VERSION ""

NS_ :

BS_:

BU_: VMCU VGGSECUSystem TECU TACHO RECU_Virt HMIIOM GSSA EMS EBS DACU CIOM BBM ATCU ACM

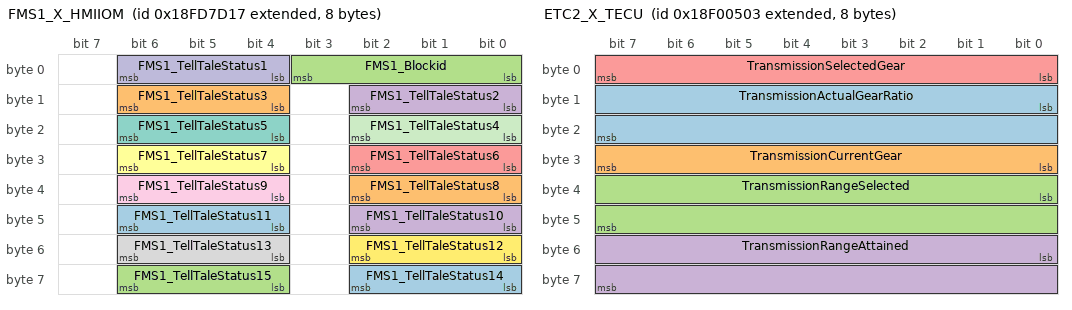
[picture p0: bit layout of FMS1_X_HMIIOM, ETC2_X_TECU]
BO_ 2566749463 FMS1_X_HMIIOM: 8 HMIIOM
 SG_ FMS1_TellTaleStatus11 : 44|3@1+ (1,0) [0|0] ""  CIOM
 SG_ FMS1_TellTaleStatus3 : 12|3@1+ (1,0) [0|0] ""  CIOM
 SG_ FMS1_Blockid : 0|4@1+ (1,0) [0|15] ""  CIOM
 SG_ FMS1_TellTaleStatus2 : 8|3@1+ (1,0) [0|0] ""  CIOM
 SG_ FMS1_TellTaleStatus6 : 24|3@1+ (1,0) [0|0] ""  CIOM
 SG_ FMS1_TellTaleStatus7 : 28|3@1+ (1,0) [0|0] ""  CIOM
 SG_ FMS1_TellTaleStatus5 : 20|3@1+ (1,0) [0|0] ""  CIOM
 SG_ FMS1_TellTaleStatus13 : 52|3@1+ (1,0) [0|0] ""  CIOM
 SG_ FMS1_TellTaleStatus9 : 36|3@1+ (1,0) [0|0] ""  CIOM
 SG_ FMS1_TellTaleStatus1 : 4|3@1+ (1,0) [0|0] ""  CIOM
 SG_ FMS1_TellTaleStatus4 : 16|3@1+ (1,0) [0|0] ""  CIOM
 SG_ FMS1_TellTaleStatus12 : 48|3@1+ (1,0) [0|0] ""  CIOM
 SG_ FMS1_TellTaleStatus14 : 56|3@1+ (1,0) [0|0] ""  CIOM
 SG_ FMS1_TellTaleStatus8 : 32|3@1+ (1,0) [0|0] ""  CIOM
 SG_ FMS1_TellTaleStatus15 : 60|3@1+ (1,0) [0|0] ""  CIOM
 SG_ FMS1_TellTaleStatus10 : 40|3@1+ (1,0) [0|0] ""  CIOM

BO_ 2364541955 ETC8_X_TCU: 8 Vector__XXX

BO_ 2566801923 ETC7_X_TECU: 8 TECU
 SG_ TransmissionRequestedGearFdbk : 24|8@1+ (1,-125) [-125|130] "GearValue"  HMIIOM
 SG_ TransmEngineCrankEnable2 : 12|2@1+ (1,0) [0|0] ""  VMCU

BO_ 2565866755 ETC2_X_TECU: 8 TECU
 SG_ TransmissionActualGearRatio : 8|16@1+ (0.001,0) [0|65.535] "NotApplicable"  BBM,DACU,EMS,VMCU
 SG_ TransmissionCurrentGear : 24|8@1+ (1,-125) [-125|130] "GearValue"  EMS,BBM,VMCU,EBS,HMIIOM
 SG_ TransmissionRangeSelected : 32|16@1+ (1,0) [0|0] ""  VMCU,HMIIOM,BBM
 SG_ TransmissionRangeAttained : 48|16@1+ (1,0) [0|0] ""  BBM,HMIIOM
 SG_ TransmissionSelectedGear : 0|8@1+ (1,-125) [-125|130] "GearValue"  EMS,BBM,HMIIOM,VMCU

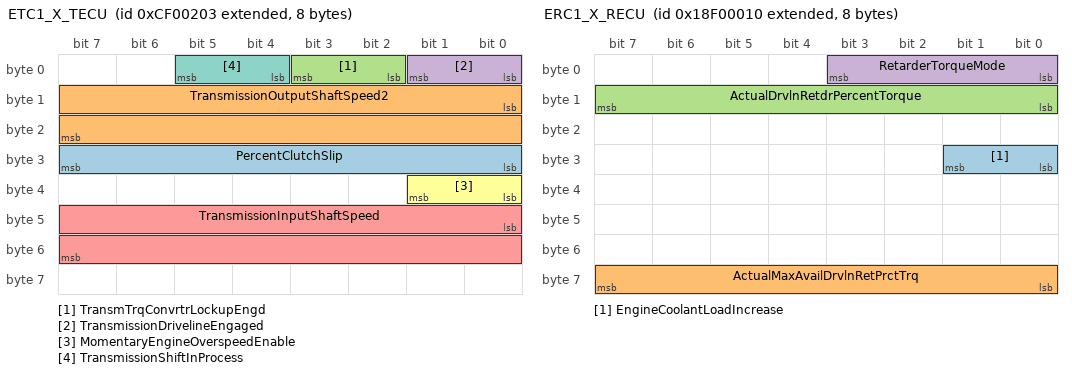
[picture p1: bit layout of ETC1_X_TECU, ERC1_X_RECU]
BO_ 2364539395 ETC1_X_TECU: 8 TECU
 SG_ PercentClutchSlip : 24|8@1+ (0.4,0) [0|102] "Percent"  EBS,EMS,VMCU,BBM
 SG_ TransmissionOutputShaftSpeed2 : 8|16@1+ (0.125,0) [0|8191.875] "rpm"  VMCU
 SG_ TransmTrqConvrtrLockupEngd : 2|2@1+ (1,0) [0|0] ""  EMS,BBM
 SG_ TransmissionDrivelineEngaged : 0|2@1+ (1,0) [0|0] ""  EMS,VMCU,BBM,DACU,EBS
 SG_ TransmissionInputShaftSpeed : 40|16@1+ (0.125,0) [0|8191.875] "rpm"  BBM,EBS
 SG_ MomentaryEngineOverspeedEnable : 32|2@1+ (1,0) [0|0] ""  BBM,EMS
 SG_ TransmissionShiftInProcess : 4|2@1+ (1,0) [0|0] ""  EMS,VMCU,EBS,BBM,DACU

BO_ 2566843904 ET1_X_EMS: 8 EMS
 SG_ EngineOilTemperature : 16|16@1+ (0.03125,-273) [-273|1774.96875] "DegreeC"  VGGSECUSystem,HMIIOM,BBM,TECU
 SG_ EngineCoolantTemp_stat : 0|8@1+ (1,-40) [-40|215] "DegreeC"  CIOM,HMIIOM,VMCU,TECU,VGGSECUSystem,ACM,BBM

BO_ 2558984359 ESR_EMS_VGGS: 8 VGGSECUSystem
 SG_ RequestedFuelTypeVGGS : 8|8@1+ (1,0) [0|0] ""  EMS

BO_ 2565865488 ERC1_X_RECU: 8 RECU_Virt
 SG_ EngineCoolantLoadIncrease : 24|2@1+ (1,0) [0|0] ""  EMS
 SG_ ActualMaxAvailDrvlnRetPrctTrq : 56|8@1+ (1,-125) [-125|130] "Percent"  EMS,EBS,VMCU,TECU
 SG_ ActualDrvlnRetdrPercentTorque : 8|8@1+ (1,-125) [-125|130] "Percent"  EMS,CIOM,VMCU,TECU,EBS,HMIIOM
 SG_ RetarderTorqueMode : 0|4@1+ (1,0) [0|0] ""  CIOM,HMIIOM,EMS

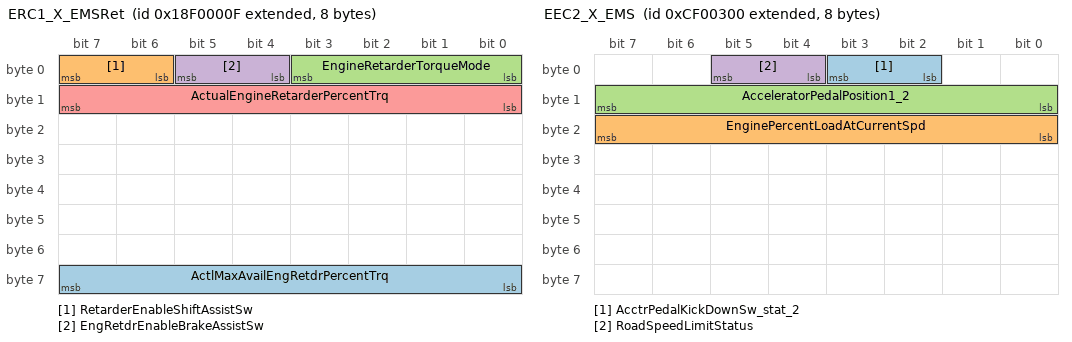
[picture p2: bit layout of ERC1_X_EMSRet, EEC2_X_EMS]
BO_ 2565865487 ERC1_X_EMSRet: 8 EMS
 SG_ ActlMaxAvailEngRetdrPercentTrq : 56|8@1+ (1,-125) [-125|130] "Percent"  VMCU,EBS
 SG_ RetarderEnableShiftAssistSw : 6|2@1+ (1,0) [0|0] ""  TECU
 SG_ EngineRetarderTorqueMode : 0|4@1+ (1,0) [0|0] ""  CIOM,HMIIOM
 SG_ EngRetdrEnableBrakeAssistSw : 4|2@1+ (1,0) [0|0] ""  TECU
 SG_ ActualEngineRetarderPercentTrq : 8|8@1+ (1,-125) [-125|130] "Percent"  RECU_Virt,CIOM,EBS,HMIIOM,VMCU,TECU,VGGSECUSystem

BO_ 2364541440 EGF1_X_EMS: 8 EMS
 SG_ EngineIntakeAirRate : 16|16@1+ (0.05,0) [0|3276.75] "Kg_per_h"  VMCU

BO_ 2566844160 EFLP1_X_EMS: 8 EMS
 SG_ EngineOilLevel : 16|8@1+ (0.4,0) [0|102] "Percent"  VGGSECUSystem,BBM,HMIIOM
 SG_ EngineOilPressure : 24|8@1+ (4,0) [0|1020] "kPa"  VMCU,HMIIOM,VGGSECUSystem,BBM

BO_ 2566840064 EEC3_X_EMS: 8 EMS
 SG_ NominalFrictionPercentTorque : 0|8@1+ (1,-125) [-125|130] "Percent"  VMCU,VGGSECUSystem,TECU,DACU,EBS,RECU_Virt

BO_ 2364539648 EEC2_X_EMS: 8 EMS
 SG_ AcctrPedalKickDownSw_stat_2 : 2|2@1+ (1,0) [0|0] ""  VGGSECUSystem
 SG_ EnginePercentLoadAtCurrentSpd : 16|8@1+ (1,0) [0|255] "Percent"  ACM,HMIIOM,BBM,CIOM,VMCU,TECU
 SG_ AcceleratorPedalPosition1_2 : 8|8@1+ (0.4,0) [0|102] "Percent"  VGGSECUSystem,TECU
 SG_ RoadSpeedLimitStatus : 4|2@1+ (1,0) [0|0] ""  TECU

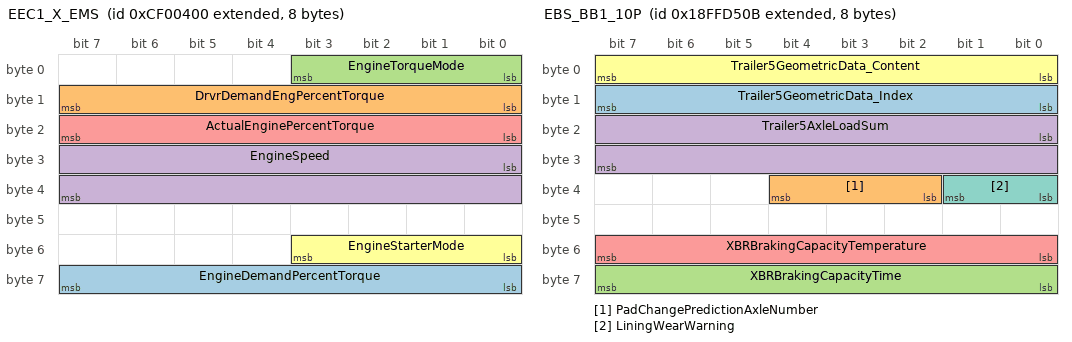
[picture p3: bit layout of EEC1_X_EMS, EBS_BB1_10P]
BO_ 2364539904 EEC1_X_EMS: 8 EMS
 SG_ EngineDemandPercentTorque : 56|8@1+ (1,-125) [-125|130] "Percent"  TECU,VMCU
 SG_ DrvrDemandEngPercentTorque : 8|8@1+ (1,-125) [-125|130] "Percent"  BBM,TECU,EBS,VMCU
 SG_ EngineTorqueMode : 0|4@1+ (1,0) [0|0] ""  TECU,VMCU,BBM,EBS,HMIIOM
 SG_ EngineSpeed : 24|16@1+ (0.125,0) [0|8191.875] "rpm"  BBM,DACU,HMIIOM,VMCU,VGGSECUSystem,EBS,ACM,TECU,CIOM
 SG_ ActualEnginePercentTorque : 16|8@1+ (1,-125) [-125|130] "Percent"  HMIIOM,VMCU,EBS,CIOM,TECU,BBM,DACU
 SG_ EngineStarterMode : 48|4@1+ (1,0) [0|0] ""  VMCU,BBM,HMIIOM

BO_ 2566767104 EEC14_X_EMS: 8 EMS
 SG_ FuelTypeEMS : 48|8@1+ (1,0) [0|0] ""  VGGSECUSystem

BO_ 2566841088 EC1_X_EMS: 39 EMS
 SG_ EngConf_EngSpeedAtHighIdle_P6 : 120|16@1+ (0.125,0) [0|8191.875] "rpm"  TECU
 SG_ EngConf_EngTorqueAt_P4 : 88|8@1+ (1,-125) [-125|130] "Percent"  TECU
 SG_ EngConf_EngMaxMomOvSpeed_P7 : 168|16@1+ (0.125,0) [0|8191.875] "rpm"  TECU
 SG_ EngConf_EngTorqueAt_P5 : 112|8@1+ (1,-125) [-125|130] "Percent"  TECU
 SG_ EngConf_EngSpeedAtIdle_P1 : 0|16@1+ (0.125,0) [0|8191.875] "rpm"  TECU
 SG_ EngineReferenceTorque : 152|16@1+ (1,0) [0|65535] "Nm"  TECU,RECU_Virt,VGGSECUSystem,DACU,EBS,VMCU
 SG_ EngConf_EngSpeedAt_P2 : 24|16@1+ (0.125,0) [0|8191.875] "rpm"  TECU
 SG_ EngConf_MaxMomOverrideTimeLim : 184|8@1+ (0.1,0) [0|25.5] "s"  TECU
 SG_ EngConf_EngSpeedAt_P5 : 96|16@1+ (0.125,0) [0|8191.875] "rpm"  TECU
 SG_ EngConf_EngTorqueAtIdle_P1 : 16|8@1+ (1,-125) [-125|130] "Percent"  TECU
 SG_ EngConf_EngSpeedAt_P4 : 72|16@1+ (0.125,0) [0|8191.875] "rpm"  TECU
 SG_ EngConf_EngSpeedAt_P3 : 48|16@1+ (0.125,0) [0|8191.875] "rpm"  TECU
 SG_ EngConf_EngTorqueAt_P3 : 64|8@1+ (1,-125) [-125|130] "Percent"  TECU
 SG_ EngConf_EngTorqueAt_P2 : 40|8@1+ (1,-125) [-125|130] "Percent"  TECU

BO_ 2566894859 EBS_BB1_15P: 17 EBS
 SG_ Trailer5VIN : 0|136@1+ (1,0) [0|0] ""  HMIIOM

BO_ 2566894603 EBS_BB1_14P: 17 EBS
 SG_ Trailer4VIN : 0|136@1+ (1,0) [0|0] ""  HMIIOM

BO_ 2566894347 EBS_BB1_13P: 17 EBS
 SG_ Trailer3VIN : 0|136@1+ (1,0) [0|0] ""  HMIIOM

BO_ 2566894091 EBS_BB1_12P: 17 EBS
 SG_ Trailer2VIN : 0|136@1+ (1,0) [0|0] ""  HMIIOM

BO_ 2566893835 EBS_BB1_11P: 17 EBS
 SG_ Trailer1VIN : 0|136@1+ (1,0) [0|0] ""  HMIIOM

BO_ 2566903051 EBS_BB1_10P: 8 EBS
 SG_ Trailer5GeometricData_Index : 8|8@1+ (1,0) [0|0] ""  HMIIOM
 SG_ PadChangePredictionAxleNumber : 34|3@1+ (1,0) [0|0] ""  VMCU
 SG_ XBRBrakingCapacityTime : 56|8@1+ (1,0) [0|255] "s"  EMS,TECU,DACU
 SG_ Trailer5AxleLoadSum : 16|16@1+ (2,0) [0|131070] "kg"  HMIIOM
 SG_ XBRBrakingCapacityTemperature : 48|8@1+ (0.4,0) [0|102] "Percent"  TECU,DACU,EMS
 SG_ Trailer5GeometricData_Content : 0|8@1+ (1,0) [0|255] ""  HMIIOM
 SG_ LiningWearWarning : 32|2@1+ (1,0) [0|0] ""  VGGSECUSystem,HMIIOM

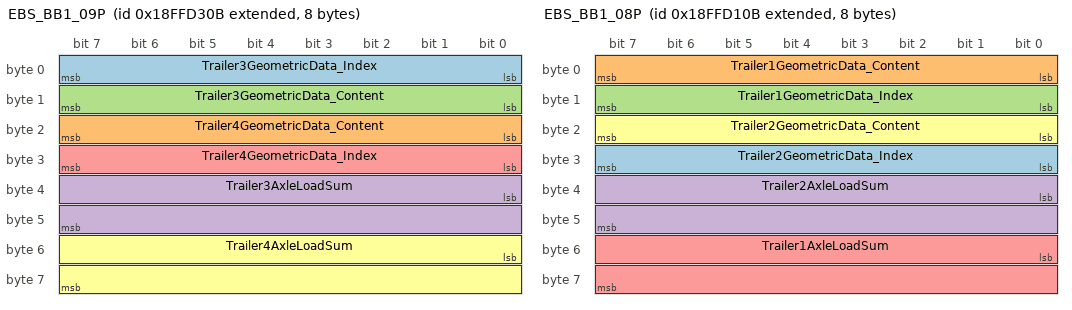
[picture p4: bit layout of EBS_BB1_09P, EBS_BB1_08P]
BO_ 2566902539 EBS_BB1_09P: 8 EBS
 SG_ Trailer3GeometricData_Index : 0|8@1+ (1,0) [0|0] ""  HMIIOM
 SG_ Trailer4GeometricData_Content : 16|8@1+ (1,0) [0|255] ""  HMIIOM
 SG_ Trailer3GeometricData_Content : 8|8@1+ (1,0) [0|255] ""  HMIIOM
 SG_ Trailer3AxleLoadSum : 32|16@1+ (2,0) [0|131070] "kg"  HMIIOM,TECU
 SG_ Trailer4GeometricData_Index : 24|8@1+ (1,0) [0|0] ""  HMIIOM
 SG_ Trailer4AxleLoadSum : 48|16@1+ (2,0) [0|131070] "kg"  TECU,HMIIOM

BO_ 2566902027 EBS_BB1_08P: 8 EBS
 SG_ Trailer2GeometricData_Index : 24|8@1+ (1,0) [0|0] ""  HMIIOM
 SG_ Trailer1GeometricData_Content : 0|8@1+ (1,0) [0|255] ""  HMIIOM
 SG_ Trailer1GeometricData_Index : 8|8@1+ (1,0) [0|0] ""  HMIIOM
 SG_ Trailer2AxleLoadSum : 32|16@1+ (2,0) [0|131070] "kg"  TECU,HMIIOM
 SG_ Trailer1AxleLoadSum : 48|16@1+ (2,0) [0|131070] "kg"  HMIIOM,TECU
 SG_ Trailer2GeometricData_Content : 16|8@1+ (1,0) [0|255] ""  HMIIOM

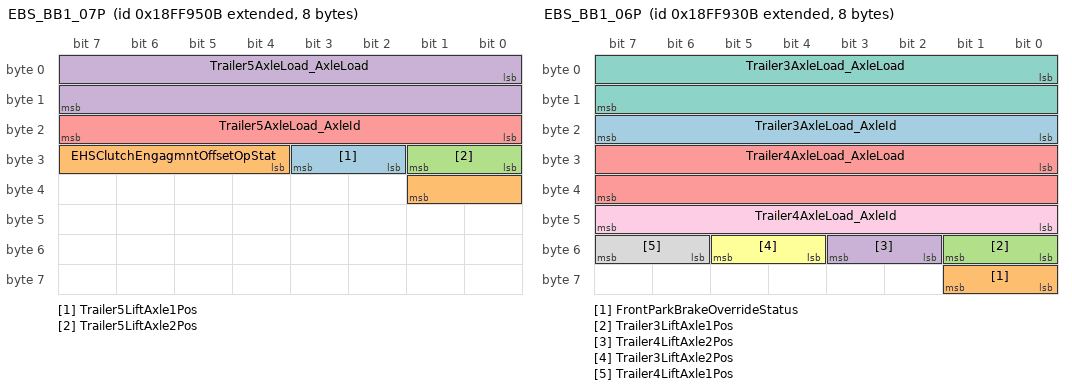
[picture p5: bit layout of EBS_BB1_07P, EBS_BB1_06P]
BO_ 2566886667 EBS_BB1_07P: 8 EBS
 SG_ Trailer5LiftAxle1Pos : 26|2@1+ (1,0) [0|0] ""  BBM,HMIIOM
 SG_ EHSClutchEngagmntOffsetOpStat : 28|6@1+ (1,-30) [-30|33] "Step"  HMIIOM
 SG_ Trailer5LiftAxle2Pos : 24|2@1+ (1,0) [0|0] ""  BBM,HMIIOM
 SG_ Trailer5AxleLoad_AxleLoad : 0|16@1+ (0.5,0) [0|32767.5] "kg"  BBM,HMIIOM
 SG_ Trailer5AxleLoad_AxleId : 16|8@1+ (1,0) [0|255] "NotApplicable"  BBM,HMIIOM

BO_ 2566886155 EBS_BB1_06P: 8 EBS
 SG_ Trailer3AxleLoad_AxleId : 16|8@1+ (1,0) [0|255] "NotApplicable"  BBM,HMIIOM
 SG_ FrontParkBrakeOverrideStatus : 56|2@1+ (1,0) [0|0] ""  HMIIOM
 SG_ Trailer3LiftAxle1Pos : 48|2@1+ (1,0) [0|0] ""  BBM,HMIIOM
 SG_ Trailer4LiftAxle2Pos : 50|2@1+ (1,0) [0|0] ""  BBM,HMIIOM
 SG_ Trailer4AxleLoad_AxleLoad : 24|16@1+ (0.5,0) [0|32767.5] "kg"  BBM,HMIIOM
 SG_ Trailer3LiftAxle2Pos : 52|2@1+ (1,0) [0|0] ""  BBM,HMIIOM
 SG_ Trailer3AxleLoad_AxleLoad : 0|16@1+ (0.5,0) [0|32767.5] "kg"  BBM,HMIIOM
 SG_ Trailer4LiftAxle1Pos : 54|2@1+ (1,0) [0|0] ""  HMIIOM,BBM
 SG_ Trailer4AxleLoad_AxleId : 40|8@1+ (1,0) [0|255] "NotApplicable"  HMIIOM,BBM

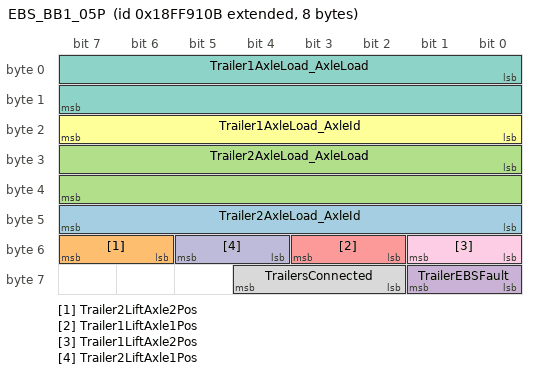
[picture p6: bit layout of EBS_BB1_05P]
BO_ 2566885643 EBS_BB1_05P: 8 EBS
 SG_ Trailer2AxleLoad_AxleId : 40|8@1+ (1,0) [0|255] "NotApplicable"  BBM,HMIIOM
 SG_ Trailer2LiftAxle2Pos : 54|2@1+ (1,0) [0|0] ""  HMIIOM,BBM
 SG_ Trailer2AxleLoad_AxleLoad : 24|16@1+ (0.5,0) [0|32767.5] "kg"  HMIIOM,BBM
 SG_ TrailerEBSFault : 56|2@1+ (1,0) [0|0] ""  VGGSECUSystem,HMIIOM
 SG_ Trailer1LiftAxle1Pos : 50|2@1+ (1,0) [0|0] ""  BBM,HMIIOM
 SG_ Trailer1AxleLoad_AxleId : 16|8@1+ (1,0) [0|255] "NotApplicable"  HMIIOM,BBM
 SG_ Trailer1AxleLoad_AxleLoad : 0|16@1+ (0.5,0) [0|32767.5] "kg"  BBM,HMIIOM
 SG_ TrailersConnected : 58|3@1+ (1,0) [0|7] "Count"  VGGSECUSystem,HMIIOM,CIOM,TECU
 SG_ Trailer1LiftAxle2Pos : 48|2@1+ (1,0) [0|0] ""  HMIIOM,BBM
 SG_ Trailer2LiftAxle1Pos : 52|2@1+ (1,0) [0|0] ""  HMIIOM,BBM

BO_ 2566906635 EBS_BB1_04P: 8 EBS
 SG_ PredictedMileageOfNextPadChg : 0|32@1+ (1,0) [0|4294967295] "km"  HMIIOM,VMCU
 SG_ PadChgPredictionLastPadChg : 32|32@1+ (1,0) [0|4294967295] "km"  VMCU

BO_ 2499761675 EBS_BB1_02P: 8 EBS
 SG_ BadBrakeBalanceWarning : 12|2@1+ (1,0) [0|0] ""  HMIIOM
 SG_ HSAAvailability : 22|2@1+ (1,0) [0|0] ""  BBM,TECU
 SG_ DTCActive : 6|2@1+ (1,0) [0|0] ""  HMIIOM
 SG_ StretchBrake_Stat : 58|3@1+ (1,0) [0|0] ""  HMIIOM,VMCU
 SG_ TrcnCtrlSlipperyRoadWarning : 4|2@1+ (1,0) [0|0] ""  BBM,HMIIOM
 SG_ RearAxleDiffLockActvnFuncReq : 10|2@1+ (1,0) [0|0] ""  VMCU
 SG_ BrakeTempWarningLevel : 24|8@1+ (1,0) [0|255] "Percent"  VMCU,DACU,TECU,EMS
 SG_ RollerBenchModeStatus : 0|2@1+ (1,0) [0|0] ""  DACU,HMIIOM,VMCU,VGGSECUSystem
 SG_ BrakeAssistStatus : 8|2@1+ (1,0) [0|0] ""  VMCU
 SG_ LongitudinalAcceleration : 32|16@1+ (0.00048828125,-15.687) [-15.687|16.31251171875] "m_per_s_squared"  BBM
 SG_ TractionFunctionSelected : 53|3@1+ (1,0) [0|0] ""  HMIIOM
 SG_ PoorBrakePerformanceWarning : 14|2@1+ (1,0) [0|0] ""  HMIIOM
 SG_ VDCActive : 56|2@1+ (1,0) [0|0] ""  VMCU,HMIIOM
 SG_ ABSInhibitionStatus : 16|2@1+ (1,0) [0|0] ""  VGGSECUSystem,TECU,CIOM,VMCU,HMIIOM
 SG_ ABSManAutoInhibitionStat : 61|3@1+ (1,0) [0|0] ""  HMIIOM,VGGSECUSystem
 SG_ RearAxleSteeringFunctionStatus : 50|3@1+ (1,0) [0|0] ""  DACU,CIOM
 SG_ AutoRearAxleDiffLockFnc_stat : 48|2@1+ (1,0) [0|0] ""  HMIIOM
 SG_ RearAxleDiffLockActvnFuncReq_UB : 2|1@1+ (1,0) [0|0] ""  VMCU
 SG_ WheelBrakeWarning : 20|2@1+ (1,0) [0|0] ""  HMIIOM

CM_ BO_ 2566749463 "PGN 64893 FMS Telltale status";
CM_ SG_ 2566749463 FMS1_Blockid "15: Don't care";
CM_ BO_ 2364541955 "PGN61452 Electronic Transmission Controller #8";
CM_ BO_ 2566801923 "PGN 65098 Electronic Transmission Controller 7";
CM_ BO_ 2565866755 "PGN 61445 Electronic Transmission Controller 2";
CM_ SG_ 2565866755 TransmissionActualGearRatio "65024 - 65279 Error ; 65280 - 65535 Not available";
CM_ SG_ 2565866755 TransmissionCurrentGear "254 Error ; 255 Not available";
CM_ SG_ 2565866755 TransmissionSelectedGear "254 Error ; 255 Not available";
CM_ BO_ 2364539395 "PGN 61442 Electronic Transmission Controller 1";
CM_ SG_ 2364539395 PercentClutchSlip "254 Error ; 255 Not available";
CM_ SG_ 2364539395 TransmissionInputShaftSpeed "65024 - 65279 Error ; 65280 - 65535 Not available";
CM_ BO_ 2566843904 "PGN 65262 Engine Temperature 1";
CM_ SG_ 2566843904 EngineOilTemperature "65024 - 65279 Error ; 65280 - 65535 Not available";
CM_ SG_ 2566843904 EngineCoolantTemp_stat "254 Error ; 255 Not available";
CM_ BO_ 2558984359 "PGN 34560 Engine State Requests";
CM_ BO_ 2565865488 "PGN 61440 Electronic Retarder Controller 1 from RECU";
CM_ SG_ 2565865488 ActualMaxAvailDrvlnRetPrctTrq "254 Error ; 255 Not available";
CM_ SG_ 2565865488 ActualDrvlnRetdrPercentTorque "254 Error ; 255 Not available";
CM_ BO_ 2565865487 "PGN 61440 Electronic Retarder Controller 1";
CM_ SG_ 2565865487 ActlMaxAvailEngRetdrPercentTrq "254 Error ; 255 Not available";
CM_ SG_ 2565865487 ActualEngineRetarderPercentTrq "254 Error ; 255 Not available";
CM_ BO_ 2364541440 "PGN 61450 Flow rates of Air and mixed gasses into the engine cylinders.
Note: SAE recommended rate 50ms, but 500ms set due to current usage only for logging.";
CM_ BO_ 2566844160 "PGN 65263 Engine Fluid Level/Pressure 1";
CM_ SG_ 2566844160 EngineOilLevel "254 Error ; 255 Not available";
CM_ SG_ 2566844160 EngineOilPressure "254 Error ; 255 Not available";
CM_ BO_ 2566840064 "PGN 65247 Electronic Engine Controller 3";
CM_ SG_ 2566840064 NominalFrictionPercentTorque "254 Error ; 255 Not available";
CM_ BO_ 2364539648 "PGN 61443 Electronic Engine Controller 2";
CM_ SG_ 2364539648 EnginePercentLoadAtCurrentSpd "254 Error ; 255 Not available";
CM_ BO_ 2364539904 "PGN 61444 Electronic Engine Controller 1";
CM_ SG_ 2364539904 DrvrDemandEngPercentTorque "254 Error ; 255 Not available";
CM_ SG_ 2364539904 EngineSpeed "65024 - 65279 Error ; 65280 - 65535 Not available";
CM_ SG_ 2364539904 ActualEnginePercentTorque "254 Error ; 255 Not available";
CM_ BO_ 2566767104 "PGN 64962 Electronic Engine Controller 14";
CM_ BO_ 2566841088 "PGN 65251 Engine Configuration 1";
CM_ SG_ 2566841088 EngConf_EngSpeedAtHighIdle_P6 "65024 - 65279 Error ; 65280 - 65535 Not available";
CM_ SG_ 2566841088 EngConf_EngTorqueAt_P4 "254 Error ; 255 Not available";
CM_ SG_ 2566841088 EngConf_EngMaxMomOvSpeed_P7 "65024 - 65279 Error ; 65280 - 65535 Not available";
CM_ SG_ 2566841088 EngConf_EngTorqueAt_P5 "254 Error ; 255 Not available";
CM_ SG_ 2566841088 EngConf_EngSpeedAtIdle_P1 "65024 - 65279 Error ; 65280 - 65535 Not available";
CM_ SG_ 2566841088 EngineReferenceTorque "65024 - 65279 Error ; 65280 - 65535 Not available";
CM_ SG_ 2566841088 EngConf_EngSpeedAt_P2 "65024 - 65279 Error ; 65280 - 65535 Not available";
CM_ SG_ 2566841088 EngConf_MaxMomOverrideTimeLim "254 Error ; 255 Not available";
CM_ SG_ 2566841088 EngConf_EngSpeedAt_P5 "65024 - 65279 Error ; 65280 - 65535 Not available";
CM_ SG_ 2566841088 EngConf_EngTorqueAtIdle_P1 "254 Error ; 255 Not available";
CM_ SG_ 2566841088 EngConf_EngSpeedAt_P4 "65024 - 65279 Error ; 65280 - 65535 Not available";
CM_ SG_ 2566841088 EngConf_EngSpeedAt_P3 "65024 - 65279 Error ; 65280 - 65535 Not available";
CM_ SG_ 2566841088 EngConf_EngTorqueAt_P3 "254 Error ; 255 Not available";
CM_ SG_ 2566841088 EngConf_EngTorqueAt_P2 "254 Error ; 255 Not available";
CM_ SG_ 2566903051 Trailer5AxleLoadSum "65024 - 65279 Error ; 65280 - 65535 Not Available";
CM_ SG_ 2566903051 Trailer5GeometricData_Content "254 Error ; 255 Not Available";
CM_ SG_ 2566902539 Trailer4GeometricData_Content "254 Error ; 255 Not Available";
CM_ SG_ 2566902539 Trailer3GeometricData_Content "254 Error ; 255 Not Available";
CM_ SG_ 2566902539 Trailer3AxleLoadSum "65024 - 65279 Error ; 65280 - 65535 Not Available";
CM_ SG_ 2566902539 Trailer4AxleLoadSum "65024 - 65279 Error ; 65280 - 65535 Not Available";
CM_ SG_ 2566902027 Trailer1GeometricData_Content "254 Error ; 255 Not Available";
CM_ SG_ 2566902027 Trailer2AxleLoadSum "65024 - 65279 Error ; 65280 - 65535 Not Available";
CM_ SG_ 2566902027 Trailer1AxleLoadSum "65024 - 65279 Error ; 65280 - 65535 Not Available";
CM_ SG_ 2566902027 Trailer2GeometricData_Content "254 Error ; 255 Not Available";
CM_ SG_ 2566886667 Trailer5AxleLoad_AxleLoad "65024 - 65279 Error ; 65280 - 65535 Not available";
CM_ SG_ 2566886155 Trailer4AxleLoad_AxleLoad "65024 - 65279 Error ; 65280 - 65535 Not available";
CM_ SG_ 2566886155 Trailer3AxleLoad_AxleLoad "65024 - 65279 Error ; 65280 - 65535 Not available";
CM_ SG_ 2566885643 Trailer2AxleLoad_AxleLoad "65024 - 65279 Error ; 65280 - 65535 Not available";
CM_ SG_ 2566885643 Trailer1AxleLoad_AxleLoad "65024 - 65279 Error ; 65280 - 65535 Not available";
CM_ SG_ 2566885643 TrailersConnected "6 Error ; 7 Not available";
CM_ SG_ 2566906635 PredictedMileageOfNextPadChg "4261412864 - 4278190079 Error ; 4278190080 - 4294967295 Not available";
CM_ SG_ 2566906635 PadChgPredictionLastPadChg "4261412864 - 4278190079 Error ; 4278190080 - 4294967295 Not available";
CM_ SG_ 2499761675 BrakeTempWarningLevel "254 Error ; 255 Not available";
CM_ SG_ 2499761675 LongitudinalAcceleration "65024 - 65279 Error ; 65280 - 65535 Not available";
BA_DEF_ BO_  "GenMsgStartDelayTime" INT 0 0;
BA_DEF_ BO_  "GenMsgDelayTime" INT 0 0;
BA_DEF_ BO_  "GenMsgNrOfRepetition" INT 0 0;
BA_DEF_ BO_  "GenMsgCycleTimeFast" INT 0 0;
BA_DEF_ BO_  "GenMsgCycleTime" INT 0 0;
BA_DEF_ BO_  "GenMsgSendType" ENUM  "Cyclic","NotUsed","NotUsed","NotUsed","NotUsed","NotUsed","NotUsed","IfActive","NoMsgSendType","NotUsed";
BA_DEF_ SG_  "GenSigStartValue" INT 0 0;
BA_DEF_ SG_  "GenSigCycleTimeActive" INT 0 0;
BA_DEF_ SG_  "GenSigCycleTime" INT 0 0;
BA_DEF_ SG_  "GenSigSendType" ENUM  "Cyclic","OnWrite","OnWriteWithRepetition","OnChange","OnChangeWithRepetition","IfActive","IfActiveWithRepetition","NoSigSendType","NotUsed","NotUsed","NotUsed","NotUsed","NotUsed";
BA_DEF_ BO_  "VFrameFormat" ENUM  "StandardCAN","ExtendedCAN","reserved","J1939PG";
BA_DEF_ BO_  "TpJ1939VarDlc" ENUM  "No","Yes";
BA_DEF_ SG_  "SigType" ENUM  "Default","Range","RangeSigned","ASCII","Discrete","Control","ReferencePGN","DTC","StringDelimiter","StringLength","StringLengthControl";
BA_DEF_ SG_  "SeToolVersion_SIGNAL" STRING ;
BA_DEF_ SG_  "SeToolUniqueID_SIGNAL" STRING ;
BA_DEF_ SG_  "SeToolOwnerSigGroup_SIGNAL" STRING ;
BA_DEF_ SG_  "SeToolOwnerSigGroupID_SIGNAL" STRING ;
BA_DEF_ SG_  "SeToolName_SIGNAL" STRING ;
BA_DEF_ SG_  "SeToolItemID_SIGNAL" STRING ;
BA_DEF_ SG_  "SeToolAncestorID_SIGNAL" STRING ;
BA_DEF_ SG_  "SPN" INT 0 524287;
BA_DEF_ SG_  "Platform_VMCU1_Sig" ENUM  "No","Yes";
BA_DEF_ SG_  "Platform_FactoryIf_Sig" ENUM  "No","Yes";
BA_DEF_ SG_  "NeedsUpdateBit" ENUM  "No","Yes";
BA_DEF_ SG_  "GenSigMaxLatency" INT 0 65535;
BA_DEF_ SG_  "GenSigILSupport" ENUM  "Yes","No";
BA_DEF_ BO_  "GenMsgRequestable" INT 0 1;
BA_DEF_ BO_  "GenMsgILSupport" ENUM  "No","Yes";
BA_DEF_ BO_  "DiagUUDTResponse" ENUM  "No","Yes";
BA_DEF_ BO_  "DiagState" ENUM  "No","Yes";
BA_DEF_ BO_  "DiagResponse" ENUM  "No","Yes";
BA_DEF_ BO_  "DiagRequest" ENUM  "No","Yes";
BA_DEF_ BO_  "DiagConnection" HEX 0 65535;
BA_DEF_ BO_  "CanTpFcFrameId" HEX 0 2147483647;
BA_DEF_ BO_  "CanTpBs" INT 0 255;
BA_DEF_ SG_  "SystemSignalLongSymbol" STRING ;
BA_DEF_REL_ BU_SG_REL_  "GenSigTimeoutTime" INT 0 65535;
BA_DEF_REL_ BU_SG_REL_  "GenSigFirstTimeoutTime" INT 0 65535;
BA_DEF_DEF_  "GenMsgStartDelayTime" 0;
BA_DEF_DEF_  "GenMsgDelayTime" 0;
BA_DEF_DEF_  "GenMsgNrOfRepetition" 0;
BA_DEF_DEF_  "GenMsgCycleTimeFast" 0;
BA_DEF_DEF_  "GenMsgCycleTime" 0;
BA_DEF_DEF_  "GenMsgSendType" "Cyclic";
BA_DEF_DEF_  "GenSigStartValue" 0;
BA_DEF_DEF_  "GenSigCycleTimeActive" 0;
BA_DEF_DEF_  "GenSigCycleTime" 0;
BA_DEF_DEF_  "GenSigSendType" "Cyclic";
BA_DEF_DEF_  "VFrameFormat" "ExtendedCAN";
BA_DEF_DEF_  "TpJ1939VarDlc" "No";
BA_DEF_DEF_  "SigType" "Default";
BA_DEF_DEF_  "SeToolVersion_SIGNAL" "";
BA_DEF_DEF_  "SeToolUniqueID_SIGNAL" "";
BA_DEF_DEF_  "SeToolOwnerSigGroup_SIGNAL" "";
BA_DEF_DEF_  "SeToolOwnerSigGroupID_SIGNAL" "";
BA_DEF_DEF_  "SeToolName_SIGNAL" "";
BA_DEF_DEF_  "SeToolItemID_SIGNAL" "";
BA_DEF_DEF_  "SeToolAncestorID_SIGNAL" "";
BA_DEF_DEF_  "SPN" 0;
BA_DEF_DEF_  "Platform_VMCU1_Sig" "No";
BA_DEF_DEF_  "Platform_FactoryIf_Sig" "No";
BA_DEF_DEF_  "NeedsUpdateBit" "No";
BA_DEF_DEF_  "GenSigMaxLatency" 0;
BA_DEF_DEF_  "GenSigILSupport" "Yes";
BA_DEF_DEF_  "GenMsgRequestable" 1;
BA_DEF_DEF_  "GenMsgILSupport" "Yes";
BA_DEF_DEF_  "DiagUUDTResponse" "No";
BA_DEF_DEF_  "DiagState" "No";
BA_DEF_DEF_  "DiagResponse" "No";
BA_DEF_DEF_  "DiagRequest" "No";
BA_DEF_DEF_  "DiagConnection" 0;
BA_DEF_DEF_  "CanTpFcFrameId" 2147483647;
BA_DEF_DEF_  "CanTpBs" 255;
BA_DEF_DEF_REL_ "GenSigTimeoutTime" 0;
BA_DEF_DEF_REL_ "GenSigFirstTimeoutTime" 0;
BA_DEF_DEF_  "SystemSignalLongSymbol" "";
BA_ "GenMsgCycleTime" BO_ 2566749463 1000;
BA_ "GenMsgStartDelayTime" BO_ 2566749463 10;
BA_ "VFrameFormat" BO_ 2566749463 3;
BA_ "VFrameFormat" BO_ 2364541955 3;
BA_ "GenMsgCycleTime" BO_ 2566801923 100;
BA_ "GenMsgStartDelayTime" BO_ 2566801923 20;
BA_ "VFrameFormat" BO_ 2566801923 3;
BA_ "GenMsgCycleTime" BO_ 2565866755 100;
BA_ "GenMsgStartDelayTime" BO_ 2565866755 15;
BA_ "VFrameFormat" BO_ 2565866755 3;
BA_ "GenMsgCycleTime" BO_ 2364539395 10;
BA_ "VFrameFormat" BO_ 2364539395 3;
BA_ "GenMsgCycleTime" BO_ 2566843904 1000;
BA_ "GenMsgStartDelayTime" BO_ 2566843904 430;
BA_ "VFrameFormat" BO_ 2566843904 3;
BA_ "GenMsgCycleTime" BO_ 2558984359 1000;
BA_ "GenMsgDelayTime" BO_ 2558984359 100;
BA_ "VFrameFormat" BO_ 2558984359 3;
BA_ "GenMsgCycleTime" BO_ 2565865488 100;
BA_ "VFrameFormat" BO_ 2565865488 3;
BA_ "GenMsgCycleTime" BO_ 2565865487 100;
BA_ "GenMsgStartDelayTime" BO_ 2565865487 10;
BA_ "VFrameFormat" BO_ 2565865487 3;
BA_ "GenMsgCycleTime" BO_ 2364541440 500;
BA_ "GenMsgStartDelayTime" BO_ 2364541440 25;
BA_ "VFrameFormat" BO_ 2364541440 3;
BA_ "GenMsgCycleTime" BO_ 2566844160 500;
BA_ "GenMsgStartDelayTime" BO_ 2566844160 125;
BA_ "VFrameFormat" BO_ 2566844160 3;
BA_ "GenMsgCycleTime" BO_ 2566840064 250;
BA_ "GenMsgStartDelayTime" BO_ 2566840064 20;
BA_ "VFrameFormat" BO_ 2566840064 3;
BA_ "GenMsgCycleTime" BO_ 2364539648 50;
BA_ "VFrameFormat" BO_ 2364539648 3;
BA_ "GenMsgCycleTime" BO_ 2364539904 20;
BA_ "GenMsgStartDelayTime" BO_ 2364539904 5;
BA_ "VFrameFormat" BO_ 2364539904 3;
BA_ "GenMsgCycleTime" BO_ 2566767104 5000;
BA_ "GenMsgDelayTime" BO_ 2566767104 100;
BA_ "GenMsgStartDelayTime" BO_ 2566767104 70;
BA_ "VFrameFormat" BO_ 2566767104 3;
BA_ "GenMsgCycleTime" BO_ 2566841088 5000;
BA_ "GenMsgDelayTime" BO_ 2566841088 500;
BA_ "GenMsgStartDelayTime" BO_ 2566841088 140;
BA_ "VFrameFormat" BO_ 2566841088 3;
BA_ "GenMsgCycleTime" BO_ 2566894859 10000;
BA_ "GenMsgStartDelayTime" BO_ 2566894859 2040;
BA_ "VFrameFormat" BO_ 2566894859 3;
BA_ "GenMsgCycleTime" BO_ 2566894603 10000;
BA_ "GenMsgStartDelayTime" BO_ 2566894603 1530;
BA_ "VFrameFormat" BO_ 2566894603 3;
BA_ "GenMsgCycleTime" BO_ 2566894347 10000;
BA_ "GenMsgStartDelayTime" BO_ 2566894347 1020;
BA_ "VFrameFormat" BO_ 2566894347 3;
BA_ "GenMsgCycleTime" BO_ 2566894091 10000;
BA_ "GenMsgStartDelayTime" BO_ 2566894091 510;
BA_ "VFrameFormat" BO_ 2566894091 3;
BA_ "GenMsgCycleTime" BO_ 2566893835 10000;
BA_ "GenMsgStartDelayTime" BO_ 2566893835 100;
BA_ "VFrameFormat" BO_ 2566893835 3;
BA_ "GenMsgCycleTime" BO_ 2566903051 1000;
BA_ "GenMsgStartDelayTime" BO_ 2566903051 360;
BA_ "VFrameFormat" BO_ 2566903051 3;
BA_ "GenMsgCycleTime" BO_ 2566902539 1000;
BA_ "GenMsgStartDelayTime" BO_ 2566902539 265;
BA_ "VFrameFormat" BO_ 2566902539 3;
BA_ "GenMsgCycleTime" BO_ 2566902027 1000;
BA_ "GenMsgStartDelayTime" BO_ 2566902027 170;
BA_ "VFrameFormat" BO_ 2566902027 3;
BA_ "GenMsgCycleTime" BO_ 2566886667 100;
BA_ "GenMsgStartDelayTime" BO_ 2566886667 50;
BA_ "VFrameFormat" BO_ 2566886667 3;
BA_ "GenMsgCycleTime" BO_ 2566886155 100;
BA_ "GenMsgStartDelayTime" BO_ 2566886155 45;
BA_ "VFrameFormat" BO_ 2566886155 3;
BA_ "GenMsgCycleTime" BO_ 2566885643 100;
BA_ "GenMsgStartDelayTime" BO_ 2566885643 40;
BA_ "VFrameFormat" BO_ 2566885643 3;
BA_ "GenMsgCycleTime" BO_ 2566906635 2000;
BA_ "GenMsgStartDelayTime" BO_ 2566906635 555;
BA_ "VFrameFormat" BO_ 2566906635 3;
BA_ "GenMsgCycleTime" BO_ 2499761675 40;
BA_ "GenMsgStartDelayTime" BO_ 2499761675 10;
BA_ "VFrameFormat" BO_ 2499761675 3;
BA_ "GenSigCycleTime" SG_ 2566749463 FMS1_TellTaleStatus11 100;
BA_ "GenSigCycleTimeActive" SG_ 2566749463 FMS1_TellTaleStatus11 100;
BA_ "GenSigStartValue" SG_ 2566749463 FMS1_TellTaleStatus11 7;
BA_ "GenSigCycleTime" SG_ 2566749463 FMS1_TellTaleStatus3 100;
BA_ "GenSigCycleTimeActive" SG_ 2566749463 FMS1_TellTaleStatus3 100;
BA_ "GenSigStartValue" SG_ 2566749463 FMS1_TellTaleStatus3 7;
BA_ "GenSigCycleTime" SG_ 2566749463 FMS1_Blockid 100;
BA_ "GenSigCycleTimeActive" SG_ 2566749463 FMS1_Blockid 100;
BA_ "GenSigStartValue" SG_ 2566749463 FMS1_Blockid 15;
BA_ "GenSigCycleTime" SG_ 2566749463 FMS1_TellTaleStatus2 100;
BA_ "GenSigCycleTimeActive" SG_ 2566749463 FMS1_TellTaleStatus2 100;
BA_ "GenSigStartValue" SG_ 2566749463 FMS1_TellTaleStatus2 7;
BA_ "GenSigCycleTime" SG_ 2566749463 FMS1_TellTaleStatus6 100;
BA_ "GenSigCycleTimeActive" SG_ 2566749463 FMS1_TellTaleStatus6 100;
BA_ "GenSigStartValue" SG_ 2566749463 FMS1_TellTaleStatus6 7;
BA_ "GenSigCycleTime" SG_ 2566749463 FMS1_TellTaleStatus7 100;
BA_ "GenSigCycleTimeActive" SG_ 2566749463 FMS1_TellTaleStatus7 100;
BA_ "GenSigStartValue" SG_ 2566749463 FMS1_TellTaleStatus7 7;
BA_ "GenSigCycleTime" SG_ 2566749463 FMS1_TellTaleStatus5 100;
BA_ "GenSigCycleTimeActive" SG_ 2566749463 FMS1_TellTaleStatus5 100;
BA_ "GenSigStartValue" SG_ 2566749463 FMS1_TellTaleStatus5 7;
BA_ "GenSigCycleTime" SG_ 2566749463 FMS1_TellTaleStatus13 100;
BA_ "GenSigCycleTimeActive" SG_ 2566749463 FMS1_TellTaleStatus13 100;
BA_ "GenSigStartValue" SG_ 2566749463 FMS1_TellTaleStatus13 7;
BA_ "GenSigCycleTime" SG_ 2566749463 FMS1_TellTaleStatus9 100;
BA_ "GenSigCycleTimeActive" SG_ 2566749463 FMS1_TellTaleStatus9 100;
BA_ "GenSigStartValue" SG_ 2566749463 FMS1_TellTaleStatus9 7;
BA_ "GenSigCycleTime" SG_ 2566749463 FMS1_TellTaleStatus1 100;
BA_ "GenSigCycleTimeActive" SG_ 2566749463 FMS1_TellTaleStatus1 100;
BA_ "GenSigStartValue" SG_ 2566749463 FMS1_TellTaleStatus1 7;
BA_ "GenSigCycleTime" SG_ 2566749463 FMS1_TellTaleStatus4 100;
BA_ "GenSigCycleTimeActive" SG_ 2566749463 FMS1_TellTaleStatus4 100;
BA_ "GenSigStartValue" SG_ 2566749463 FMS1_TellTaleStatus4 7;
BA_ "GenSigCycleTime" SG_ 2566749463 FMS1_TellTaleStatus12 100;
BA_ "GenSigCycleTimeActive" SG_ 2566749463 FMS1_TellTaleStatus12 100;
BA_ "GenSigStartValue" SG_ 2566749463 FMS1_TellTaleStatus12 7;
BA_ "GenSigCycleTime" SG_ 2566749463 FMS1_TellTaleStatus14 100;
BA_ "GenSigCycleTimeActive" SG_ 2566749463 FMS1_TellTaleStatus14 100;
BA_ "GenSigStartValue" SG_ 2566749463 FMS1_TellTaleStatus14 7;
BA_ "GenSigCycleTime" SG_ 2566749463 FMS1_TellTaleStatus8 100;
BA_ "GenSigCycleTimeActive" SG_ 2566749463 FMS1_TellTaleStatus8 100;
BA_ "GenSigStartValue" SG_ 2566749463 FMS1_TellTaleStatus8 7;
BA_ "GenSigCycleTime" SG_ 2566749463 FMS1_TellTaleStatus15 100;
BA_ "GenSigCycleTimeActive" SG_ 2566749463 FMS1_TellTaleStatus15 100;
BA_ "GenSigStartValue" SG_ 2566749463 FMS1_TellTaleStatus15 7;
BA_ "GenSigCycleTime" SG_ 2566749463 FMS1_TellTaleStatus10 100;
BA_ "GenSigCycleTimeActive" SG_ 2566749463 FMS1_TellTaleStatus10 100;
BA_ "GenSigStartValue" SG_ 2566749463 FMS1_TellTaleStatus10 7;
BA_ "GenSigCycleTime" SG_ 2566801923 TransmissionRequestedGearFdbk 100;
BA_ "GenSigCycleTimeActive" SG_ 2566801923 TransmissionRequestedGearFdbk 100;
BA_ "GenSigStartValue" SG_ 2566801923 TransmissionRequestedGearFdbk 255;
BA_ "SPN" SG_ 2566801923 TransmissionRequestedGearFdbk 3289;
BA_ "GenSigCycleTime" SG_ 2566801923 TransmEngineCrankEnable2 100;
BA_ "GenSigCycleTimeActive" SG_ 2566801923 TransmEngineCrankEnable2 100;
BA_ "GenSigStartValue" SG_ 2566801923 TransmEngineCrankEnable2 3;
BA_ "Platform_VMCU1_Sig" SG_ 2566801923 TransmEngineCrankEnable2 1;
BA_ "SPN" SG_ 2566801923 TransmEngineCrankEnable2 2900;
BA_ "GenSigCycleTime" SG_ 2565866755 TransmissionActualGearRatio 100;
BA_ "GenSigCycleTimeActive" SG_ 2565866755 TransmissionActualGearRatio 100;
BA_ "GenSigStartValue" SG_ 2565866755 TransmissionActualGearRatio 65535;
BA_ "Platform_VMCU1_Sig" SG_ 2565866755 TransmissionActualGearRatio 1;
BA_ "SPN" SG_ 2565866755 TransmissionActualGearRatio 526;
BA_ "SeToolAncestorID_SIGNAL" SG_ 2565866755 TransmissionActualGearRatio "x0000001D0414E198";
BA_ "SeToolItemID_SIGNAL" SG_ 2565866755 TransmissionActualGearRatio "x0000001D0414E198";
BA_ "SeToolName_SIGNAL" SG_ 2565866755 TransmissionActualGearRatio "TransmissionActualGearRatio";
BA_ "SeToolVersion_SIGNAL" SG_ 2565866755 TransmissionActualGearRatio "1";
BA_ "GenSigCycleTime" SG_ 2565866755 TransmissionCurrentGear 100;
BA_ "GenSigCycleTimeActive" SG_ 2565866755 TransmissionCurrentGear 100;
BA_ "GenSigStartValue" SG_ 2565866755 TransmissionCurrentGear 255;
BA_ "Platform_VMCU1_Sig" SG_ 2565866755 TransmissionCurrentGear 1;
BA_ "SPN" SG_ 2565866755 TransmissionCurrentGear 523;
BA_ "SeToolAncestorID_SIGNAL" SG_ 2565866755 TransmissionCurrentGear "x0000001D0412E700";
BA_ "SeToolItemID_SIGNAL" SG_ 2565866755 TransmissionCurrentGear "x0000001D0412E700";
BA_ "SeToolName_SIGNAL" SG_ 2565866755 TransmissionCurrentGear "TransmissionCurrentGear";
BA_ "SeToolVersion_SIGNAL" SG_ 2565866755 TransmissionCurrentGear "1";
BA_ "GenSigCycleTime" SG_ 2565866755 TransmissionRangeSelected 100;
BA_ "GenSigCycleTimeActive" SG_ 2565866755 TransmissionRangeSelected 100;
BA_ "Platform_VMCU1_Sig" SG_ 2565866755 TransmissionRangeSelected 1;
BA_ "SPN" SG_ 2565866755 TransmissionRangeSelected 162;
BA_ "SigType" SG_ 2565866755 TransmissionRangeSelected 3;
BA_ "SeToolAncestorID_SIGNAL" SG_ 2565866755 TransmissionRangeSelected "x0000001D0416F5C6";
BA_ "SeToolItemID_SIGNAL" SG_ 2565866755 TransmissionRangeSelected "x0000001D04320F35";
BA_ "SeToolName_SIGNAL" SG_ 2565866755 TransmissionRangeSelected "TransmissionRangeSelected";
BA_ "SeToolVersion_SIGNAL" SG_ 2565866755 TransmissionRangeSelected "2";
BA_ "GenSigCycleTime" SG_ 2565866755 TransmissionRangeAttained 100;
BA_ "GenSigCycleTimeActive" SG_ 2565866755 TransmissionRangeAttained 100;
BA_ "Platform_VMCU1_Sig" SG_ 2565866755 TransmissionRangeAttained 1;
BA_ "SPN" SG_ 2565866755 TransmissionRangeAttained 163;
BA_ "SigType" SG_ 2565866755 TransmissionRangeAttained 3;
BA_ "SeToolAncestorID_SIGNAL" SG_ 2565866755 TransmissionRangeAttained "x0000001D04296471";
BA_ "SeToolItemID_SIGNAL" SG_ 2565866755 TransmissionRangeAttained "x0000001D04296471";
BA_ "SeToolName_SIGNAL" SG_ 2565866755 TransmissionRangeAttained "TransmissionRangeAttained";
BA_ "SeToolVersion_SIGNAL" SG_ 2565866755 TransmissionRangeAttained "1";
BA_ "GenSigCycleTime" SG_ 2565866755 TransmissionSelectedGear 100;
BA_ "GenSigCycleTimeActive" SG_ 2565866755 TransmissionSelectedGear 100;
BA_ "GenSigStartValue" SG_ 2565866755 TransmissionSelectedGear 255;
BA_ "Platform_VMCU1_Sig" SG_ 2565866755 TransmissionSelectedGear 1;
BA_ "SPN" SG_ 2565866755 TransmissionSelectedGear 524;
BA_ "SeToolAncestorID_SIGNAL" SG_ 2565866755 TransmissionSelectedGear "x0000001D0416F5A6";
BA_ "SeToolItemID_SIGNAL" SG_ 2565866755 TransmissionSelectedGear "x0000001D0416F5A6";
BA_ "SeToolName_SIGNAL" SG_ 2565866755 TransmissionSelectedGear "TransmissionSelectedGear";
BA_ "SeToolVersion_SIGNAL" SG_ 2565866755 TransmissionSelectedGear "1";
BA_ "GenSigCycleTime" SG_ 2364539395 PercentClutchSlip 100;
BA_ "GenSigCycleTimeActive" SG_ 2364539395 PercentClutchSlip 100;
BA_ "GenSigStartValue" SG_ 2364539395 PercentClutchSlip 255;
BA_ "Platform_VMCU1_Sig" SG_ 2364539395 PercentClutchSlip 1;
BA_ "SPN" SG_ 2364539395 PercentClutchSlip 522;
BA_ "SeToolAncestorID_SIGNAL" SG_ 2364539395 PercentClutchSlip "x0000001D04174A3C";
BA_ "SeToolItemID_SIGNAL" SG_ 2364539395 PercentClutchSlip "x0000001D04174A3C";
BA_ "SeToolName_SIGNAL" SG_ 2364539395 PercentClutchSlip "PercentClutchSlip";
BA_ "SeToolVersion_SIGNAL" SG_ 2364539395 PercentClutchSlip "1";
BA_ "GenSigCycleTime" SG_ 2364539395 TransmissionOutputShaftSpeed2 100;
BA_ "GenSigCycleTimeActive" SG_ 2364539395 TransmissionOutputShaftSpeed2 100;
BA_ "GenSigStartValue" SG_ 2364539395 TransmissionOutputShaftSpeed2 65535;
BA_ "Platform_VMCU1_Sig" SG_ 2364539395 TransmissionOutputShaftSpeed2 1;
BA_ "SPN" SG_ 2364539395 TransmissionOutputShaftSpeed2 191;
BA_ "GenSigCycleTime" SG_ 2364539395 TransmTrqConvrtrLockupEngd 100;
BA_ "GenSigCycleTimeActive" SG_ 2364539395 TransmTrqConvrtrLockupEngd 100;
BA_ "GenSigStartValue" SG_ 2364539395 TransmTrqConvrtrLockupEngd 3;
BA_ "Platform_VMCU1_Sig" SG_ 2364539395 TransmTrqConvrtrLockupEngd 1;
BA_ "SPN" SG_ 2364539395 TransmTrqConvrtrLockupEngd 573;
BA_ "GenSigCycleTime" SG_ 2364539395 TransmissionDrivelineEngaged 100;
BA_ "GenSigCycleTimeActive" SG_ 2364539395 TransmissionDrivelineEngaged 100;
BA_ "GenSigStartValue" SG_ 2364539395 TransmissionDrivelineEngaged 3;
BA_ "Platform_VMCU1_Sig" SG_ 2364539395 TransmissionDrivelineEngaged 1;
BA_ "SPN" SG_ 2364539395 TransmissionDrivelineEngaged 560;
BA_ "SeToolAncestorID_SIGNAL" SG_ 2364539395 TransmissionDrivelineEngaged "x0000001D0410CEC8";
BA_ "SeToolItemID_SIGNAL" SG_ 2364539395 TransmissionDrivelineEngaged "x0000001D0410CEC8";
BA_ "SeToolName_SIGNAL" SG_ 2364539395 TransmissionDrivelineEngaged "TransmissionDrivelineEngaged";
BA_ "SeToolVersion_SIGNAL" SG_ 2364539395 TransmissionDrivelineEngaged "1";
BA_ "GenSigCycleTime" SG_ 2364539395 TransmissionInputShaftSpeed 100;
BA_ "GenSigCycleTimeActive" SG_ 2364539395 TransmissionInputShaftSpeed 100;
BA_ "GenSigStartValue" SG_ 2364539395 TransmissionInputShaftSpeed 65535;
BA_ "Platform_VMCU1_Sig" SG_ 2364539395 TransmissionInputShaftSpeed 1;
BA_ "SPN" SG_ 2364539395 TransmissionInputShaftSpeed 161;
BA_ "SeToolAncestorID_SIGNAL" SG_ 2364539395 TransmissionInputShaftSpeed "x0000001D0410D25D";
BA_ "SeToolItemID_SIGNAL" SG_ 2364539395 TransmissionInputShaftSpeed "x0000001D0410D25D";
BA_ "SeToolName_SIGNAL" SG_ 2364539395 TransmissionInputShaftSpeed "TransmissionInputShaftSpeed";
BA_ "SeToolVersion_SIGNAL" SG_ 2364539395 TransmissionInputShaftSpeed "1";
BA_ "GenSigCycleTime" SG_ 2364539395 MomentaryEngineOverspeedEnable 100;
BA_ "GenSigCycleTimeActive" SG_ 2364539395 MomentaryEngineOverspeedEnable 100;
BA_ "GenSigStartValue" SG_ 2364539395 MomentaryEngineOverspeedEnable 3;
BA_ "Platform_VMCU1_Sig" SG_ 2364539395 MomentaryEngineOverspeedEnable 1;
BA_ "SPN" SG_ 2364539395 MomentaryEngineOverspeedEnable 606;
BA_ "SeToolAncestorID_SIGNAL" SG_ 2364539395 MomentaryEngineOverspeedEnable "x0000001D041DB5AB";
BA_ "SeToolItemID_SIGNAL" SG_ 2364539395 MomentaryEngineOverspeedEnable "x0000001D041DB5AB";
BA_ "SeToolName_SIGNAL" SG_ 2364539395 MomentaryEngineOverspeedEnable "MomentaryEngineOverspeedEnable";
BA_ "SeToolVersion_SIGNAL" SG_ 2364539395 MomentaryEngineOverspeedEnable "1";
BA_ "GenSigCycleTime" SG_ 2364539395 TransmissionShiftInProcess 100;
BA_ "GenSigCycleTimeActive" SG_ 2364539395 TransmissionShiftInProcess 100;
BA_ "GenSigStartValue" SG_ 2364539395 TransmissionShiftInProcess 3;
BA_ "Platform_VMCU1_Sig" SG_ 2364539395 TransmissionShiftInProcess 1;
BA_ "SPN" SG_ 2364539395 TransmissionShiftInProcess 574;
BA_ "SeToolAncestorID_SIGNAL" SG_ 2364539395 TransmissionShiftInProcess "x0000001D0410D0F1";
BA_ "SeToolItemID_SIGNAL" SG_ 2364539395 TransmissionShiftInProcess "x0000001D0410D0F1";
BA_ "SeToolName_SIGNAL" SG_ 2364539395 TransmissionShiftInProcess "TransmissionShiftInProcess";
BA_ "SeToolVersion_SIGNAL" SG_ 2364539395 TransmissionShiftInProcess "1";
BA_ "GenSigCycleTime" SG_ 2566843904 EngineOilTemperature 100;
BA_ "GenSigCycleTimeActive" SG_ 2566843904 EngineOilTemperature 100;
BA_ "GenSigStartValue" SG_ 2566843904 EngineOilTemperature 65535;
BA_ "Platform_FactoryIf_Sig" SG_ 2566843904 EngineOilTemperature 1;
BA_ "Platform_VMCU1_Sig" SG_ 2566843904 EngineOilTemperature 1;
BA_ "SPN" SG_ 2566843904 EngineOilTemperature 175;
BA_ "SeToolAncestorID_SIGNAL" SG_ 2566843904 EngineOilTemperature "x0000001D0413132D";
BA_ "SeToolItemID_SIGNAL" SG_ 2566843904 EngineOilTemperature "x0000001D0413132D";
BA_ "SeToolName_SIGNAL" SG_ 2566843904 EngineOilTemperature "EngineOilTemperature";
BA_ "SeToolVersion_SIGNAL" SG_ 2566843904 EngineOilTemperature "1";
BA_ "GenSigCycleTime" SG_ 2566843904 EngineCoolantTemp_stat 100;
BA_ "GenSigCycleTimeActive" SG_ 2566843904 EngineCoolantTemp_stat 100;
BA_ "GenSigStartValue" SG_ 2566843904 EngineCoolantTemp_stat 255;
BA_ "Platform_VMCU1_Sig" SG_ 2566843904 EngineCoolantTemp_stat 1;
BA_ "SPN" SG_ 2566843904 EngineCoolantTemp_stat 110;
BA_ "SeToolAncestorID_SIGNAL" SG_ 2566843904 EngineCoolantTemp_stat "x0000001D0410E5B1";
BA_ "SeToolItemID_SIGNAL" SG_ 2566843904 EngineCoolantTemp_stat "x0000001D0410E5B1";
BA_ "SeToolName_SIGNAL" SG_ 2566843904 EngineCoolantTemp_stat "EngineCoolantTemperature_status";
BA_ "SeToolVersion_SIGNAL" SG_ 2566843904 EngineCoolantTemp_stat "1";
BA_ "GenSigSendType" SG_ 2558984359 RequestedFuelTypeVGGS 3;
BA_ "GenSigCycleTime" SG_ 2558984359 RequestedFuelTypeVGGS 100;
BA_ "GenSigCycleTimeActive" SG_ 2558984359 RequestedFuelTypeVGGS 100;
BA_ "GenSigStartValue" SG_ 2558984359 RequestedFuelTypeVGGS 255;
BA_ "SPN" SG_ 2558984359 RequestedFuelTypeVGGS 6317;
BA_ "GenSigCycleTime" SG_ 2565865488 EngineCoolantLoadIncrease 100;
BA_ "GenSigCycleTimeActive" SG_ 2565865488 EngineCoolantLoadIncrease 100;
BA_ "GenSigStartValue" SG_ 2565865488 EngineCoolantLoadIncrease 3;
BA_ "Platform_VMCU1_Sig" SG_ 2565865488 EngineCoolantLoadIncrease 1;
BA_ "SPN" SG_ 2565865488 EngineCoolantLoadIncrease 1082;
BA_ "GenSigCycleTime" SG_ 2565865488 ActualMaxAvailDrvlnRetPrctTrq 100;
BA_ "GenSigCycleTimeActive" SG_ 2565865488 ActualMaxAvailDrvlnRetPrctTrq 100;
BA_ "GenSigStartValue" SG_ 2565865488 ActualMaxAvailDrvlnRetPrctTrq 255;
BA_ "Platform_VMCU1_Sig" SG_ 2565865488 ActualMaxAvailDrvlnRetPrctTrq 1;
BA_ "SPN" SG_ 2565865488 ActualMaxAvailDrvlnRetPrctTrq 1717;
BA_ "GenSigCycleTime" SG_ 2565865488 ActualDrvlnRetdrPercentTorque 100;
BA_ "GenSigCycleTimeActive" SG_ 2565865488 ActualDrvlnRetdrPercentTorque 100;
BA_ "GenSigStartValue" SG_ 2565865488 ActualDrvlnRetdrPercentTorque 255;
BA_ "Platform_VMCU1_Sig" SG_ 2565865488 ActualDrvlnRetdrPercentTorque 1;
BA_ "SPN" SG_ 2565865488 ActualDrvlnRetdrPercentTorque 520;
BA_ "SeToolAncestorID_SIGNAL" SG_ 2565865488 ActualDrvlnRetdrPercentTorque "x0000001D0410CFDE";
BA_ "SeToolItemID_SIGNAL" SG_ 2565865488 ActualDrvlnRetdrPercentTorque "x0000001D0410CFDE";
BA_ "SeToolName_SIGNAL" SG_ 2565865488 ActualDrvlnRetdrPercentTorque "ActualDrivelineRetarderPercentTorque";
BA_ "SeToolVersion_SIGNAL" SG_ 2565865488 ActualDrvlnRetdrPercentTorque "1";
BA_ "GenSigCycleTime" SG_ 2565865488 RetarderTorqueMode 100;
BA_ "GenSigCycleTimeActive" SG_ 2565865488 RetarderTorqueMode 100;
BA_ "GenSigStartValue" SG_ 2565865488 RetarderTorqueMode 15;
BA_ "Platform_VMCU1_Sig" SG_ 2565865488 RetarderTorqueMode 1;
BA_ "SPN" SG_ 2565865488 RetarderTorqueMode 900;
BA_ "GenSigCycleTime" SG_ 2565865487 ActlMaxAvailEngRetdrPercentTrq 100;
BA_ "GenSigCycleTimeActive" SG_ 2565865487 ActlMaxAvailEngRetdrPercentTrq 100;
BA_ "GenSigStartValue" SG_ 2565865487 ActlMaxAvailEngRetdrPercentTrq 255;
BA_ "Platform_VMCU1_Sig" SG_ 2565865487 ActlMaxAvailEngRetdrPercentTrq 1;
BA_ "SPN" SG_ 2565865487 ActlMaxAvailEngRetdrPercentTrq 1717;
BA_ "SeToolAncestorID_SIGNAL" SG_ 2565865487 ActlMaxAvailEngRetdrPercentTrq "x0000001D041286DD";
BA_ "SeToolItemID_SIGNAL" SG_ 2565865487 ActlMaxAvailEngRetdrPercentTrq "x0000001D0437CD37";
BA_ "SeToolName_SIGNAL" SG_ 2565865487 ActlMaxAvailEngRetdrPercentTrq "ActualMaximumAvailableEngineRetarder-PercentTorque";
BA_ "SeToolVersion_SIGNAL" SG_ 2565865487 ActlMaxAvailEngRetdrPercentTrq "2";
BA_ "GenSigCycleTime" SG_ 2565865487 RetarderEnableShiftAssistSw 100;
BA_ "GenSigCycleTimeActive" SG_ 2565865487 RetarderEnableShiftAssistSw 100;
BA_ "GenSigStartValue" SG_ 2565865487 RetarderEnableShiftAssistSw 3;
BA_ "Platform_VMCU1_Sig" SG_ 2565865487 RetarderEnableShiftAssistSw 1;
BA_ "SPN" SG_ 2565865487 RetarderEnableShiftAssistSw 572;
BA_ "SeToolAncestorID_SIGNAL" SG_ 2565865487 RetarderEnableShiftAssistSw "x0000001D042E05A1";
BA_ "SeToolItemID_SIGNAL" SG_ 2565865487 RetarderEnableShiftAssistSw "x0000001D042E05A1";
BA_ "SeToolName_SIGNAL" SG_ 2565865487 RetarderEnableShiftAssistSw "RetarderEnableShiftAssistSwitch";
BA_ "SeToolVersion_SIGNAL" SG_ 2565865487 RetarderEnableShiftAssistSw "1";
BA_ "GenSigCycleTime" SG_ 2565865487 EngineRetarderTorqueMode 100;
BA_ "GenSigCycleTimeActive" SG_ 2565865487 EngineRetarderTorqueMode 100;
BA_ "GenSigStartValue" SG_ 2565865487 EngineRetarderTorqueMode 15;
BA_ "SPN" SG_ 2565865487 EngineRetarderTorqueMode 900;
BA_ "GenSigCycleTime" SG_ 2565865487 EngRetdrEnableBrakeAssistSw 100;
BA_ "GenSigCycleTimeActive" SG_ 2565865487 EngRetdrEnableBrakeAssistSw 100;
BA_ "GenSigStartValue" SG_ 2565865487 EngRetdrEnableBrakeAssistSw 3;
BA_ "Platform_VMCU1_Sig" SG_ 2565865487 EngRetdrEnableBrakeAssistSw 1;
BA_ "SPN" SG_ 2565865487 EngRetdrEnableBrakeAssistSw 571;
BA_ "GenSigCycleTime" SG_ 2565865487 ActualEngineRetarderPercentTrq 100;
BA_ "GenSigCycleTimeActive" SG_ 2565865487 ActualEngineRetarderPercentTrq 100;
BA_ "GenSigStartValue" SG_ 2565865487 ActualEngineRetarderPercentTrq 255;
BA_ "Platform_VMCU1_Sig" SG_ 2565865487 ActualEngineRetarderPercentTrq 1;
BA_ "SPN" SG_ 2565865487 ActualEngineRetarderPercentTrq 520;
BA_ "SeToolAncestorID_SIGNAL" SG_ 2565865487 ActualEngineRetarderPercentTrq "x0000001D0410BAE1";
BA_ "SeToolItemID_SIGNAL" SG_ 2565865487 ActualEngineRetarderPercentTrq "x0000001D043C302E";
BA_ "SeToolName_SIGNAL" SG_ 2565865487 ActualEngineRetarderPercentTrq "ActualEngineRetarderPercentTorque";
BA_ "SeToolVersion_SIGNAL" SG_ 2565865487 ActualEngineRetarderPercentTrq "2";
BA_ "GenSigCycleTime" SG_ 2364541440 EngineIntakeAirRate 100;
BA_ "GenSigCycleTimeActive" SG_ 2364541440 EngineIntakeAirRate 100;
BA_ "GenSigStartValue" SG_ 2364541440 EngineIntakeAirRate 65535;
BA_ "SPN" SG_ 2364541440 EngineIntakeAirRate 132;
BA_ "GenSigCycleTime" SG_ 2566844160 EngineOilLevel 100;
BA_ "GenSigCycleTimeActive" SG_ 2566844160 EngineOilLevel 100;
BA_ "GenSigStartValue" SG_ 2566844160 EngineOilLevel 255;
BA_ "Platform_VMCU1_Sig" SG_ 2566844160 EngineOilLevel 1;
BA_ "SPN" SG_ 2566844160 EngineOilLevel 98;
BA_ "SeToolAncestorID_SIGNAL" SG_ 2566844160 EngineOilLevel "x0000001D0412B86E";
BA_ "SeToolItemID_SIGNAL" SG_ 2566844160 EngineOilLevel "x0000001D0412B86E";
BA_ "SeToolName_SIGNAL" SG_ 2566844160 EngineOilLevel "EngineOilLevel";
BA_ "SeToolVersion_SIGNAL" SG_ 2566844160 EngineOilLevel "1";
BA_ "GenSigCycleTime" SG_ 2566844160 EngineOilPressure 100;
BA_ "GenSigCycleTimeActive" SG_ 2566844160 EngineOilPressure 100;
BA_ "GenSigStartValue" SG_ 2566844160 EngineOilPressure 255;
BA_ "Platform_FactoryIf_Sig" SG_ 2566844160 EngineOilPressure 1;
BA_ "Platform_VMCU1_Sig" SG_ 2566844160 EngineOilPressure 1;
BA_ "SPN" SG_ 2566844160 EngineOilPressure 100;
BA_ "SeToolAncestorID_SIGNAL" SG_ 2566844160 EngineOilPressure "x0000001D041937A0";
BA_ "SeToolItemID_SIGNAL" SG_ 2566844160 EngineOilPressure "x0000001D041937A0";
BA_ "SeToolName_SIGNAL" SG_ 2566844160 EngineOilPressure "EngineOilPressure";
BA_ "SeToolVersion_SIGNAL" SG_ 2566844160 EngineOilPressure "1";
BA_ "GenSigCycleTime" SG_ 2566840064 NominalFrictionPercentTorque 100;
BA_ "GenSigCycleTimeActive" SG_ 2566840064 NominalFrictionPercentTorque 100;
BA_ "GenSigStartValue" SG_ 2566840064 NominalFrictionPercentTorque 255;
BA_ "Platform_VMCU1_Sig" SG_ 2566840064 NominalFrictionPercentTorque 1;
BA_ "SPN" SG_ 2566840064 NominalFrictionPercentTorque 514;
BA_ "SeToolAncestorID_SIGNAL" SG_ 2566840064 NominalFrictionPercentTorque "x0000001D0410CF68";
BA_ "SeToolItemID_SIGNAL" SG_ 2566840064 NominalFrictionPercentTorque "x0000001D04295709";
BA_ "SeToolName_SIGNAL" SG_ 2566840064 NominalFrictionPercentTorque "NominalFrictionPercentTorque";
BA_ "SeToolVersion_SIGNAL" SG_ 2566840064 NominalFrictionPercentTorque "2";
BA_ "GenSigCycleTime" SG_ 2364539648 AcctrPedalKickDownSw_stat_2 100;
BA_ "GenSigCycleTimeActive" SG_ 2364539648 AcctrPedalKickDownSw_stat_2 100;
BA_ "GenSigStartValue" SG_ 2364539648 AcctrPedalKickDownSw_stat_2 3;
BA_ "Platform_VMCU1_Sig" SG_ 2364539648 AcctrPedalKickDownSw_stat_2 1;
BA_ "SPN" SG_ 2364539648 AcctrPedalKickDownSw_stat_2 559;
BA_ "GenSigCycleTime" SG_ 2364539648 EnginePercentLoadAtCurrentSpd 100;
BA_ "GenSigCycleTimeActive" SG_ 2364539648 EnginePercentLoadAtCurrentSpd 100;
BA_ "GenSigStartValue" SG_ 2364539648 EnginePercentLoadAtCurrentSpd 255;
BA_ "Platform_FactoryIf_Sig" SG_ 2364539648 EnginePercentLoadAtCurrentSpd 1;
BA_ "Platform_VMCU1_Sig" SG_ 2364539648 EnginePercentLoadAtCurrentSpd 1;
BA_ "SPN" SG_ 2364539648 EnginePercentLoadAtCurrentSpd 92;
BA_ "SeToolAncestorID_SIGNAL" SG_ 2364539648 EnginePercentLoadAtCurrentSpd "x0000001D04172658";
BA_ "SeToolItemID_SIGNAL" SG_ 2364539648 EnginePercentLoadAtCurrentSpd "x0000001D04172658";
BA_ "SeToolName_SIGNAL" SG_ 2364539648 EnginePercentLoadAtCurrentSpd "EnginePercentLoadAtCurrentSpeed";
BA_ "SeToolVersion_SIGNAL" SG_ 2364539648 EnginePercentLoadAtCurrentSpd "1";
BA_ "GenSigCycleTime" SG_ 2364539648 AcceleratorPedalPosition1_2 100;
BA_ "GenSigCycleTimeActive" SG_ 2364539648 AcceleratorPedalPosition1_2 100;
BA_ "GenSigStartValue" SG_ 2364539648 AcceleratorPedalPosition1_2 255;
BA_ "Platform_VMCU1_Sig" SG_ 2364539648 AcceleratorPedalPosition1_2 1;
BA_ "SPN" SG_ 2364539648 AcceleratorPedalPosition1_2 91;
BA_ "GenSigCycleTime" SG_ 2364539648 RoadSpeedLimitStatus 100;
BA_ "GenSigCycleTimeActive" SG_ 2364539648 RoadSpeedLimitStatus 100;
BA_ "GenSigStartValue" SG_ 2364539648 RoadSpeedLimitStatus 3;
BA_ "Platform_VMCU1_Sig" SG_ 2364539648 RoadSpeedLimitStatus 1;
BA_ "SPN" SG_ 2364539648 RoadSpeedLimitStatus 1437;
BA_ "GenSigCycleTime" SG_ 2364539904 EngineDemandPercentTorque 100;
BA_ "GenSigCycleTimeActive" SG_ 2364539904 EngineDemandPercentTorque 100;
BA_ "GenSigStartValue" SG_ 2364539904 EngineDemandPercentTorque 255;
BA_ "Platform_VMCU1_Sig" SG_ 2364539904 EngineDemandPercentTorque 1;
BA_ "SPN" SG_ 2364539904 EngineDemandPercentTorque 2432;
BA_ "GenSigCycleTime" SG_ 2364539904 DrvrDemandEngPercentTorque 100;
BA_ "GenSigCycleTimeActive" SG_ 2364539904 DrvrDemandEngPercentTorque 100;
BA_ "GenSigStartValue" SG_ 2364539904 DrvrDemandEngPercentTorque 255;
BA_ "Platform_VMCU1_Sig" SG_ 2364539904 DrvrDemandEngPercentTorque 1;
BA_ "SPN" SG_ 2364539904 DrvrDemandEngPercentTorque 512;
BA_ "SeToolAncestorID_SIGNAL" SG_ 2364539904 DrvrDemandEngPercentTorque "x0000001D0410D0C7";
BA_ "SeToolItemID_SIGNAL" SG_ 2364539904 DrvrDemandEngPercentTorque "x0000001D0410D0C7";
BA_ "SeToolName_SIGNAL" SG_ 2364539904 DrvrDemandEngPercentTorque "Driver'sDemandEngine-PercentTorque";
BA_ "SeToolVersion_SIGNAL" SG_ 2364539904 DrvrDemandEngPercentTorque "1";
BA_ "GenSigCycleTime" SG_ 2364539904 EngineTorqueMode 100;
BA_ "GenSigCycleTimeActive" SG_ 2364539904 EngineTorqueMode 100;
BA_ "GenSigStartValue" SG_ 2364539904 EngineTorqueMode 15;
BA_ "Platform_VMCU1_Sig" SG_ 2364539904 EngineTorqueMode 1;
BA_ "SPN" SG_ 2364539904 EngineTorqueMode 899;
BA_ "SeToolAncestorID_SIGNAL" SG_ 2364539904 EngineTorqueMode "x0000001D0414E4FD";
BA_ "SeToolItemID_SIGNAL" SG_ 2364539904 EngineTorqueMode "x0000001D0414E4FD";
BA_ "SeToolName_SIGNAL" SG_ 2364539904 EngineTorqueMode "EngineTorqueMode";
BA_ "SeToolVersion_SIGNAL" SG_ 2364539904 EngineTorqueMode "1";
BA_ "GenSigCycleTime" SG_ 2364539904 EngineSpeed 100;
BA_ "GenSigCycleTimeActive" SG_ 2364539904 EngineSpeed 100;
BA_ "GenSigStartValue" SG_ 2364539904 EngineSpeed 65535;
BA_ "Platform_VMCU1_Sig" SG_ 2364539904 EngineSpeed 1;
BA_ "SPN" SG_ 2364539904 EngineSpeed 190;
BA_ "SeToolAncestorID_SIGNAL" SG_ 2364539904 EngineSpeed "x0000001D0410BACF";
BA_ "SeToolItemID_SIGNAL" SG_ 2364539904 EngineSpeed "x0000001D0410BACF";
BA_ "SeToolName_SIGNAL" SG_ 2364539904 EngineSpeed "EngineSpeed_status";
BA_ "SeToolVersion_SIGNAL" SG_ 2364539904 EngineSpeed "1";
BA_ "GenSigCycleTime" SG_ 2364539904 ActualEnginePercentTorque 100;
BA_ "GenSigCycleTimeActive" SG_ 2364539904 ActualEnginePercentTorque 100;
BA_ "GenSigStartValue" SG_ 2364539904 ActualEnginePercentTorque 255;
BA_ "Platform_VMCU1_Sig" SG_ 2364539904 ActualEnginePercentTorque 1;
BA_ "SPN" SG_ 2364539904 ActualEnginePercentTorque 513;
BA_ "SeToolAncestorID_SIGNAL" SG_ 2364539904 ActualEnginePercentTorque "x0000001D0410CDD5";
BA_ "SeToolItemID_SIGNAL" SG_ 2364539904 ActualEnginePercentTorque "x0000001D0410CDD5";
BA_ "SeToolName_SIGNAL" SG_ 2364539904 ActualEnginePercentTorque "ActualEngine-PercentTorque";
BA_ "SeToolVersion_SIGNAL" SG_ 2364539904 ActualEnginePercentTorque "1";
BA_ "GenSigCycleTime" SG_ 2364539904 EngineStarterMode 100;
BA_ "GenSigCycleTimeActive" SG_ 2364539904 EngineStarterMode 100;
BA_ "GenSigStartValue" SG_ 2364539904 EngineStarterMode 15;
BA_ "Platform_FactoryIf_Sig" SG_ 2364539904 EngineStarterMode 1;
BA_ "Platform_VMCU1_Sig" SG_ 2364539904 EngineStarterMode 1;
BA_ "SPN" SG_ 2364539904 EngineStarterMode 1675;
BA_ "SeToolAncestorID_SIGNAL" SG_ 2364539904 EngineStarterMode "x0000001D04146CF7";
BA_ "SeToolItemID_SIGNAL" SG_ 2364539904 EngineStarterMode "x0000001D04146CF7";
BA_ "SeToolName_SIGNAL" SG_ 2364539904 EngineStarterMode "EngineStarterMode";
BA_ "SeToolVersion_SIGNAL" SG_ 2364539904 EngineStarterMode "1";
BA_ "GenSigSendType" SG_ 2566767104 FuelTypeEMS 3;
BA_ "GenSigCycleTime" SG_ 2566767104 FuelTypeEMS 100;
BA_ "GenSigCycleTimeActive" SG_ 2566767104 FuelTypeEMS 100;
BA_ "GenSigStartValue" SG_ 2566767104 FuelTypeEMS 255;
BA_ "SPN" SG_ 2566767104 FuelTypeEMS 5837;
BA_ "GenSigSendType" SG_ 2566841088 EngConf_EngSpeedAtHighIdle_P6 3;
BA_ "GenSigStartValue" SG_ 2566841088 EngConf_EngSpeedAtHighIdle_P6 65535;
BA_ "Platform_VMCU1_Sig" SG_ 2566841088 EngConf_EngSpeedAtHighIdle_P6 1;
BA_ "SPN" SG_ 2566841088 EngConf_EngSpeedAtHighIdle_P6 532;
BA_ "SeToolAncestorID_SIGNAL" SG_ 2566841088 EngConf_EngSpeedAtHighIdle_P6 "x0000001D0429A8E3";
BA_ "SeToolItemID_SIGNAL" SG_ 2566841088 EngConf_EngSpeedAtHighIdle_P6 "x0000001D0429A8E3";
BA_ "SeToolName_SIGNAL" SG_ 2566841088 EngConf_EngSpeedAtHighIdle_P6 "EngConf_EngSpeedAtHighIdle_P6";
BA_ "SeToolVersion_SIGNAL" SG_ 2566841088 EngConf_EngSpeedAtHighIdle_P6 "1";
BA_ "GenSigSendType" SG_ 2566841088 EngConf_EngTorqueAt_P4 3;
BA_ "GenSigStartValue" SG_ 2566841088 EngConf_EngTorqueAt_P4 255;
BA_ "Platform_VMCU1_Sig" SG_ 2566841088 EngConf_EngTorqueAt_P4 1;
BA_ "SPN" SG_ 2566841088 EngConf_EngTorqueAt_P4 542;
BA_ "SeToolAncestorID_SIGNAL" SG_ 2566841088 EngConf_EngTorqueAt_P4 "x0000001D0429EA2A";
BA_ "SeToolItemID_SIGNAL" SG_ 2566841088 EngConf_EngTorqueAt_P4 "x0000001D0429EA2A";
BA_ "SeToolName_SIGNAL" SG_ 2566841088 EngConf_EngTorqueAt_P4 "EngConf_EngTorqueAt_P4";
BA_ "SeToolVersion_SIGNAL" SG_ 2566841088 EngConf_EngTorqueAt_P4 "1";
BA_ "GenSigSendType" SG_ 2566841088 EngConf_EngMaxMomOvSpeed_P7 3;
BA_ "GenSigStartValue" SG_ 2566841088 EngConf_EngMaxMomOvSpeed_P7 65535;
BA_ "Platform_VMCU1_Sig" SG_ 2566841088 EngConf_EngMaxMomOvSpeed_P7 1;
BA_ "SPN" SG_ 2566841088 EngConf_EngMaxMomOvSpeed_P7 533;
BA_ "SeToolAncestorID_SIGNAL" SG_ 2566841088 EngConf_EngMaxMomOvSpeed_P7 "x0000001D0429A8EA";
BA_ "SeToolItemID_SIGNAL" SG_ 2566841088 EngConf_EngMaxMomOvSpeed_P7 "x0000001D0429A8EA";
BA_ "SeToolName_SIGNAL" SG_ 2566841088 EngConf_EngMaxMomOvSpeed_P7 "EngConf_EngMaxMomOvSpeed_P7";
BA_ "SeToolVersion_SIGNAL" SG_ 2566841088 EngConf_EngMaxMomOvSpeed_P7 "1";
BA_ "GenSigSendType" SG_ 2566841088 EngConf_EngTorqueAt_P5 3;
BA_ "GenSigStartValue" SG_ 2566841088 EngConf_EngTorqueAt_P5 255;
BA_ "Platform_VMCU1_Sig" SG_ 2566841088 EngConf_EngTorqueAt_P5 1;
BA_ "SPN" SG_ 2566841088 EngConf_EngTorqueAt_P5 543;
BA_ "SeToolAncestorID_SIGNAL" SG_ 2566841088 EngConf_EngTorqueAt_P5 "x0000001D0429EA2C";
BA_ "SeToolItemID_SIGNAL" SG_ 2566841088 EngConf_EngTorqueAt_P5 "x0000001D0429EA2C";
BA_ "SeToolName_SIGNAL" SG_ 2566841088 EngConf_EngTorqueAt_P5 "EngConf_EngTorqueAt_P5";
BA_ "SeToolVersion_SIGNAL" SG_ 2566841088 EngConf_EngTorqueAt_P5 "1";
BA_ "GenSigSendType" SG_ 2566841088 EngConf_EngSpeedAtIdle_P1 3;
BA_ "GenSigStartValue" SG_ 2566841088 EngConf_EngSpeedAtIdle_P1 65535;
BA_ "Platform_VMCU1_Sig" SG_ 2566841088 EngConf_EngSpeedAtIdle_P1 1;
BA_ "SPN" SG_ 2566841088 EngConf_EngSpeedAtIdle_P1 188;
BA_ "SeToolAncestorID_SIGNAL" SG_ 2566841088 EngConf_EngSpeedAtIdle_P1 "x0000001D0429A8D5";
BA_ "SeToolItemID_SIGNAL" SG_ 2566841088 EngConf_EngSpeedAtIdle_P1 "x0000001D0429A8D5";
BA_ "SeToolName_SIGNAL" SG_ 2566841088 EngConf_EngSpeedAtIdle_P1 "EngConf_EngSpeedAtIdle_P1";
BA_ "SeToolVersion_SIGNAL" SG_ 2566841088 EngConf_EngSpeedAtIdle_P1 "1";
BA_ "GenSigSendType" SG_ 2566841088 EngineReferenceTorque 3;
BA_ "GenSigStartValue" SG_ 2566841088 EngineReferenceTorque 65535;
BA_ "Platform_VMCU1_Sig" SG_ 2566841088 EngineReferenceTorque 1;
BA_ "SPN" SG_ 2566841088 EngineReferenceTorque 544;
BA_ "SeToolAncestorID_SIGNAL" SG_ 2566841088 EngineReferenceTorque "x0000001D041286BC";
BA_ "SeToolItemID_SIGNAL" SG_ 2566841088 EngineReferenceTorque "x0000001D041286BC";
BA_ "SeToolName_SIGNAL" SG_ 2566841088 EngineReferenceTorque "EngineReferenceTorque";
BA_ "SeToolVersion_SIGNAL" SG_ 2566841088 EngineReferenceTorque "1";
BA_ "GenSigSendType" SG_ 2566841088 EngConf_EngSpeedAt_P2 3;
BA_ "GenSigStartValue" SG_ 2566841088 EngConf_EngSpeedAt_P2 65535;
BA_ "Platform_VMCU1_Sig" SG_ 2566841088 EngConf_EngSpeedAt_P2 1;
BA_ "SPN" SG_ 2566841088 EngConf_EngSpeedAt_P2 528;
BA_ "SeToolAncestorID_SIGNAL" SG_ 2566841088 EngConf_EngSpeedAt_P2 "x0000001D0429A8D8";
BA_ "SeToolItemID_SIGNAL" SG_ 2566841088 EngConf_EngSpeedAt_P2 "x0000001D0429A8D8";
BA_ "SeToolName_SIGNAL" SG_ 2566841088 EngConf_EngSpeedAt_P2 "EngConf_EngSpeedAt_P2";
BA_ "SeToolVersion_SIGNAL" SG_ 2566841088 EngConf_EngSpeedAt_P2 "1";
BA_ "GenSigSendType" SG_ 2566841088 EngConf_MaxMomOverrideTimeLim 3;
BA_ "GenSigStartValue" SG_ 2566841088 EngConf_MaxMomOverrideTimeLim 255;
BA_ "Platform_VMCU1_Sig" SG_ 2566841088 EngConf_MaxMomOverrideTimeLim 1;
BA_ "SPN" SG_ 2566841088 EngConf_MaxMomOverrideTimeLim 534;
BA_ "SeToolAncestorID_SIGNAL" SG_ 2566841088 EngConf_MaxMomOverrideTimeLim "x0000001D0429EA9F";
BA_ "SeToolItemID_SIGNAL" SG_ 2566841088 EngConf_MaxMomOverrideTimeLim "x0000001D0429EA9F";
BA_ "SeToolName_SIGNAL" SG_ 2566841088 EngConf_MaxMomOverrideTimeLim "EngConf_MaxMomOverrideTimeLimit";
BA_ "SeToolVersion_SIGNAL" SG_ 2566841088 EngConf_MaxMomOverrideTimeLim "1";
BA_ "GenSigSendType" SG_ 2566841088 EngConf_EngSpeedAt_P5 3;
BA_ "GenSigStartValue" SG_ 2566841088 EngConf_EngSpeedAt_P5 65535;
BA_ "Platform_VMCU1_Sig" SG_ 2566841088 EngConf_EngSpeedAt_P5 1;
BA_ "SPN" SG_ 2566841088 EngConf_EngSpeedAt_P5 531;
BA_ "SeToolAncestorID_SIGNAL" SG_ 2566841088 EngConf_EngSpeedAt_P5 "x0000001D0429A8E1";
BA_ "SeToolItemID_SIGNAL" SG_ 2566841088 EngConf_EngSpeedAt_P5 "x0000001D0429A8E1";
BA_ "SeToolName_SIGNAL" SG_ 2566841088 EngConf_EngSpeedAt_P5 "EngConf_EngSpeedAt_P5";
BA_ "SeToolVersion_SIGNAL" SG_ 2566841088 EngConf_EngSpeedAt_P5 "1";
BA_ "GenSigSendType" SG_ 2566841088 EngConf_EngTorqueAtIdle_P1 3;
BA_ "GenSigStartValue" SG_ 2566841088 EngConf_EngTorqueAtIdle_P1 255;
BA_ "Platform_VMCU1_Sig" SG_ 2566841088 EngConf_EngTorqueAtIdle_P1 1;
BA_ "SPN" SG_ 2566841088 EngConf_EngTorqueAtIdle_P1 539;
BA_ "SeToolAncestorID_SIGNAL" SG_ 2566841088 EngConf_EngTorqueAtIdle_P1 "x0000001D0429EA1D";
BA_ "SeToolItemID_SIGNAL" SG_ 2566841088 EngConf_EngTorqueAtIdle_P1 "x0000001D0429EA1D";
BA_ "SeToolName_SIGNAL" SG_ 2566841088 EngConf_EngTorqueAtIdle_P1 "EngConf_EngTorqueAtIdle_P1";
BA_ "SeToolVersion_SIGNAL" SG_ 2566841088 EngConf_EngTorqueAtIdle_P1 "1";
BA_ "GenSigSendType" SG_ 2566841088 EngConf_EngSpeedAt_P4 3;
BA_ "GenSigStartValue" SG_ 2566841088 EngConf_EngSpeedAt_P4 65535;
BA_ "Platform_VMCU1_Sig" SG_ 2566841088 EngConf_EngSpeedAt_P4 1;
BA_ "SPN" SG_ 2566841088 EngConf_EngSpeedAt_P4 530;
BA_ "SeToolAncestorID_SIGNAL" SG_ 2566841088 EngConf_EngSpeedAt_P4 "x0000001D0429A8DF";
BA_ "SeToolItemID_SIGNAL" SG_ 2566841088 EngConf_EngSpeedAt_P4 "x0000001D0429A8DF";
BA_ "SeToolName_SIGNAL" SG_ 2566841088 EngConf_EngSpeedAt_P4 "EngConf_EngSpeedAt_P4";
BA_ "SeToolVersion_SIGNAL" SG_ 2566841088 EngConf_EngSpeedAt_P4 "1";
BA_ "GenSigSendType" SG_ 2566841088 EngConf_EngSpeedAt_P3 3;
BA_ "GenSigStartValue" SG_ 2566841088 EngConf_EngSpeedAt_P3 65535;
BA_ "Platform_VMCU1_Sig" SG_ 2566841088 EngConf_EngSpeedAt_P3 1;
BA_ "SPN" SG_ 2566841088 EngConf_EngSpeedAt_P3 529;
BA_ "SeToolAncestorID_SIGNAL" SG_ 2566841088 EngConf_EngSpeedAt_P3 "x0000001D0429A8DD";
BA_ "SeToolItemID_SIGNAL" SG_ 2566841088 EngConf_EngSpeedAt_P3 "x0000001D0429A8DD";
BA_ "SeToolName_SIGNAL" SG_ 2566841088 EngConf_EngSpeedAt_P3 "EngConf_EngSpeedAt_P3";
BA_ "SeToolVersion_SIGNAL" SG_ 2566841088 EngConf_EngSpeedAt_P3 "1";
BA_ "GenSigSendType" SG_ 2566841088 EngConf_EngTorqueAt_P3 3;
BA_ "GenSigStartValue" SG_ 2566841088 EngConf_EngTorqueAt_P3 255;
BA_ "Platform_VMCU1_Sig" SG_ 2566841088 EngConf_EngTorqueAt_P3 1;
BA_ "SPN" SG_ 2566841088 EngConf_EngTorqueAt_P3 541;
BA_ "SeToolAncestorID_SIGNAL" SG_ 2566841088 EngConf_EngTorqueAt_P3 "x0000001D0429EA28";
BA_ "SeToolItemID_SIGNAL" SG_ 2566841088 EngConf_EngTorqueAt_P3 "x0000001D0429EA28";
BA_ "SeToolName_SIGNAL" SG_ 2566841088 EngConf_EngTorqueAt_P3 "EngConf_EngTorqueAt_P3";
BA_ "SeToolVersion_SIGNAL" SG_ 2566841088 EngConf_EngTorqueAt_P3 "1";
BA_ "GenSigSendType" SG_ 2566841088 EngConf_EngTorqueAt_P2 3;
BA_ "GenSigStartValue" SG_ 2566841088 EngConf_EngTorqueAt_P2 255;
BA_ "Platform_VMCU1_Sig" SG_ 2566841088 EngConf_EngTorqueAt_P2 1;
BA_ "SPN" SG_ 2566841088 EngConf_EngTorqueAt_P2 540;
BA_ "SeToolAncestorID_SIGNAL" SG_ 2566841088 EngConf_EngTorqueAt_P2 "x0000001D0429EA26";
BA_ "SeToolItemID_SIGNAL" SG_ 2566841088 EngConf_EngTorqueAt_P2 "x0000001D0429EA26";
BA_ "SeToolName_SIGNAL" SG_ 2566841088 EngConf_EngTorqueAt_P2 "EngConf_EngTorqueAt_P2";
BA_ "SeToolVersion_SIGNAL" SG_ 2566841088 EngConf_EngTorqueAt_P2 "1";
BA_ "GenSigCycleTime" SG_ 2566894859 Trailer5VIN 100;
BA_ "GenSigCycleTimeActive" SG_ 2566894859 Trailer5VIN 100;
BA_ "GenSigMaxLatency" SG_ 2566894859 Trailer5VIN 10000;
BA_ "GenSigCycleTime" SG_ 2566894603 Trailer4VIN 100;
BA_ "GenSigCycleTimeActive" SG_ 2566894603 Trailer4VIN 100;
BA_ "GenSigMaxLatency" SG_ 2566894603 Trailer4VIN 10000;
BA_ "GenSigCycleTime" SG_ 2566894347 Trailer3VIN 100;
BA_ "GenSigCycleTimeActive" SG_ 2566894347 Trailer3VIN 100;
BA_ "GenSigMaxLatency" SG_ 2566894347 Trailer3VIN 10000;
BA_ "GenSigCycleTime" SG_ 2566894091 Trailer2VIN 100;
BA_ "GenSigCycleTimeActive" SG_ 2566894091 Trailer2VIN 100;
BA_ "GenSigMaxLatency" SG_ 2566894091 Trailer2VIN 10000;
BA_ "GenSigCycleTime" SG_ 2566893835 Trailer1VIN 100;
BA_ "GenSigCycleTimeActive" SG_ 2566893835 Trailer1VIN 100;
BA_ "GenSigMaxLatency" SG_ 2566893835 Trailer1VIN 10000;
BA_ "GenSigCycleTime" SG_ 2566903051 Trailer5GeometricData_Index 100;
BA_ "GenSigCycleTimeActive" SG_ 2566903051 Trailer5GeometricData_Index 100;
BA_ "GenSigStartValue" SG_ 2566903051 Trailer5GeometricData_Index 255;
BA_ "GenSigMaxLatency" SG_ 2566903051 Trailer5GeometricData_Index 1010;
BA_ "Platform_VMCU1_Sig" SG_ 2566903051 Trailer5GeometricData_Index 1;
BA_ "GenSigCycleTime" SG_ 2566903051 PadChangePredictionAxleNumber 100;
BA_ "GenSigCycleTimeActive" SG_ 2566903051 PadChangePredictionAxleNumber 100;
BA_ "GenSigStartValue" SG_ 2566903051 PadChangePredictionAxleNumber 7;
BA_ "Platform_VMCU1_Sig" SG_ 2566903051 PadChangePredictionAxleNumber 1;
BA_ "GenSigCycleTime" SG_ 2566903051 XBRBrakingCapacityTime 100;
BA_ "GenSigCycleTimeActive" SG_ 2566903051 XBRBrakingCapacityTime 100;
BA_ "GenSigStartValue" SG_ 2566903051 XBRBrakingCapacityTime 255;
BA_ "Platform_VMCU1_Sig" SG_ 2566903051 XBRBrakingCapacityTime 1;
BA_ "GenSigCycleTime" SG_ 2566903051 Trailer5AxleLoadSum 100;
BA_ "GenSigCycleTimeActive" SG_ 2566903051 Trailer5AxleLoadSum 100;
BA_ "GenSigStartValue" SG_ 2566903051 Trailer5AxleLoadSum 65535;
BA_ "GenSigMaxLatency" SG_ 2566903051 Trailer5AxleLoadSum 500;
BA_ "Platform_VMCU1_Sig" SG_ 2566903051 Trailer5AxleLoadSum 1;
BA_ "GenSigCycleTime" SG_ 2566903051 XBRBrakingCapacityTemperature 100;
BA_ "GenSigCycleTimeActive" SG_ 2566903051 XBRBrakingCapacityTemperature 100;
BA_ "GenSigStartValue" SG_ 2566903051 XBRBrakingCapacityTemperature 255;
BA_ "Platform_VMCU1_Sig" SG_ 2566903051 XBRBrakingCapacityTemperature 1;
BA_ "GenSigCycleTime" SG_ 2566903051 Trailer5GeometricData_Content 100;
BA_ "GenSigCycleTimeActive" SG_ 2566903051 Trailer5GeometricData_Content 100;
BA_ "GenSigStartValue" SG_ 2566903051 Trailer5GeometricData_Content 255;
BA_ "GenSigMaxLatency" SG_ 2566903051 Trailer5GeometricData_Content 1010;
BA_ "Platform_VMCU1_Sig" SG_ 2566903051 Trailer5GeometricData_Content 1;
BA_ "GenSigCycleTime" SG_ 2566903051 LiningWearWarning 100;
BA_ "GenSigCycleTimeActive" SG_ 2566903051 LiningWearWarning 100;
BA_ "GenSigStartValue" SG_ 2566903051 LiningWearWarning 3;
BA_ "Platform_VMCU1_Sig" SG_ 2566903051 LiningWearWarning 1;
BA_ "GenSigCycleTime" SG_ 2566902539 Trailer3GeometricData_Index 100;
BA_ "GenSigCycleTimeActive" SG_ 2566902539 Trailer3GeometricData_Index 100;
BA_ "GenSigStartValue" SG_ 2566902539 Trailer3GeometricData_Index 255;
BA_ "GenSigMaxLatency" SG_ 2566902539 Trailer3GeometricData_Index 1012;
BA_ "Platform_VMCU1_Sig" SG_ 2566902539 Trailer3GeometricData_Index 1;
BA_ "GenSigCycleTime" SG_ 2566902539 Trailer4GeometricData_Content 100;
BA_ "GenSigCycleTimeActive" SG_ 2566902539 Trailer4GeometricData_Content 100;
BA_ "GenSigStartValue" SG_ 2566902539 Trailer4GeometricData_Content 255;
BA_ "GenSigMaxLatency" SG_ 2566902539 Trailer4GeometricData_Content 1012;
BA_ "Platform_VMCU1_Sig" SG_ 2566902539 Trailer4GeometricData_Content 1;
BA_ "GenSigCycleTime" SG_ 2566902539 Trailer3GeometricData_Content 100;
BA_ "GenSigCycleTimeActive" SG_ 2566902539 Trailer3GeometricData_Content 100;
BA_ "GenSigStartValue" SG_ 2566902539 Trailer3GeometricData_Content 255;
BA_ "GenSigMaxLatency" SG_ 2566902539 Trailer3GeometricData_Content 1012;
BA_ "Platform_VMCU1_Sig" SG_ 2566902539 Trailer3GeometricData_Content 1;
BA_ "GenSigCycleTime" SG_ 2566902539 Trailer3AxleLoadSum 100;
BA_ "GenSigCycleTimeActive" SG_ 2566902539 Trailer3AxleLoadSum 100;
BA_ "GenSigStartValue" SG_ 2566902539 Trailer3AxleLoadSum 65535;
BA_ "GenSigMaxLatency" SG_ 2566902539 Trailer3AxleLoadSum 1012;
BA_ "Platform_VMCU1_Sig" SG_ 2566902539 Trailer3AxleLoadSum 1;
BA_ "GenSigCycleTime" SG_ 2566902539 Trailer4GeometricData_Index 100;
BA_ "GenSigCycleTimeActive" SG_ 2566902539 Trailer4GeometricData_Index 100;
BA_ "GenSigStartValue" SG_ 2566902539 Trailer4GeometricData_Index 255;
BA_ "GenSigMaxLatency" SG_ 2566902539 Trailer4GeometricData_Index 1012;
BA_ "Platform_VMCU1_Sig" SG_ 2566902539 Trailer4GeometricData_Index 1;
BA_ "GenSigCycleTime" SG_ 2566902539 Trailer4AxleLoadSum 100;
BA_ "GenSigCycleTimeActive" SG_ 2566902539 Trailer4AxleLoadSum 100;
BA_ "GenSigStartValue" SG_ 2566902539 Trailer4AxleLoadSum 65535;
BA_ "GenSigMaxLatency" SG_ 2566902539 Trailer4AxleLoadSum 1012;
BA_ "Platform_VMCU1_Sig" SG_ 2566902539 Trailer4AxleLoadSum 1;
BA_ "GenSigCycleTime" SG_ 2566902027 Trailer2GeometricData_Index 100;
BA_ "GenSigCycleTimeActive" SG_ 2566902027 Trailer2GeometricData_Index 100;
BA_ "GenSigStartValue" SG_ 2566902027 Trailer2GeometricData_Index 255;
BA_ "GenSigMaxLatency" SG_ 2566902027 Trailer2GeometricData_Index 1011;
BA_ "Platform_VMCU1_Sig" SG_ 2566902027 Trailer2GeometricData_Index 1;
BA_ "GenSigCycleTime" SG_ 2566902027 Trailer1GeometricData_Content 100;
BA_ "GenSigCycleTimeActive" SG_ 2566902027 Trailer1GeometricData_Content 100;
BA_ "GenSigStartValue" SG_ 2566902027 Trailer1GeometricData_Content 255;
BA_ "GenSigMaxLatency" SG_ 2566902027 Trailer1GeometricData_Content 1011;
BA_ "Platform_VMCU1_Sig" SG_ 2566902027 Trailer1GeometricData_Content 1;
BA_ "GenSigCycleTime" SG_ 2566902027 Trailer1GeometricData_Index 100;
BA_ "GenSigCycleTimeActive" SG_ 2566902027 Trailer1GeometricData_Index 100;
BA_ "GenSigStartValue" SG_ 2566902027 Trailer1GeometricData_Index 255;
BA_ "GenSigMaxLatency" SG_ 2566902027 Trailer1GeometricData_Index 1011;
BA_ "Platform_VMCU1_Sig" SG_ 2566902027 Trailer1GeometricData_Index 1;
BA_ "GenSigCycleTime" SG_ 2566902027 Trailer2AxleLoadSum 100;
BA_ "GenSigCycleTimeActive" SG_ 2566902027 Trailer2AxleLoadSum 100;
BA_ "GenSigStartValue" SG_ 2566902027 Trailer2AxleLoadSum 65535;
BA_ "GenSigMaxLatency" SG_ 2566902027 Trailer2AxleLoadSum 1011;
BA_ "Platform_VMCU1_Sig" SG_ 2566902027 Trailer2AxleLoadSum 1;
BA_ "GenSigCycleTime" SG_ 2566902027 Trailer1AxleLoadSum 100;
BA_ "GenSigCycleTimeActive" SG_ 2566902027 Trailer1AxleLoadSum 100;
BA_ "GenSigStartValue" SG_ 2566902027 Trailer1AxleLoadSum 65535;
BA_ "GenSigMaxLatency" SG_ 2566902027 Trailer1AxleLoadSum 1011;
BA_ "Platform_VMCU1_Sig" SG_ 2566902027 Trailer1AxleLoadSum 1;
BA_ "GenSigCycleTime" SG_ 2566902027 Trailer2GeometricData_Content 100;
BA_ "GenSigCycleTimeActive" SG_ 2566902027 Trailer2GeometricData_Content 100;
BA_ "GenSigStartValue" SG_ 2566902027 Trailer2GeometricData_Content 255;
BA_ "GenSigMaxLatency" SG_ 2566902027 Trailer2GeometricData_Content 1011;
BA_ "Platform_VMCU1_Sig" SG_ 2566902027 Trailer2GeometricData_Content 1;
BA_ "GenSigCycleTime" SG_ 2566886667 Trailer5LiftAxle1Pos 100;
BA_ "GenSigCycleTimeActive" SG_ 2566886667 Trailer5LiftAxle1Pos 100;
BA_ "GenSigStartValue" SG_ 2566886667 Trailer5LiftAxle1Pos 3;
BA_ "GenSigMaxLatency" SG_ 2566886667 Trailer5LiftAxle1Pos 111;
BA_ "Platform_VMCU1_Sig" SG_ 2566886667 Trailer5LiftAxle1Pos 1;
BA_ "GenSigCycleTime" SG_ 2566886667 EHSClutchEngagmntOffsetOpStat 100;
BA_ "GenSigCycleTimeActive" SG_ 2566886667 EHSClutchEngagmntOffsetOpStat 100;
BA_ "GenSigStartValue" SG_ 2566886667 EHSClutchEngagmntOffsetOpStat 63;
BA_ "GenSigCycleTime" SG_ 2566886667 Trailer5LiftAxle2Pos 100;
BA_ "GenSigCycleTimeActive" SG_ 2566886667 Trailer5LiftAxle2Pos 100;
BA_ "GenSigStartValue" SG_ 2566886667 Trailer5LiftAxle2Pos 3;
BA_ "GenSigMaxLatency" SG_ 2566886667 Trailer5LiftAxle2Pos 111;
BA_ "Platform_VMCU1_Sig" SG_ 2566886667 Trailer5LiftAxle2Pos 1;
BA_ "GenSigCycleTime" SG_ 2566886667 Trailer5AxleLoad_AxleLoad 100;
BA_ "GenSigCycleTimeActive" SG_ 2566886667 Trailer5AxleLoad_AxleLoad 100;
BA_ "GenSigStartValue" SG_ 2566886667 Trailer5AxleLoad_AxleLoad 65535;
BA_ "GenSigMaxLatency" SG_ 2566886667 Trailer5AxleLoad_AxleLoad 111;
BA_ "Platform_VMCU1_Sig" SG_ 2566886667 Trailer5AxleLoad_AxleLoad 1;
BA_ "GenSigCycleTime" SG_ 2566886667 Trailer5AxleLoad_AxleId 100;
BA_ "GenSigCycleTimeActive" SG_ 2566886667 Trailer5AxleLoad_AxleId 100;
BA_ "GenSigMaxLatency" SG_ 2566886667 Trailer5AxleLoad_AxleId 111;
BA_ "Platform_VMCU1_Sig" SG_ 2566886667 Trailer5AxleLoad_AxleId 1;
BA_ "GenSigCycleTime" SG_ 2566886155 Trailer3AxleLoad_AxleId 100;
BA_ "GenSigCycleTimeActive" SG_ 2566886155 Trailer3AxleLoad_AxleId 100;
BA_ "GenSigMaxLatency" SG_ 2566886155 Trailer3AxleLoad_AxleId 110;
BA_ "Platform_VMCU1_Sig" SG_ 2566886155 Trailer3AxleLoad_AxleId 1;
BA_ "GenSigCycleTime" SG_ 2566886155 FrontParkBrakeOverrideStatus 100;
BA_ "GenSigCycleTimeActive" SG_ 2566886155 FrontParkBrakeOverrideStatus 100;
BA_ "GenSigStartValue" SG_ 2566886155 FrontParkBrakeOverrideStatus 3;
BA_ "Platform_VMCU1_Sig" SG_ 2566886155 FrontParkBrakeOverrideStatus 1;
BA_ "SeToolAncestorID_SIGNAL" SG_ 2566886155 FrontParkBrakeOverrideStatus "x0000001D04131A22";
BA_ "SeToolItemID_SIGNAL" SG_ 2566886155 FrontParkBrakeOverrideStatus "x0000001D04131A22";
BA_ "SeToolName_SIGNAL" SG_ 2566886155 FrontParkBrakeOverrideStatus "FrontParkBrakeOverrideStatus";
BA_ "SeToolVersion_SIGNAL" SG_ 2566886155 FrontParkBrakeOverrideStatus "1";
BA_ "GenSigCycleTime" SG_ 2566886155 Trailer3LiftAxle1Pos 100;
BA_ "GenSigCycleTimeActive" SG_ 2566886155 Trailer3LiftAxle1Pos 100;
BA_ "GenSigStartValue" SG_ 2566886155 Trailer3LiftAxle1Pos 3;
BA_ "GenSigMaxLatency" SG_ 2566886155 Trailer3LiftAxle1Pos 110;
BA_ "Platform_VMCU1_Sig" SG_ 2566886155 Trailer3LiftAxle1Pos 1;
BA_ "GenSigCycleTime" SG_ 2566886155 Trailer4LiftAxle2Pos 100;
BA_ "GenSigCycleTimeActive" SG_ 2566886155 Trailer4LiftAxle2Pos 100;
BA_ "GenSigStartValue" SG_ 2566886155 Trailer4LiftAxle2Pos 3;
BA_ "GenSigMaxLatency" SG_ 2566886155 Trailer4LiftAxle2Pos 110;
BA_ "Platform_VMCU1_Sig" SG_ 2566886155 Trailer4LiftAxle2Pos 1;
BA_ "GenSigCycleTime" SG_ 2566886155 Trailer4AxleLoad_AxleLoad 100;
BA_ "GenSigCycleTimeActive" SG_ 2566886155 Trailer4AxleLoad_AxleLoad 100;
BA_ "GenSigStartValue" SG_ 2566886155 Trailer4AxleLoad_AxleLoad 65535;
BA_ "GenSigMaxLatency" SG_ 2566886155 Trailer4AxleLoad_AxleLoad 110;
BA_ "Platform_VMCU1_Sig" SG_ 2566886155 Trailer4AxleLoad_AxleLoad 1;
BA_ "GenSigCycleTime" SG_ 2566886155 Trailer3LiftAxle2Pos 100;
BA_ "GenSigCycleTimeActive" SG_ 2566886155 Trailer3LiftAxle2Pos 100;
BA_ "GenSigStartValue" SG_ 2566886155 Trailer3LiftAxle2Pos 3;
BA_ "GenSigMaxLatency" SG_ 2566886155 Trailer3LiftAxle2Pos 110;
BA_ "Platform_VMCU1_Sig" SG_ 2566886155 Trailer3LiftAxle2Pos 1;
BA_ "GenSigCycleTime" SG_ 2566886155 Trailer3AxleLoad_AxleLoad 100;
BA_ "GenSigCycleTimeActive" SG_ 2566886155 Trailer3AxleLoad_AxleLoad 100;
BA_ "GenSigStartValue" SG_ 2566886155 Trailer3AxleLoad_AxleLoad 65535;
BA_ "GenSigMaxLatency" SG_ 2566886155 Trailer3AxleLoad_AxleLoad 110;
BA_ "Platform_VMCU1_Sig" SG_ 2566886155 Trailer3AxleLoad_AxleLoad 1;
BA_ "GenSigCycleTime" SG_ 2566886155 Trailer4LiftAxle1Pos 100;
BA_ "GenSigCycleTimeActive" SG_ 2566886155 Trailer4LiftAxle1Pos 100;
BA_ "GenSigStartValue" SG_ 2566886155 Trailer4LiftAxle1Pos 3;
BA_ "GenSigMaxLatency" SG_ 2566886155 Trailer4LiftAxle1Pos 110;
BA_ "Platform_VMCU1_Sig" SG_ 2566886155 Trailer4LiftAxle1Pos 1;
BA_ "GenSigCycleTime" SG_ 2566886155 Trailer4AxleLoad_AxleId 100;
BA_ "GenSigCycleTimeActive" SG_ 2566886155 Trailer4AxleLoad_AxleId 100;
BA_ "GenSigMaxLatency" SG_ 2566886155 Trailer4AxleLoad_AxleId 110;
BA_ "Platform_VMCU1_Sig" SG_ 2566886155 Trailer4AxleLoad_AxleId 1;
BA_ "GenSigCycleTime" SG_ 2566885643 Trailer2AxleLoad_AxleId 100;
BA_ "GenSigCycleTimeActive" SG_ 2566885643 Trailer2AxleLoad_AxleId 100;
BA_ "GenSigMaxLatency" SG_ 2566885643 Trailer2AxleLoad_AxleId 109;
BA_ "Platform_VMCU1_Sig" SG_ 2566885643 Trailer2AxleLoad_AxleId 1;
BA_ "GenSigCycleTime" SG_ 2566885643 Trailer2LiftAxle2Pos 100;
BA_ "GenSigCycleTimeActive" SG_ 2566885643 Trailer2LiftAxle2Pos 100;
BA_ "GenSigStartValue" SG_ 2566885643 Trailer2LiftAxle2Pos 3;
BA_ "GenSigMaxLatency" SG_ 2566885643 Trailer2LiftAxle2Pos 109;
BA_ "Platform_VMCU1_Sig" SG_ 2566885643 Trailer2LiftAxle2Pos 1;
BA_ "GenSigCycleTime" SG_ 2566885643 Trailer2AxleLoad_AxleLoad 100;
BA_ "GenSigCycleTimeActive" SG_ 2566885643 Trailer2AxleLoad_AxleLoad 100;
BA_ "GenSigStartValue" SG_ 2566885643 Trailer2AxleLoad_AxleLoad 65535;
BA_ "GenSigMaxLatency" SG_ 2566885643 Trailer2AxleLoad_AxleLoad 109;
BA_ "Platform_VMCU1_Sig" SG_ 2566885643 Trailer2AxleLoad_AxleLoad 1;
BA_ "GenSigCycleTime" SG_ 2566885643 TrailerEBSFault 100;
BA_ "GenSigCycleTimeActive" SG_ 2566885643 TrailerEBSFault 100;
BA_ "GenSigStartValue" SG_ 2566885643 TrailerEBSFault 3;
BA_ "GenSigMaxLatency" SG_ 2566885643 TrailerEBSFault 109;
BA_ "Platform_VMCU1_Sig" SG_ 2566885643 TrailerEBSFault 1;
BA_ "GenSigCycleTime" SG_ 2566885643 Trailer1LiftAxle1Pos 100;
BA_ "GenSigCycleTimeActive" SG_ 2566885643 Trailer1LiftAxle1Pos 100;
BA_ "GenSigStartValue" SG_ 2566885643 Trailer1LiftAxle1Pos 3;
BA_ "GenSigMaxLatency" SG_ 2566885643 Trailer1LiftAxle1Pos 109;
BA_ "Platform_VMCU1_Sig" SG_ 2566885643 Trailer1LiftAxle1Pos 1;
BA_ "GenSigCycleTime" SG_ 2566885643 Trailer1AxleLoad_AxleId 100;
BA_ "GenSigCycleTimeActive" SG_ 2566885643 Trailer1AxleLoad_AxleId 100;
BA_ "GenSigMaxLatency" SG_ 2566885643 Trailer1AxleLoad_AxleId 109;
BA_ "Platform_VMCU1_Sig" SG_ 2566885643 Trailer1AxleLoad_AxleId 1;
BA_ "GenSigCycleTime" SG_ 2566885643 Trailer1AxleLoad_AxleLoad 100;
BA_ "GenSigCycleTimeActive" SG_ 2566885643 Trailer1AxleLoad_AxleLoad 100;
BA_ "GenSigStartValue" SG_ 2566885643 Trailer1AxleLoad_AxleLoad 65535;
BA_ "GenSigMaxLatency" SG_ 2566885643 Trailer1AxleLoad_AxleLoad 109;
BA_ "Platform_VMCU1_Sig" SG_ 2566885643 Trailer1AxleLoad_AxleLoad 1;
BA_ "GenSigCycleTime" SG_ 2566885643 TrailersConnected 100;
BA_ "GenSigCycleTimeActive" SG_ 2566885643 TrailersConnected 100;
BA_ "GenSigStartValue" SG_ 2566885643 TrailersConnected 7;
BA_ "GenSigMaxLatency" SG_ 2566885643 TrailersConnected 1010;
BA_ "Platform_VMCU1_Sig" SG_ 2566885643 TrailersConnected 1;
BA_ "GenSigCycleTime" SG_ 2566885643 Trailer1LiftAxle2Pos 100;
BA_ "GenSigCycleTimeActive" SG_ 2566885643 Trailer1LiftAxle2Pos 100;
BA_ "GenSigStartValue" SG_ 2566885643 Trailer1LiftAxle2Pos 3;
BA_ "GenSigMaxLatency" SG_ 2566885643 Trailer1LiftAxle2Pos 109;
BA_ "Platform_VMCU1_Sig" SG_ 2566885643 Trailer1LiftAxle2Pos 1;
BA_ "GenSigCycleTime" SG_ 2566885643 Trailer2LiftAxle1Pos 100;
BA_ "GenSigCycleTimeActive" SG_ 2566885643 Trailer2LiftAxle1Pos 100;
BA_ "GenSigStartValue" SG_ 2566885643 Trailer2LiftAxle1Pos 3;
BA_ "GenSigMaxLatency" SG_ 2566885643 Trailer2LiftAxle1Pos 109;
BA_ "Platform_VMCU1_Sig" SG_ 2566885643 Trailer2LiftAxle1Pos 1;
BA_ "GenSigCycleTime" SG_ 2566906635 PredictedMileageOfNextPadChg 100;
BA_ "GenSigCycleTimeActive" SG_ 2566906635 PredictedMileageOfNextPadChg 100;
BA_ "GenSigStartValue" SG_ 2566906635 PredictedMileageOfNextPadChg 4294967295;
BA_ "Platform_VMCU1_Sig" SG_ 2566906635 PredictedMileageOfNextPadChg 1;
BA_ "GenSigCycleTime" SG_ 2566906635 PadChgPredictionLastPadChg 100;
BA_ "GenSigCycleTimeActive" SG_ 2566906635 PadChgPredictionLastPadChg 100;
BA_ "GenSigStartValue" SG_ 2566906635 PadChgPredictionLastPadChg 4294967295;
BA_ "Platform_VMCU1_Sig" SG_ 2566906635 PadChgPredictionLastPadChg 1;
BA_ "GenSigCycleTime" SG_ 2499761675 BadBrakeBalanceWarning 100;
BA_ "GenSigCycleTimeActive" SG_ 2499761675 BadBrakeBalanceWarning 100;
BA_ "GenSigStartValue" SG_ 2499761675 BadBrakeBalanceWarning 3;
BA_ "GenSigMaxLatency" SG_ 2499761675 BadBrakeBalanceWarning 60;
BA_ "Platform_VMCU1_Sig" SG_ 2499761675 BadBrakeBalanceWarning 1;
BA_ "SeToolAncestorID_SIGNAL" SG_ 2499761675 BadBrakeBalanceWarning "x0000001D041674F5";
BA_ "SeToolItemID_SIGNAL" SG_ 2499761675 BadBrakeBalanceWarning "x0000001D041674F5";
BA_ "SeToolName_SIGNAL" SG_ 2499761675 BadBrakeBalanceWarning "BadBrakeBalanceWarning";
BA_ "SeToolVersion_SIGNAL" SG_ 2499761675 BadBrakeBalanceWarning "1";
BA_ "GenSigCycleTime" SG_ 2499761675 HSAAvailability 100;
BA_ "GenSigCycleTimeActive" SG_ 2499761675 HSAAvailability 100;
BA_ "GenSigStartValue" SG_ 2499761675 HSAAvailability 3;
BA_ "GenSigMaxLatency" SG_ 2499761675 HSAAvailability 60;
BA_ "Platform_VMCU1_Sig" SG_ 2499761675 HSAAvailability 1;
BA_ "SeToolAncestorID_SIGNAL" SG_ 2499761675 HSAAvailability "x0000001D0410DBE6";
BA_ "SeToolItemID_SIGNAL" SG_ 2499761675 HSAAvailability "x0000001D0410DBE6";
BA_ "SeToolName_SIGNAL" SG_ 2499761675 HSAAvailability "HSAAvailability";
BA_ "SeToolVersion_SIGNAL" SG_ 2499761675 HSAAvailability "1";
BA_ "GenSigCycleTime" SG_ 2499761675 DTCActive 100;
BA_ "GenSigCycleTimeActive" SG_ 2499761675 DTCActive 100;
BA_ "GenSigStartValue" SG_ 2499761675 DTCActive 3;
BA_ "Platform_VMCU1_Sig" SG_ 2499761675 DTCActive 1;
BA_ "GenSigCycleTime" SG_ 2499761675 StretchBrake_Stat 100;
BA_ "GenSigCycleTimeActive" SG_ 2499761675 StretchBrake_Stat 100;
BA_ "GenSigStartValue" SG_ 2499761675 StretchBrake_Stat 7;
BA_ "Platform_VMCU1_Sig" SG_ 2499761675 StretchBrake_Stat 1;
BA_ "GenSigCycleTime" SG_ 2499761675 TrcnCtrlSlipperyRoadWarning 100;
BA_ "GenSigCycleTimeActive" SG_ 2499761675 TrcnCtrlSlipperyRoadWarning 100;
BA_ "GenSigStartValue" SG_ 2499761675 TrcnCtrlSlipperyRoadWarning 3;
BA_ "GenSigMaxLatency" SG_ 2499761675 TrcnCtrlSlipperyRoadWarning 60;
BA_ "Platform_VMCU1_Sig" SG_ 2499761675 TrcnCtrlSlipperyRoadWarning 1;
BA_ "SeToolAncestorID_SIGNAL" SG_ 2499761675 TrcnCtrlSlipperyRoadWarning "x0000001D04125C5E";
BA_ "SeToolItemID_SIGNAL" SG_ 2499761675 TrcnCtrlSlipperyRoadWarning "x0000001D04125C5E";
BA_ "SeToolName_SIGNAL" SG_ 2499761675 TrcnCtrlSlipperyRoadWarning "TractionControlSlipperyRoadWarning";
BA_ "SeToolVersion_SIGNAL" SG_ 2499761675 TrcnCtrlSlipperyRoadWarning "1";
BA_ "GenSigCycleTime" SG_ 2499761675 RearAxleDiffLockActvnFuncReq 100;
BA_ "GenSigCycleTimeActive" SG_ 2499761675 RearAxleDiffLockActvnFuncReq 100;
BA_ "GenSigStartValue" SG_ 2499761675 RearAxleDiffLockActvnFuncReq 3;
BA_ "GenSigMaxLatency" SG_ 2499761675 RearAxleDiffLockActvnFuncReq 60;
BA_ "NeedsUpdateBit" SG_ 2499761675 RearAxleDiffLockActvnFuncReq 1;
BA_ "Platform_VMCU1_Sig" SG_ 2499761675 RearAxleDiffLockActvnFuncReq 1;
BA_ "SeToolAncestorID_SIGNAL" SG_ 2499761675 RearAxleDiffLockActvnFuncReq "x0000001D0412880F";
BA_ "SeToolItemID_SIGNAL" SG_ 2499761675 RearAxleDiffLockActvnFuncReq "x0000001D0412880F";
BA_ "SeToolName_SIGNAL" SG_ 2499761675 RearAxleDiffLockActvnFuncReq "RearAxleDiffLockActivationFunctionRequest";
BA_ "SeToolVersion_SIGNAL" SG_ 2499761675 RearAxleDiffLockActvnFuncReq "1";
BA_ "GenSigCycleTime" SG_ 2499761675 BrakeTempWarningLevel 100;
BA_ "GenSigCycleTimeActive" SG_ 2499761675 BrakeTempWarningLevel 100;
BA_ "GenSigStartValue" SG_ 2499761675 BrakeTempWarningLevel 255;
BA_ "Platform_VMCU1_Sig" SG_ 2499761675 BrakeTempWarningLevel 1;
BA_ "SeToolAncestorID_SIGNAL" SG_ 2499761675 BrakeTempWarningLevel "x0000001D0417DD85";
BA_ "SeToolItemID_SIGNAL" SG_ 2499761675 BrakeTempWarningLevel "x0000001D0417DD85";
BA_ "SeToolName_SIGNAL" SG_ 2499761675 BrakeTempWarningLevel "BrakeTempartureWarningLevelPercentage";
BA_ "SeToolVersion_SIGNAL" SG_ 2499761675 BrakeTempWarningLevel "1";
BA_ "GenSigCycleTime" SG_ 2499761675 RollerBenchModeStatus 100;
BA_ "GenSigCycleTimeActive" SG_ 2499761675 RollerBenchModeStatus 100;
BA_ "GenSigStartValue" SG_ 2499761675 RollerBenchModeStatus 3;
BA_ "GenSigMaxLatency" SG_ 2499761675 RollerBenchModeStatus 60;
BA_ "Platform_VMCU1_Sig" SG_ 2499761675 RollerBenchModeStatus 1;
BA_ "SeToolAncestorID_SIGNAL" SG_ 2499761675 RollerBenchModeStatus "x0000001D0412BB57";
BA_ "SeToolItemID_SIGNAL" SG_ 2499761675 RollerBenchModeStatus "x0000001D0412BB57";
BA_ "SeToolName_SIGNAL" SG_ 2499761675 RollerBenchModeStatus "RollerBenchModeStatus";
BA_ "SeToolVersion_SIGNAL" SG_ 2499761675 RollerBenchModeStatus "1";
BA_ "GenSigCycleTime" SG_ 2499761675 BrakeAssistStatus 100;
BA_ "GenSigCycleTimeActive" SG_ 2499761675 BrakeAssistStatus 100;
BA_ "GenSigStartValue" SG_ 2499761675 BrakeAssistStatus 3;
BA_ "Platform_VMCU1_Sig" SG_ 2499761675 BrakeAssistStatus 1;
BA_ "GenSigCycleTime" SG_ 2499761675 LongitudinalAcceleration 100;
BA_ "GenSigCycleTimeActive" SG_ 2499761675 LongitudinalAcceleration 100;
BA_ "GenSigStartValue" SG_ 2499761675 LongitudinalAcceleration 65535;
BA_ "Platform_VMCU1_Sig" SG_ 2499761675 LongitudinalAcceleration 1;
BA_ "GenSigCycleTime" SG_ 2499761675 TractionFunctionSelected 100;
BA_ "GenSigCycleTimeActive" SG_ 2499761675 TractionFunctionSelected 100;
BA_ "GenSigStartValue" SG_ 2499761675 TractionFunctionSelected 7;
BA_ "Platform_VMCU1_Sig" SG_ 2499761675 TractionFunctionSelected 1;
BA_ "GenSigCycleTime" SG_ 2499761675 PoorBrakePerformanceWarning 100;
BA_ "GenSigCycleTimeActive" SG_ 2499761675 PoorBrakePerformanceWarning 100;
BA_ "GenSigStartValue" SG_ 2499761675 PoorBrakePerformanceWarning 3;
BA_ "GenSigMaxLatency" SG_ 2499761675 PoorBrakePerformanceWarning 60;
BA_ "Platform_VMCU1_Sig" SG_ 2499761675 PoorBrakePerformanceWarning 1;
BA_ "SeToolAncestorID_SIGNAL" SG_ 2499761675 PoorBrakePerformanceWarning "x0000001D04161723";
BA_ "SeToolItemID_SIGNAL" SG_ 2499761675 PoorBrakePerformanceWarning "x0000001D04161723";
BA_ "SeToolName_SIGNAL" SG_ 2499761675 PoorBrakePerformanceWarning "PoorBrakePerformanceWarning";
BA_ "SeToolVersion_SIGNAL" SG_ 2499761675 PoorBrakePerformanceWarning "1";
BA_ "GenSigCycleTime" SG_ 2499761675 VDCActive 100;
BA_ "GenSigCycleTimeActive" SG_ 2499761675 VDCActive 100;
BA_ "GenSigStartValue" SG_ 2499761675 VDCActive 3;
BA_ "Platform_VMCU1_Sig" SG_ 2499761675 VDCActive 1;
BA_ "GenSigCycleTime" SG_ 2499761675 ABSInhibitionStatus 100;
BA_ "GenSigCycleTimeActive" SG_ 2499761675 ABSInhibitionStatus 100;
BA_ "GenSigStartValue" SG_ 2499761675 ABSInhibitionStatus 3;
BA_ "GenSigMaxLatency" SG_ 2499761675 ABSInhibitionStatus 60;
BA_ "Platform_VMCU1_Sig" SG_ 2499761675 ABSInhibitionStatus 1;
BA_ "SeToolAncestorID_SIGNAL" SG_ 2499761675 ABSInhibitionStatus "x0000001D0412B5DD";
BA_ "SeToolItemID_SIGNAL" SG_ 2499761675 ABSInhibitionStatus "x0000001D042957DE";
BA_ "SeToolName_SIGNAL" SG_ 2499761675 ABSInhibitionStatus "ABSInhibitionStatus";
BA_ "SeToolVersion_SIGNAL" SG_ 2499761675 ABSInhibitionStatus "2";
BA_ "GenSigCycleTime" SG_ 2499761675 ABSManAutoInhibitionStat 100;
BA_ "GenSigCycleTimeActive" SG_ 2499761675 ABSManAutoInhibitionStat 100;
BA_ "GenSigStartValue" SG_ 2499761675 ABSManAutoInhibitionStat 7;
BA_ "Platform_VMCU1_Sig" SG_ 2499761675 ABSManAutoInhibitionStat 1;
BA_ "GenSigCycleTime" SG_ 2499761675 RearAxleSteeringFunctionStatus 100;
BA_ "GenSigCycleTimeActive" SG_ 2499761675 RearAxleSteeringFunctionStatus 100;
BA_ "GenSigStartValue" SG_ 2499761675 RearAxleSteeringFunctionStatus 7;
BA_ "Platform_VMCU1_Sig" SG_ 2499761675 RearAxleSteeringFunctionStatus 1;
BA_ "GenSigCycleTime" SG_ 2499761675 AutoRearAxleDiffLockFnc_stat 100;
BA_ "GenSigCycleTimeActive" SG_ 2499761675 AutoRearAxleDiffLockFnc_stat 100;
BA_ "GenSigStartValue" SG_ 2499761675 AutoRearAxleDiffLockFnc_stat 3;
BA_ "Platform_VMCU1_Sig" SG_ 2499761675 AutoRearAxleDiffLockFnc_stat 1;
BA_ "GenSigSendType" SG_ 2499761675 RearAxleDiffLockActvnFuncReq_UB 7;
BA_ "Platform_VMCU1_Sig" SG_ 2499761675 RearAxleDiffLockActvnFuncReq_UB 1;
BA_ "GenSigCycleTime" SG_ 2499761675 WheelBrakeWarning 100;
BA_ "GenSigCycleTimeActive" SG_ 2499761675 WheelBrakeWarning 100;
BA_ "GenSigStartValue" SG_ 2499761675 WheelBrakeWarning 3;
BA_ "GenSigMaxLatency" SG_ 2499761675 WheelBrakeWarning 60;
BA_ "Platform_VMCU1_Sig" SG_ 2499761675 WheelBrakeWarning 1;
BA_ "SeToolAncestorID_SIGNAL" SG_ 2499761675 WheelBrakeWarning "x0000001D041665AA";
BA_ "SeToolItemID_SIGNAL" SG_ 2499761675 WheelBrakeWarning "x0000001D041665AA";
BA_ "SeToolName_SIGNAL" SG_ 2499761675 WheelBrakeWarning "WheelBrakeWarning";
BA_ "SeToolVersion_SIGNAL" SG_ 2499761675 WheelBrakeWarning "1";
BA_REL_ "GenSigFirstTimeoutTime" BU_SG_REL_ CIOM SG_ 2566749463 FMS1_TellTaleStatus11 24000;
BA_REL_ "GenSigTimeoutTime" BU_SG_REL_ CIOM SG_ 2566749463 FMS1_TellTaleStatus11 6000;
BA_REL_ "GenSigFirstTimeoutTime" BU_SG_REL_ CIOM SG_ 2566749463 FMS1_TellTaleStatus3 24000;
BA_REL_ "GenSigTimeoutTime" BU_SG_REL_ CIOM SG_ 2566749463 FMS1_TellTaleStatus3 6000;
BA_REL_ "GenSigFirstTimeoutTime" BU_SG_REL_ CIOM SG_ 2566749463 FMS1_Blockid 24000;
BA_REL_ "GenSigTimeoutTime" BU_SG_REL_ CIOM SG_ 2566749463 FMS1_Blockid 6000;
BA_REL_ "GenSigFirstTimeoutTime" BU_SG_REL_ CIOM SG_ 2566749463 FMS1_TellTaleStatus2 24000;
BA_REL_ "GenSigTimeoutTime" BU_SG_REL_ CIOM SG_ 2566749463 FMS1_TellTaleStatus2 6000;
BA_REL_ "GenSigFirstTimeoutTime" BU_SG_REL_ CIOM SG_ 2566749463 FMS1_TellTaleStatus6 24000;
BA_REL_ "GenSigTimeoutTime" BU_SG_REL_ CIOM SG_ 2566749463 FMS1_TellTaleStatus6 6000;
BA_REL_ "GenSigFirstTimeoutTime" BU_SG_REL_ CIOM SG_ 2566749463 FMS1_TellTaleStatus7 24000;
BA_REL_ "GenSigTimeoutTime" BU_SG_REL_ CIOM SG_ 2566749463 FMS1_TellTaleStatus7 6000;
BA_REL_ "GenSigFirstTimeoutTime" BU_SG_REL_ CIOM SG_ 2566749463 FMS1_TellTaleStatus5 24000;
BA_REL_ "GenSigTimeoutTime" BU_SG_REL_ CIOM SG_ 2566749463 FMS1_TellTaleStatus5 6000;
BA_REL_ "GenSigFirstTimeoutTime" BU_SG_REL_ CIOM SG_ 2566749463 FMS1_TellTaleStatus13 24000;
BA_REL_ "GenSigTimeoutTime" BU_SG_REL_ CIOM SG_ 2566749463 FMS1_TellTaleStatus13 6000;
BA_REL_ "GenSigFirstTimeoutTime" BU_SG_REL_ CIOM SG_ 2566749463 FMS1_TellTaleStatus9 24000;
BA_REL_ "GenSigTimeoutTime" BU_SG_REL_ CIOM SG_ 2566749463 FMS1_TellTaleStatus9 6000;
BA_REL_ "GenSigFirstTimeoutTime" BU_SG_REL_ CIOM SG_ 2566749463 FMS1_TellTaleStatus1 24000;
BA_REL_ "GenSigTimeoutTime" BU_SG_REL_ CIOM SG_ 2566749463 FMS1_TellTaleStatus1 6000;
BA_REL_ "GenSigFirstTimeoutTime" BU_SG_REL_ CIOM SG_ 2566749463 FMS1_TellTaleStatus4 24000;
BA_REL_ "GenSigTimeoutTime" BU_SG_REL_ CIOM SG_ 2566749463 FMS1_TellTaleStatus4 6000;
BA_REL_ "GenSigFirstTimeoutTime" BU_SG_REL_ CIOM SG_ 2566749463 FMS1_TellTaleStatus12 24000;
BA_REL_ "GenSigTimeoutTime" BU_SG_REL_ CIOM SG_ 2566749463 FMS1_TellTaleStatus12 6000;
BA_REL_ "GenSigFirstTimeoutTime" BU_SG_REL_ CIOM SG_ 2566749463 FMS1_TellTaleStatus14 24000;
BA_REL_ "GenSigTimeoutTime" BU_SG_REL_ CIOM SG_ 2566749463 FMS1_TellTaleStatus14 6000;
BA_REL_ "GenSigFirstTimeoutTime" BU_SG_REL_ CIOM SG_ 2566749463 FMS1_TellTaleStatus8 24000;
BA_REL_ "GenSigTimeoutTime" BU_SG_REL_ CIOM SG_ 2566749463 FMS1_TellTaleStatus8 6000;
BA_REL_ "GenSigFirstTimeoutTime" BU_SG_REL_ CIOM SG_ 2566749463 FMS1_TellTaleStatus15 24000;
BA_REL_ "GenSigTimeoutTime" BU_SG_REL_ CIOM SG_ 2566749463 FMS1_TellTaleStatus15 6000;
BA_REL_ "GenSigFirstTimeoutTime" BU_SG_REL_ CIOM SG_ 2566749463 FMS1_TellTaleStatus10 24000;
BA_REL_ "GenSigTimeoutTime" BU_SG_REL_ CIOM SG_ 2566749463 FMS1_TellTaleStatus10 6000;
BA_REL_ "GenSigFirstTimeoutTime" BU_SG_REL_ HMIIOM SG_ 2566801923 TransmissionRequestedGearFdbk 3000;
BA_REL_ "GenSigTimeoutTime" BU_SG_REL_ HMIIOM SG_ 2566801923 TransmissionRequestedGearFdbk 600;
BA_REL_ "GenSigFirstTimeoutTime" BU_SG_REL_ VMCU SG_ 2566801923 TransmEngineCrankEnable2 3000;
BA_REL_ "GenSigTimeoutTime" BU_SG_REL_ VMCU SG_ 2566801923 TransmEngineCrankEnable2 600;
BA_REL_ "GenSigFirstTimeoutTime" BU_SG_REL_ BBM SG_ 2565866755 TransmissionActualGearRatio 3000;
BA_REL_ "GenSigTimeoutTime" BU_SG_REL_ BBM SG_ 2565866755 TransmissionActualGearRatio 600;
BA_REL_ "GenSigFirstTimeoutTime" BU_SG_REL_ DACU SG_ 2565866755 TransmissionActualGearRatio 3000;
BA_REL_ "GenSigTimeoutTime" BU_SG_REL_ DACU SG_ 2565866755 TransmissionActualGearRatio 600;
BA_REL_ "GenSigFirstTimeoutTime" BU_SG_REL_ EMS SG_ 2565866755 TransmissionActualGearRatio 3000;
BA_REL_ "GenSigTimeoutTime" BU_SG_REL_ EMS SG_ 2565866755 TransmissionActualGearRatio 600;
BA_REL_ "GenSigFirstTimeoutTime" BU_SG_REL_ VMCU SG_ 2565866755 TransmissionActualGearRatio 3000;
BA_REL_ "GenSigTimeoutTime" BU_SG_REL_ VMCU SG_ 2565866755 TransmissionActualGearRatio 600;
BA_REL_ "GenSigFirstTimeoutTime" BU_SG_REL_ EMS SG_ 2565866755 TransmissionCurrentGear 3000;
BA_REL_ "GenSigTimeoutTime" BU_SG_REL_ EMS SG_ 2565866755 TransmissionCurrentGear 600;
BA_REL_ "GenSigFirstTimeoutTime" BU_SG_REL_ BBM SG_ 2565866755 TransmissionCurrentGear 3000;
BA_REL_ "GenSigTimeoutTime" BU_SG_REL_ BBM SG_ 2565866755 TransmissionCurrentGear 600;
BA_REL_ "GenSigFirstTimeoutTime" BU_SG_REL_ VMCU SG_ 2565866755 TransmissionCurrentGear 3000;
BA_REL_ "GenSigTimeoutTime" BU_SG_REL_ VMCU SG_ 2565866755 TransmissionCurrentGear 600;
BA_REL_ "GenSigFirstTimeoutTime" BU_SG_REL_ EBS SG_ 2565866755 TransmissionCurrentGear 3000;
BA_REL_ "GenSigTimeoutTime" BU_SG_REL_ EBS SG_ 2565866755 TransmissionCurrentGear 600;
BA_REL_ "GenSigFirstTimeoutTime" BU_SG_REL_ HMIIOM SG_ 2565866755 TransmissionCurrentGear 3000;
BA_REL_ "GenSigTimeoutTime" BU_SG_REL_ HMIIOM SG_ 2565866755 TransmissionCurrentGear 600;
BA_REL_ "GenSigFirstTimeoutTime" BU_SG_REL_ VMCU SG_ 2565866755 TransmissionRangeSelected 3000;
BA_REL_ "GenSigTimeoutTime" BU_SG_REL_ VMCU SG_ 2565866755 TransmissionRangeSelected 600;
BA_REL_ "GenSigFirstTimeoutTime" BU_SG_REL_ HMIIOM SG_ 2565866755 TransmissionRangeSelected 3000;
BA_REL_ "GenSigTimeoutTime" BU_SG_REL_ HMIIOM SG_ 2565866755 TransmissionRangeSelected 600;
BA_REL_ "GenSigFirstTimeoutTime" BU_SG_REL_ BBM SG_ 2565866755 TransmissionRangeSelected 3000;
BA_REL_ "GenSigTimeoutTime" BU_SG_REL_ BBM SG_ 2565866755 TransmissionRangeSelected 600;
BA_REL_ "GenSigFirstTimeoutTime" BU_SG_REL_ BBM SG_ 2565866755 TransmissionRangeAttained 3000;
BA_REL_ "GenSigTimeoutTime" BU_SG_REL_ BBM SG_ 2565866755 TransmissionRangeAttained 600;
BA_REL_ "GenSigFirstTimeoutTime" BU_SG_REL_ HMIIOM SG_ 2565866755 TransmissionRangeAttained 3000;
BA_REL_ "GenSigTimeoutTime" BU_SG_REL_ HMIIOM SG_ 2565866755 TransmissionRangeAttained 600;
BA_REL_ "GenSigFirstTimeoutTime" BU_SG_REL_ EMS SG_ 2565866755 TransmissionSelectedGear 3000;
BA_REL_ "GenSigTimeoutTime" BU_SG_REL_ EMS SG_ 2565866755 TransmissionSelectedGear 600;
BA_REL_ "GenSigFirstTimeoutTime" BU_SG_REL_ BBM SG_ 2565866755 TransmissionSelectedGear 3000;
BA_REL_ "GenSigTimeoutTime" BU_SG_REL_ BBM SG_ 2565866755 TransmissionSelectedGear 600;
BA_REL_ "GenSigFirstTimeoutTime" BU_SG_REL_ HMIIOM SG_ 2565866755 TransmissionSelectedGear 3000;
BA_REL_ "GenSigTimeoutTime" BU_SG_REL_ HMIIOM SG_ 2565866755 TransmissionSelectedGear 600;
BA_REL_ "GenSigFirstTimeoutTime" BU_SG_REL_ VMCU SG_ 2565866755 TransmissionSelectedGear 3000;
BA_REL_ "GenSigTimeoutTime" BU_SG_REL_ VMCU SG_ 2565866755 TransmissionSelectedGear 600;
BA_REL_ "GenSigFirstTimeoutTime" BU_SG_REL_ EBS SG_ 2364539395 PercentClutchSlip 3000;
BA_REL_ "GenSigTimeoutTime" BU_SG_REL_ EBS SG_ 2364539395 PercentClutchSlip 60;
BA_REL_ "GenSigFirstTimeoutTime" BU_SG_REL_ EMS SG_ 2364539395 PercentClutchSlip 3000;
BA_REL_ "GenSigTimeoutTime" BU_SG_REL_ EMS SG_ 2364539395 PercentClutchSlip 60;
BA_REL_ "GenSigFirstTimeoutTime" BU_SG_REL_ VMCU SG_ 2364539395 PercentClutchSlip 3000;
BA_REL_ "GenSigTimeoutTime" BU_SG_REL_ VMCU SG_ 2364539395 PercentClutchSlip 60;
BA_REL_ "GenSigFirstTimeoutTime" BU_SG_REL_ BBM SG_ 2364539395 PercentClutchSlip 3000;
BA_REL_ "GenSigTimeoutTime" BU_SG_REL_ BBM SG_ 2364539395 PercentClutchSlip 60;
BA_REL_ "GenSigFirstTimeoutTime" BU_SG_REL_ VMCU SG_ 2364539395 TransmissionOutputShaftSpeed2 3000;
BA_REL_ "GenSigTimeoutTime" BU_SG_REL_ VMCU SG_ 2364539395 TransmissionOutputShaftSpeed2 60;
BA_REL_ "GenSigFirstTimeoutTime" BU_SG_REL_ EMS SG_ 2364539395 TransmTrqConvrtrLockupEngd 3000;
BA_REL_ "GenSigTimeoutTime" BU_SG_REL_ EMS SG_ 2364539395 TransmTrqConvrtrLockupEngd 60;
BA_REL_ "GenSigFirstTimeoutTime" BU_SG_REL_ BBM SG_ 2364539395 TransmTrqConvrtrLockupEngd 3000;
BA_REL_ "GenSigTimeoutTime" BU_SG_REL_ BBM SG_ 2364539395 TransmTrqConvrtrLockupEngd 60;
BA_REL_ "GenSigFirstTimeoutTime" BU_SG_REL_ EMS SG_ 2364539395 TransmissionDrivelineEngaged 3000;
BA_REL_ "GenSigTimeoutTime" BU_SG_REL_ EMS SG_ 2364539395 TransmissionDrivelineEngaged 60;
BA_REL_ "GenSigFirstTimeoutTime" BU_SG_REL_ VMCU SG_ 2364539395 TransmissionDrivelineEngaged 3000;
BA_REL_ "GenSigTimeoutTime" BU_SG_REL_ VMCU SG_ 2364539395 TransmissionDrivelineEngaged 60;
BA_REL_ "GenSigFirstTimeoutTime" BU_SG_REL_ BBM SG_ 2364539395 TransmissionDrivelineEngaged 3000;
BA_REL_ "GenSigTimeoutTime" BU_SG_REL_ BBM SG_ 2364539395 TransmissionDrivelineEngaged 60;
BA_REL_ "GenSigFirstTimeoutTime" BU_SG_REL_ DACU SG_ 2364539395 TransmissionDrivelineEngaged 3000;
BA_REL_ "GenSigTimeoutTime" BU_SG_REL_ DACU SG_ 2364539395 TransmissionDrivelineEngaged 60;
BA_REL_ "GenSigFirstTimeoutTime" BU_SG_REL_ EBS SG_ 2364539395 TransmissionDrivelineEngaged 3000;
BA_REL_ "GenSigTimeoutTime" BU_SG_REL_ EBS SG_ 2364539395 TransmissionDrivelineEngaged 60;
BA_REL_ "GenSigFirstTimeoutTime" BU_SG_REL_ BBM SG_ 2364539395 TransmissionInputShaftSpeed 3000;
BA_REL_ "GenSigTimeoutTime" BU_SG_REL_ BBM SG_ 2364539395 TransmissionInputShaftSpeed 60;
BA_REL_ "GenSigFirstTimeoutTime" BU_SG_REL_ EBS SG_ 2364539395 TransmissionInputShaftSpeed 3000;
BA_REL_ "GenSigTimeoutTime" BU_SG_REL_ EBS SG_ 2364539395 TransmissionInputShaftSpeed 60;
BA_REL_ "GenSigFirstTimeoutTime" BU_SG_REL_ BBM SG_ 2364539395 MomentaryEngineOverspeedEnable 3000;
BA_REL_ "GenSigTimeoutTime" BU_SG_REL_ BBM SG_ 2364539395 MomentaryEngineOverspeedEnable 60;
BA_REL_ "GenSigFirstTimeoutTime" BU_SG_REL_ EMS SG_ 2364539395 MomentaryEngineOverspeedEnable 3000;
BA_REL_ "GenSigTimeoutTime" BU_SG_REL_ EMS SG_ 2364539395 MomentaryEngineOverspeedEnable 60;
BA_REL_ "GenSigFirstTimeoutTime" BU_SG_REL_ EMS SG_ 2364539395 TransmissionShiftInProcess 3000;
BA_REL_ "GenSigTimeoutTime" BU_SG_REL_ EMS SG_ 2364539395 TransmissionShiftInProcess 60;
BA_REL_ "GenSigFirstTimeoutTime" BU_SG_REL_ VMCU SG_ 2364539395 TransmissionShiftInProcess 3000;
BA_REL_ "GenSigTimeoutTime" BU_SG_REL_ VMCU SG_ 2364539395 TransmissionShiftInProcess 60;
BA_REL_ "GenSigFirstTimeoutTime" BU_SG_REL_ EBS SG_ 2364539395 TransmissionShiftInProcess 3000;
BA_REL_ "GenSigTimeoutTime" BU_SG_REL_ EBS SG_ 2364539395 TransmissionShiftInProcess 60;
BA_REL_ "GenSigFirstTimeoutTime" BU_SG_REL_ BBM SG_ 2364539395 TransmissionShiftInProcess 3000;
BA_REL_ "GenSigTimeoutTime" BU_SG_REL_ BBM SG_ 2364539395 TransmissionShiftInProcess 60;
BA_REL_ "GenSigFirstTimeoutTime" BU_SG_REL_ DACU SG_ 2364539395 TransmissionShiftInProcess 3000;
BA_REL_ "GenSigTimeoutTime" BU_SG_REL_ DACU SG_ 2364539395 TransmissionShiftInProcess 600;
BA_REL_ "GenSigFirstTimeoutTime" BU_SG_REL_ VGGSECUSystem SG_ 2566843904 EngineOilTemperature 24000;
BA_REL_ "GenSigTimeoutTime" BU_SG_REL_ VGGSECUSystem SG_ 2566843904 EngineOilTemperature 6000;
BA_REL_ "GenSigFirstTimeoutTime" BU_SG_REL_ HMIIOM SG_ 2566843904 EngineOilTemperature 24000;
BA_REL_ "GenSigTimeoutTime" BU_SG_REL_ HMIIOM SG_ 2566843904 EngineOilTemperature 6000;
BA_REL_ "GenSigFirstTimeoutTime" BU_SG_REL_ BBM SG_ 2566843904 EngineOilTemperature 24000;
BA_REL_ "GenSigTimeoutTime" BU_SG_REL_ BBM SG_ 2566843904 EngineOilTemperature 6000;
BA_REL_ "GenSigFirstTimeoutTime" BU_SG_REL_ TECU SG_ 2566843904 EngineOilTemperature 24000;
BA_REL_ "GenSigTimeoutTime" BU_SG_REL_ TECU SG_ 2566843904 EngineOilTemperature 6000;
BA_REL_ "GenSigFirstTimeoutTime" BU_SG_REL_ CIOM SG_ 2566843904 EngineCoolantTemp_stat 24000;
BA_REL_ "GenSigTimeoutTime" BU_SG_REL_ CIOM SG_ 2566843904 EngineCoolantTemp_stat 6000;
BA_REL_ "GenSigFirstTimeoutTime" BU_SG_REL_ HMIIOM SG_ 2566843904 EngineCoolantTemp_stat 24000;
BA_REL_ "GenSigTimeoutTime" BU_SG_REL_ HMIIOM SG_ 2566843904 EngineCoolantTemp_stat 6000;
BA_REL_ "GenSigFirstTimeoutTime" BU_SG_REL_ VMCU SG_ 2566843904 EngineCoolantTemp_stat 24000;
BA_REL_ "GenSigTimeoutTime" BU_SG_REL_ VMCU SG_ 2566843904 EngineCoolantTemp_stat 6000;
BA_REL_ "GenSigFirstTimeoutTime" BU_SG_REL_ TECU SG_ 2566843904 EngineCoolantTemp_stat 24000;
BA_REL_ "GenSigTimeoutTime" BU_SG_REL_ TECU SG_ 2566843904 EngineCoolantTemp_stat 6000;
BA_REL_ "GenSigFirstTimeoutTime" BU_SG_REL_ VGGSECUSystem SG_ 2566843904 EngineCoolantTemp_stat 24000;
BA_REL_ "GenSigTimeoutTime" BU_SG_REL_ VGGSECUSystem SG_ 2566843904 EngineCoolantTemp_stat 6000;
BA_REL_ "GenSigFirstTimeoutTime" BU_SG_REL_ ACM SG_ 2566843904 EngineCoolantTemp_stat 24000;
BA_REL_ "GenSigTimeoutTime" BU_SG_REL_ ACM SG_ 2566843904 EngineCoolantTemp_stat 6000;
BA_REL_ "GenSigFirstTimeoutTime" BU_SG_REL_ BBM SG_ 2566843904 EngineCoolantTemp_stat 24000;
BA_REL_ "GenSigTimeoutTime" BU_SG_REL_ BBM SG_ 2566843904 EngineCoolantTemp_stat 6000;
BA_REL_ "GenSigFirstTimeoutTime" BU_SG_REL_ EMS SG_ 2558984359 RequestedFuelTypeVGGS 24000;
BA_REL_ "GenSigTimeoutTime" BU_SG_REL_ EMS SG_ 2558984359 RequestedFuelTypeVGGS 6000;
BA_REL_ "GenSigFirstTimeoutTime" BU_SG_REL_ EMS SG_ 2565865488 EngineCoolantLoadIncrease 3000;
BA_REL_ "GenSigTimeoutTime" BU_SG_REL_ EMS SG_ 2565865488 EngineCoolantLoadIncrease 600;
BA_REL_ "GenSigFirstTimeoutTime" BU_SG_REL_ EMS SG_ 2565865488 ActualMaxAvailDrvlnRetPrctTrq 3000;
BA_REL_ "GenSigTimeoutTime" BU_SG_REL_ EMS SG_ 2565865488 ActualMaxAvailDrvlnRetPrctTrq 600;
BA_REL_ "GenSigFirstTimeoutTime" BU_SG_REL_ EBS SG_ 2565865488 ActualMaxAvailDrvlnRetPrctTrq 3000;
BA_REL_ "GenSigTimeoutTime" BU_SG_REL_ EBS SG_ 2565865488 ActualMaxAvailDrvlnRetPrctTrq 600;
BA_REL_ "GenSigFirstTimeoutTime" BU_SG_REL_ VMCU SG_ 2565865488 ActualMaxAvailDrvlnRetPrctTrq 3000;
BA_REL_ "GenSigTimeoutTime" BU_SG_REL_ VMCU SG_ 2565865488 ActualMaxAvailDrvlnRetPrctTrq 600;
BA_REL_ "GenSigFirstTimeoutTime" BU_SG_REL_ TECU SG_ 2565865488 ActualMaxAvailDrvlnRetPrctTrq 3000;
BA_REL_ "GenSigTimeoutTime" BU_SG_REL_ TECU SG_ 2565865488 ActualMaxAvailDrvlnRetPrctTrq 600;
BA_REL_ "GenSigFirstTimeoutTime" BU_SG_REL_ EMS SG_ 2565865488 ActualDrvlnRetdrPercentTorque 3000;
BA_REL_ "GenSigTimeoutTime" BU_SG_REL_ EMS SG_ 2565865488 ActualDrvlnRetdrPercentTorque 600;
BA_REL_ "GenSigFirstTimeoutTime" BU_SG_REL_ CIOM SG_ 2565865488 ActualDrvlnRetdrPercentTorque 3000;
BA_REL_ "GenSigTimeoutTime" BU_SG_REL_ CIOM SG_ 2565865488 ActualDrvlnRetdrPercentTorque 600;
BA_REL_ "GenSigFirstTimeoutTime" BU_SG_REL_ VMCU SG_ 2565865488 ActualDrvlnRetdrPercentTorque 3000;
BA_REL_ "GenSigTimeoutTime" BU_SG_REL_ VMCU SG_ 2565865488 ActualDrvlnRetdrPercentTorque 600;
BA_REL_ "GenSigFirstTimeoutTime" BU_SG_REL_ TECU SG_ 2565865488 ActualDrvlnRetdrPercentTorque 3000;
BA_REL_ "GenSigTimeoutTime" BU_SG_REL_ TECU SG_ 2565865488 ActualDrvlnRetdrPercentTorque 600;
BA_REL_ "GenSigFirstTimeoutTime" BU_SG_REL_ EBS SG_ 2565865488 ActualDrvlnRetdrPercentTorque 3000;
BA_REL_ "GenSigTimeoutTime" BU_SG_REL_ EBS SG_ 2565865488 ActualDrvlnRetdrPercentTorque 600;
BA_REL_ "GenSigFirstTimeoutTime" BU_SG_REL_ HMIIOM SG_ 2565865488 ActualDrvlnRetdrPercentTorque 3000;
BA_REL_ "GenSigTimeoutTime" BU_SG_REL_ HMIIOM SG_ 2565865488 ActualDrvlnRetdrPercentTorque 600;
BA_REL_ "GenSigFirstTimeoutTime" BU_SG_REL_ CIOM SG_ 2565865488 RetarderTorqueMode 3000;
BA_REL_ "GenSigTimeoutTime" BU_SG_REL_ CIOM SG_ 2565865488 RetarderTorqueMode 600;
BA_REL_ "GenSigFirstTimeoutTime" BU_SG_REL_ HMIIOM SG_ 2565865488 RetarderTorqueMode 3000;
BA_REL_ "GenSigTimeoutTime" BU_SG_REL_ HMIIOM SG_ 2565865488 RetarderTorqueMode 600;
BA_REL_ "GenSigFirstTimeoutTime" BU_SG_REL_ EMS SG_ 2565865488 RetarderTorqueMode 3000;
BA_REL_ "GenSigTimeoutTime" BU_SG_REL_ EMS SG_ 2565865488 RetarderTorqueMode 600;
BA_REL_ "GenSigFirstTimeoutTime" BU_SG_REL_ VMCU SG_ 2565865487 ActlMaxAvailEngRetdrPercentTrq 3000;
BA_REL_ "GenSigTimeoutTime" BU_SG_REL_ VMCU SG_ 2565865487 ActlMaxAvailEngRetdrPercentTrq 600;
BA_REL_ "GenSigFirstTimeoutTime" BU_SG_REL_ EBS SG_ 2565865487 ActlMaxAvailEngRetdrPercentTrq 3000;
BA_REL_ "GenSigTimeoutTime" BU_SG_REL_ EBS SG_ 2565865487 ActlMaxAvailEngRetdrPercentTrq 600;
BA_REL_ "GenSigFirstTimeoutTime" BU_SG_REL_ TECU SG_ 2565865487 RetarderEnableShiftAssistSw 3000;
BA_REL_ "GenSigTimeoutTime" BU_SG_REL_ TECU SG_ 2565865487 RetarderEnableShiftAssistSw 600;
BA_REL_ "GenSigFirstTimeoutTime" BU_SG_REL_ CIOM SG_ 2565865487 EngineRetarderTorqueMode 3000;
BA_REL_ "GenSigTimeoutTime" BU_SG_REL_ CIOM SG_ 2565865487 EngineRetarderTorqueMode 600;
BA_REL_ "GenSigFirstTimeoutTime" BU_SG_REL_ HMIIOM SG_ 2565865487 EngineRetarderTorqueMode 3000;
BA_REL_ "GenSigTimeoutTime" BU_SG_REL_ HMIIOM SG_ 2565865487 EngineRetarderTorqueMode 600;
BA_REL_ "GenSigFirstTimeoutTime" BU_SG_REL_ TECU SG_ 2565865487 EngRetdrEnableBrakeAssistSw 3000;
BA_REL_ "GenSigTimeoutTime" BU_SG_REL_ TECU SG_ 2565865487 EngRetdrEnableBrakeAssistSw 600;
BA_REL_ "GenSigFirstTimeoutTime" BU_SG_REL_ RECU_Virt SG_ 2565865487 ActualEngineRetarderPercentTrq 3000;
BA_REL_ "GenSigTimeoutTime" BU_SG_REL_ RECU_Virt SG_ 2565865487 ActualEngineRetarderPercentTrq 600;
BA_REL_ "GenSigFirstTimeoutTime" BU_SG_REL_ CIOM SG_ 2565865487 ActualEngineRetarderPercentTrq 3000;
BA_REL_ "GenSigTimeoutTime" BU_SG_REL_ CIOM SG_ 2565865487 ActualEngineRetarderPercentTrq 600;
BA_REL_ "GenSigFirstTimeoutTime" BU_SG_REL_ EBS SG_ 2565865487 ActualEngineRetarderPercentTrq 3000;
BA_REL_ "GenSigTimeoutTime" BU_SG_REL_ EBS SG_ 2565865487 ActualEngineRetarderPercentTrq 600;
BA_REL_ "GenSigFirstTimeoutTime" BU_SG_REL_ HMIIOM SG_ 2565865487 ActualEngineRetarderPercentTrq 3000;
BA_REL_ "GenSigTimeoutTime" BU_SG_REL_ HMIIOM SG_ 2565865487 ActualEngineRetarderPercentTrq 600;
BA_REL_ "GenSigFirstTimeoutTime" BU_SG_REL_ VMCU SG_ 2565865487 ActualEngineRetarderPercentTrq 3000;
BA_REL_ "GenSigTimeoutTime" BU_SG_REL_ VMCU SG_ 2565865487 ActualEngineRetarderPercentTrq 600;
BA_REL_ "GenSigFirstTimeoutTime" BU_SG_REL_ TECU SG_ 2565865487 ActualEngineRetarderPercentTrq 3000;
BA_REL_ "GenSigTimeoutTime" BU_SG_REL_ TECU SG_ 2565865487 ActualEngineRetarderPercentTrq 600;
BA_REL_ "GenSigFirstTimeoutTime" BU_SG_REL_ VGGSECUSystem SG_ 2565865487 ActualEngineRetarderPercentTrq 3000;
BA_REL_ "GenSigTimeoutTime" BU_SG_REL_ VGGSECUSystem SG_ 2565865487 ActualEngineRetarderPercentTrq 600;
BA_REL_ "GenSigFirstTimeoutTime" BU_SG_REL_ VMCU SG_ 2364541440 EngineIntakeAirRate 12000;
BA_REL_ "GenSigTimeoutTime" BU_SG_REL_ VMCU SG_ 2364541440 EngineIntakeAirRate 3000;
BA_REL_ "GenSigFirstTimeoutTime" BU_SG_REL_ VGGSECUSystem SG_ 2566844160 EngineOilLevel 12000;
BA_REL_ "GenSigTimeoutTime" BU_SG_REL_ VGGSECUSystem SG_ 2566844160 EngineOilLevel 3000;
BA_REL_ "GenSigFirstTimeoutTime" BU_SG_REL_ BBM SG_ 2566844160 EngineOilLevel 12000;
BA_REL_ "GenSigTimeoutTime" BU_SG_REL_ BBM SG_ 2566844160 EngineOilLevel 3000;
BA_REL_ "GenSigFirstTimeoutTime" BU_SG_REL_ HMIIOM SG_ 2566844160 EngineOilLevel 12000;
BA_REL_ "GenSigTimeoutTime" BU_SG_REL_ HMIIOM SG_ 2566844160 EngineOilLevel 3000;
BA_REL_ "GenSigFirstTimeoutTime" BU_SG_REL_ VMCU SG_ 2566844160 EngineOilPressure 12000;
BA_REL_ "GenSigTimeoutTime" BU_SG_REL_ VMCU SG_ 2566844160 EngineOilPressure 3000;
BA_REL_ "GenSigFirstTimeoutTime" BU_SG_REL_ HMIIOM SG_ 2566844160 EngineOilPressure 12000;
BA_REL_ "GenSigTimeoutTime" BU_SG_REL_ HMIIOM SG_ 2566844160 EngineOilPressure 3000;
BA_REL_ "GenSigFirstTimeoutTime" BU_SG_REL_ VGGSECUSystem SG_ 2566844160 EngineOilPressure 12000;
BA_REL_ "GenSigTimeoutTime" BU_SG_REL_ VGGSECUSystem SG_ 2566844160 EngineOilPressure 3000;
BA_REL_ "GenSigFirstTimeoutTime" BU_SG_REL_ BBM SG_ 2566844160 EngineOilPressure 12000;
BA_REL_ "GenSigTimeoutTime" BU_SG_REL_ BBM SG_ 2566844160 EngineOilPressure 3000;
BA_REL_ "GenSigFirstTimeoutTime" BU_SG_REL_ VMCU SG_ 2566840064 NominalFrictionPercentTorque 6000;
BA_REL_ "GenSigTimeoutTime" BU_SG_REL_ VMCU SG_ 2566840064 NominalFrictionPercentTorque 1500;
BA_REL_ "GenSigFirstTimeoutTime" BU_SG_REL_ VGGSECUSystem SG_ 2566840064 NominalFrictionPercentTorque 6000;
BA_REL_ "GenSigTimeoutTime" BU_SG_REL_ VGGSECUSystem SG_ 2566840064 NominalFrictionPercentTorque 1500;
BA_REL_ "GenSigFirstTimeoutTime" BU_SG_REL_ TECU SG_ 2566840064 NominalFrictionPercentTorque 6000;
BA_REL_ "GenSigTimeoutTime" BU_SG_REL_ TECU SG_ 2566840064 NominalFrictionPercentTorque 1500;
BA_REL_ "GenSigFirstTimeoutTime" BU_SG_REL_ DACU SG_ 2566840064 NominalFrictionPercentTorque 6000;
BA_REL_ "GenSigTimeoutTime" BU_SG_REL_ DACU SG_ 2566840064 NominalFrictionPercentTorque 1500;
BA_REL_ "GenSigFirstTimeoutTime" BU_SG_REL_ EBS SG_ 2566840064 NominalFrictionPercentTorque 6000;
BA_REL_ "GenSigTimeoutTime" BU_SG_REL_ EBS SG_ 2566840064 NominalFrictionPercentTorque 1500;
BA_REL_ "GenSigFirstTimeoutTime" BU_SG_REL_ RECU_Virt SG_ 2566840064 NominalFrictionPercentTorque 6000;
BA_REL_ "GenSigTimeoutTime" BU_SG_REL_ RECU_Virt SG_ 2566840064 NominalFrictionPercentTorque 1500;
BA_REL_ "GenSigFirstTimeoutTime" BU_SG_REL_ VGGSECUSystem SG_ 2364539648 AcctrPedalKickDownSw_stat_2 3000;
BA_REL_ "GenSigTimeoutTime" BU_SG_REL_ VGGSECUSystem SG_ 2364539648 AcctrPedalKickDownSw_stat_2 300;
BA_REL_ "GenSigFirstTimeoutTime" BU_SG_REL_ ACM SG_ 2364539648 EnginePercentLoadAtCurrentSpd 3000;
BA_REL_ "GenSigTimeoutTime" BU_SG_REL_ ACM SG_ 2364539648 EnginePercentLoadAtCurrentSpd 300;
BA_REL_ "GenSigFirstTimeoutTime" BU_SG_REL_ HMIIOM SG_ 2364539648 EnginePercentLoadAtCurrentSpd 3000;
BA_REL_ "GenSigTimeoutTime" BU_SG_REL_ HMIIOM SG_ 2364539648 EnginePercentLoadAtCurrentSpd 300;
BA_REL_ "GenSigFirstTimeoutTime" BU_SG_REL_ BBM SG_ 2364539648 EnginePercentLoadAtCurrentSpd 3000;
BA_REL_ "GenSigTimeoutTime" BU_SG_REL_ BBM SG_ 2364539648 EnginePercentLoadAtCurrentSpd 300;
BA_REL_ "GenSigFirstTimeoutTime" BU_SG_REL_ CIOM SG_ 2364539648 EnginePercentLoadAtCurrentSpd 3000;
BA_REL_ "GenSigTimeoutTime" BU_SG_REL_ CIOM SG_ 2364539648 EnginePercentLoadAtCurrentSpd 300;
BA_REL_ "GenSigFirstTimeoutTime" BU_SG_REL_ VMCU SG_ 2364539648 EnginePercentLoadAtCurrentSpd 3000;
BA_REL_ "GenSigTimeoutTime" BU_SG_REL_ VMCU SG_ 2364539648 EnginePercentLoadAtCurrentSpd 300;
BA_REL_ "GenSigFirstTimeoutTime" BU_SG_REL_ TECU SG_ 2364539648 EnginePercentLoadAtCurrentSpd 3000;
BA_REL_ "GenSigTimeoutTime" BU_SG_REL_ TECU SG_ 2364539648 EnginePercentLoadAtCurrentSpd 300;
BA_REL_ "GenSigFirstTimeoutTime" BU_SG_REL_ VGGSECUSystem SG_ 2364539648 AcceleratorPedalPosition1_2 3000;
BA_REL_ "GenSigTimeoutTime" BU_SG_REL_ VGGSECUSystem SG_ 2364539648 AcceleratorPedalPosition1_2 300;
BA_REL_ "GenSigFirstTimeoutTime" BU_SG_REL_ TECU SG_ 2364539648 AcceleratorPedalPosition1_2 3000;
BA_REL_ "GenSigTimeoutTime" BU_SG_REL_ TECU SG_ 2364539648 AcceleratorPedalPosition1_2 600;
BA_REL_ "GenSigFirstTimeoutTime" BU_SG_REL_ TECU SG_ 2364539648 RoadSpeedLimitStatus 3000;
BA_REL_ "GenSigTimeoutTime" BU_SG_REL_ TECU SG_ 2364539648 RoadSpeedLimitStatus 300;
BA_REL_ "GenSigFirstTimeoutTime" BU_SG_REL_ TECU SG_ 2364539904 EngineDemandPercentTorque 3000;
BA_REL_ "GenSigTimeoutTime" BU_SG_REL_ TECU SG_ 2364539904 EngineDemandPercentTorque 120;
BA_REL_ "GenSigFirstTimeoutTime" BU_SG_REL_ VMCU SG_ 2364539904 EngineDemandPercentTorque 3000;
BA_REL_ "GenSigTimeoutTime" BU_SG_REL_ VMCU SG_ 2364539904 EngineDemandPercentTorque 120;
BA_REL_ "GenSigFirstTimeoutTime" BU_SG_REL_ BBM SG_ 2364539904 DrvrDemandEngPercentTorque 3000;
BA_REL_ "GenSigTimeoutTime" BU_SG_REL_ BBM SG_ 2364539904 DrvrDemandEngPercentTorque 120;
BA_REL_ "GenSigFirstTimeoutTime" BU_SG_REL_ TECU SG_ 2364539904 DrvrDemandEngPercentTorque 3000;
BA_REL_ "GenSigTimeoutTime" BU_SG_REL_ TECU SG_ 2364539904 DrvrDemandEngPercentTorque 120;
BA_REL_ "GenSigFirstTimeoutTime" BU_SG_REL_ EBS SG_ 2364539904 DrvrDemandEngPercentTorque 3000;
BA_REL_ "GenSigTimeoutTime" BU_SG_REL_ EBS SG_ 2364539904 DrvrDemandEngPercentTorque 120;
BA_REL_ "GenSigFirstTimeoutTime" BU_SG_REL_ VMCU SG_ 2364539904 DrvrDemandEngPercentTorque 3000;
BA_REL_ "GenSigTimeoutTime" BU_SG_REL_ VMCU SG_ 2364539904 DrvrDemandEngPercentTorque 120;
BA_REL_ "GenSigFirstTimeoutTime" BU_SG_REL_ TECU SG_ 2364539904 EngineTorqueMode 3000;
BA_REL_ "GenSigTimeoutTime" BU_SG_REL_ TECU SG_ 2364539904 EngineTorqueMode 120;
BA_REL_ "GenSigFirstTimeoutTime" BU_SG_REL_ VMCU SG_ 2364539904 EngineTorqueMode 3000;
BA_REL_ "GenSigTimeoutTime" BU_SG_REL_ VMCU SG_ 2364539904 EngineTorqueMode 120;
BA_REL_ "GenSigFirstTimeoutTime" BU_SG_REL_ BBM SG_ 2364539904 EngineTorqueMode 3000;
BA_REL_ "GenSigTimeoutTime" BU_SG_REL_ BBM SG_ 2364539904 EngineTorqueMode 120;
BA_REL_ "GenSigFirstTimeoutTime" BU_SG_REL_ EBS SG_ 2364539904 EngineTorqueMode 3000;
BA_REL_ "GenSigTimeoutTime" BU_SG_REL_ EBS SG_ 2364539904 EngineTorqueMode 120;
BA_REL_ "GenSigFirstTimeoutTime" BU_SG_REL_ HMIIOM SG_ 2364539904 EngineTorqueMode 3000;
BA_REL_ "GenSigTimeoutTime" BU_SG_REL_ HMIIOM SG_ 2364539904 EngineTorqueMode 120;
BA_REL_ "GenSigFirstTimeoutTime" BU_SG_REL_ BBM SG_ 2364539904 EngineSpeed 3000;
BA_REL_ "GenSigTimeoutTime" BU_SG_REL_ BBM SG_ 2364539904 EngineSpeed 120;
BA_REL_ "GenSigFirstTimeoutTime" BU_SG_REL_ DACU SG_ 2364539904 EngineSpeed 3000;
BA_REL_ "GenSigTimeoutTime" BU_SG_REL_ DACU SG_ 2364539904 EngineSpeed 120;
BA_REL_ "GenSigFirstTimeoutTime" BU_SG_REL_ HMIIOM SG_ 2364539904 EngineSpeed 3000;
BA_REL_ "GenSigTimeoutTime" BU_SG_REL_ HMIIOM SG_ 2364539904 EngineSpeed 120;
BA_REL_ "GenSigFirstTimeoutTime" BU_SG_REL_ VMCU SG_ 2364539904 EngineSpeed 3000;
BA_REL_ "GenSigTimeoutTime" BU_SG_REL_ VMCU SG_ 2364539904 EngineSpeed 120;
BA_REL_ "GenSigFirstTimeoutTime" BU_SG_REL_ VGGSECUSystem SG_ 2364539904 EngineSpeed 3000;
BA_REL_ "GenSigTimeoutTime" BU_SG_REL_ VGGSECUSystem SG_ 2364539904 EngineSpeed 120;
BA_REL_ "GenSigFirstTimeoutTime" BU_SG_REL_ EBS SG_ 2364539904 EngineSpeed 3000;
BA_REL_ "GenSigTimeoutTime" BU_SG_REL_ EBS SG_ 2364539904 EngineSpeed 120;
BA_REL_ "GenSigFirstTimeoutTime" BU_SG_REL_ ACM SG_ 2364539904 EngineSpeed 3000;
BA_REL_ "GenSigTimeoutTime" BU_SG_REL_ ACM SG_ 2364539904 EngineSpeed 120;
BA_REL_ "GenSigFirstTimeoutTime" BU_SG_REL_ TECU SG_ 2364539904 EngineSpeed 3000;
BA_REL_ "GenSigTimeoutTime" BU_SG_REL_ TECU SG_ 2364539904 EngineSpeed 120;
BA_REL_ "GenSigFirstTimeoutTime" BU_SG_REL_ CIOM SG_ 2364539904 EngineSpeed 3000;
BA_REL_ "GenSigTimeoutTime" BU_SG_REL_ CIOM SG_ 2364539904 EngineSpeed 120;
BA_REL_ "GenSigFirstTimeoutTime" BU_SG_REL_ HMIIOM SG_ 2364539904 ActualEnginePercentTorque 3000;
BA_REL_ "GenSigTimeoutTime" BU_SG_REL_ HMIIOM SG_ 2364539904 ActualEnginePercentTorque 120;
BA_REL_ "GenSigFirstTimeoutTime" BU_SG_REL_ VMCU SG_ 2364539904 ActualEnginePercentTorque 3000;
BA_REL_ "GenSigTimeoutTime" BU_SG_REL_ VMCU SG_ 2364539904 ActualEnginePercentTorque 120;
BA_REL_ "GenSigFirstTimeoutTime" BU_SG_REL_ EBS SG_ 2364539904 ActualEnginePercentTorque 3000;
BA_REL_ "GenSigTimeoutTime" BU_SG_REL_ EBS SG_ 2364539904 ActualEnginePercentTorque 120;
BA_REL_ "GenSigFirstTimeoutTime" BU_SG_REL_ CIOM SG_ 2364539904 ActualEnginePercentTorque 3000;
BA_REL_ "GenSigTimeoutTime" BU_SG_REL_ CIOM SG_ 2364539904 ActualEnginePercentTorque 120;
BA_REL_ "GenSigFirstTimeoutTime" BU_SG_REL_ TECU SG_ 2364539904 ActualEnginePercentTorque 3000;
BA_REL_ "GenSigTimeoutTime" BU_SG_REL_ TECU SG_ 2364539904 ActualEnginePercentTorque 120;
BA_REL_ "GenSigFirstTimeoutTime" BU_SG_REL_ BBM SG_ 2364539904 ActualEnginePercentTorque 3000;
BA_REL_ "GenSigTimeoutTime" BU_SG_REL_ BBM SG_ 2364539904 ActualEnginePercentTorque 120;
BA_REL_ "GenSigFirstTimeoutTime" BU_SG_REL_ DACU SG_ 2364539904 ActualEnginePercentTorque 3000;
BA_REL_ "GenSigTimeoutTime" BU_SG_REL_ DACU SG_ 2364539904 ActualEnginePercentTorque 120;
BA_REL_ "GenSigFirstTimeoutTime" BU_SG_REL_ VMCU SG_ 2364539904 EngineStarterMode 3000;
BA_REL_ "GenSigTimeoutTime" BU_SG_REL_ VMCU SG_ 2364539904 EngineStarterMode 120;
BA_REL_ "GenSigFirstTimeoutTime" BU_SG_REL_ BBM SG_ 2364539904 EngineStarterMode 3000;
BA_REL_ "GenSigTimeoutTime" BU_SG_REL_ BBM SG_ 2364539904 EngineStarterMode 120;
BA_REL_ "GenSigFirstTimeoutTime" BU_SG_REL_ HMIIOM SG_ 2364539904 EngineStarterMode 3000;
BA_REL_ "GenSigTimeoutTime" BU_SG_REL_ HMIIOM SG_ 2364539904 EngineStarterMode 120;
BA_REL_ "GenSigFirstTimeoutTime" BU_SG_REL_ TECU SG_ 2566841088 EngConf_EngSpeedAtHighIdle_P6 65000;
BA_REL_ "GenSigTimeoutTime" BU_SG_REL_ TECU SG_ 2566841088 EngConf_EngSpeedAtHighIdle_P6 30000;
BA_REL_ "GenSigFirstTimeoutTime" BU_SG_REL_ TECU SG_ 2566841088 EngConf_EngTorqueAt_P4 65000;
BA_REL_ "GenSigTimeoutTime" BU_SG_REL_ TECU SG_ 2566841088 EngConf_EngTorqueAt_P4 30000;
BA_REL_ "GenSigFirstTimeoutTime" BU_SG_REL_ TECU SG_ 2566841088 EngConf_EngMaxMomOvSpeed_P7 65000;
BA_REL_ "GenSigTimeoutTime" BU_SG_REL_ TECU SG_ 2566841088 EngConf_EngMaxMomOvSpeed_P7 30000;
BA_REL_ "GenSigFirstTimeoutTime" BU_SG_REL_ TECU SG_ 2566841088 EngConf_EngTorqueAt_P5 65000;
BA_REL_ "GenSigTimeoutTime" BU_SG_REL_ TECU SG_ 2566841088 EngConf_EngTorqueAt_P5 30000;
BA_REL_ "GenSigFirstTimeoutTime" BU_SG_REL_ TECU SG_ 2566841088 EngConf_EngSpeedAtIdle_P1 65000;
BA_REL_ "GenSigTimeoutTime" BU_SG_REL_ TECU SG_ 2566841088 EngConf_EngSpeedAtIdle_P1 30000;
BA_REL_ "GenSigFirstTimeoutTime" BU_SG_REL_ TECU SG_ 2566841088 EngineReferenceTorque 65000;
BA_REL_ "GenSigTimeoutTime" BU_SG_REL_ TECU SG_ 2566841088 EngineReferenceTorque 30000;
BA_REL_ "GenSigFirstTimeoutTime" BU_SG_REL_ RECU_Virt SG_ 2566841088 EngineReferenceTorque 65000;
BA_REL_ "GenSigTimeoutTime" BU_SG_REL_ RECU_Virt SG_ 2566841088 EngineReferenceTorque 30000;
BA_REL_ "GenSigFirstTimeoutTime" BU_SG_REL_ VGGSECUSystem SG_ 2566841088 EngineReferenceTorque 65000;
BA_REL_ "GenSigTimeoutTime" BU_SG_REL_ VGGSECUSystem SG_ 2566841088 EngineReferenceTorque 30000;
BA_REL_ "GenSigFirstTimeoutTime" BU_SG_REL_ DACU SG_ 2566841088 EngineReferenceTorque 60000;
BA_REL_ "GenSigTimeoutTime" BU_SG_REL_ DACU SG_ 2566841088 EngineReferenceTorque 30000;
BA_REL_ "GenSigFirstTimeoutTime" BU_SG_REL_ EBS SG_ 2566841088 EngineReferenceTorque 65000;
BA_REL_ "GenSigTimeoutTime" BU_SG_REL_ EBS SG_ 2566841088 EngineReferenceTorque 30000;
BA_REL_ "GenSigFirstTimeoutTime" BU_SG_REL_ VMCU SG_ 2566841088 EngineReferenceTorque 65000;
BA_REL_ "GenSigTimeoutTime" BU_SG_REL_ VMCU SG_ 2566841088 EngineReferenceTorque 30000;
BA_REL_ "GenSigFirstTimeoutTime" BU_SG_REL_ TECU SG_ 2566841088 EngConf_EngSpeedAt_P2 65000;
BA_REL_ "GenSigTimeoutTime" BU_SG_REL_ TECU SG_ 2566841088 EngConf_EngSpeedAt_P2 30000;
BA_REL_ "GenSigFirstTimeoutTime" BU_SG_REL_ TECU SG_ 2566841088 EngConf_MaxMomOverrideTimeLim 65000;
BA_REL_ "GenSigTimeoutTime" BU_SG_REL_ TECU SG_ 2566841088 EngConf_MaxMomOverrideTimeLim 30000;
BA_REL_ "GenSigFirstTimeoutTime" BU_SG_REL_ TECU SG_ 2566841088 EngConf_EngSpeedAt_P5 65000;
BA_REL_ "GenSigTimeoutTime" BU_SG_REL_ TECU SG_ 2566841088 EngConf_EngSpeedAt_P5 30000;
BA_REL_ "GenSigFirstTimeoutTime" BU_SG_REL_ TECU SG_ 2566841088 EngConf_EngTorqueAtIdle_P1 65000;
BA_REL_ "GenSigTimeoutTime" BU_SG_REL_ TECU SG_ 2566841088 EngConf_EngTorqueAtIdle_P1 30000;
BA_REL_ "GenSigFirstTimeoutTime" BU_SG_REL_ TECU SG_ 2566841088 EngConf_EngSpeedAt_P4 65000;
BA_REL_ "GenSigTimeoutTime" BU_SG_REL_ TECU SG_ 2566841088 EngConf_EngSpeedAt_P4 30000;
BA_REL_ "GenSigFirstTimeoutTime" BU_SG_REL_ TECU SG_ 2566841088 EngConf_EngSpeedAt_P3 65000;
BA_REL_ "GenSigTimeoutTime" BU_SG_REL_ TECU SG_ 2566841088 EngConf_EngSpeedAt_P3 30000;
BA_REL_ "GenSigFirstTimeoutTime" BU_SG_REL_ TECU SG_ 2566841088 EngConf_EngTorqueAt_P3 65000;
BA_REL_ "GenSigTimeoutTime" BU_SG_REL_ TECU SG_ 2566841088 EngConf_EngTorqueAt_P3 30000;
BA_REL_ "GenSigFirstTimeoutTime" BU_SG_REL_ TECU SG_ 2566841088 EngConf_EngTorqueAt_P2 65000;
BA_REL_ "GenSigTimeoutTime" BU_SG_REL_ TECU SG_ 2566841088 EngConf_EngTorqueAt_P2 30000;
BA_REL_ "GenSigFirstTimeoutTime" BU_SG_REL_ HMIIOM SG_ 2566894859 Trailer5VIN 60000;
BA_REL_ "GenSigTimeoutTime" BU_SG_REL_ HMIIOM SG_ 2566894859 Trailer5VIN 60000;
BA_REL_ "GenSigFirstTimeoutTime" BU_SG_REL_ HMIIOM SG_ 2566894603 Trailer4VIN 60000;
BA_REL_ "GenSigTimeoutTime" BU_SG_REL_ HMIIOM SG_ 2566894603 Trailer4VIN 60000;
BA_REL_ "GenSigFirstTimeoutTime" BU_SG_REL_ HMIIOM SG_ 2566894347 Trailer3VIN 60000;
BA_REL_ "GenSigTimeoutTime" BU_SG_REL_ HMIIOM SG_ 2566894347 Trailer3VIN 60000;
BA_REL_ "GenSigFirstTimeoutTime" BU_SG_REL_ HMIIOM SG_ 2566894091 Trailer2VIN 60000;
BA_REL_ "GenSigTimeoutTime" BU_SG_REL_ HMIIOM SG_ 2566894091 Trailer2VIN 60000;
BA_REL_ "GenSigFirstTimeoutTime" BU_SG_REL_ HMIIOM SG_ 2566893835 Trailer1VIN 60000;
BA_REL_ "GenSigTimeoutTime" BU_SG_REL_ HMIIOM SG_ 2566893835 Trailer1VIN 60000;
BA_REL_ "GenSigFirstTimeoutTime" BU_SG_REL_ HMIIOM SG_ 2566903051 Trailer5GeometricData_Index 24000;
BA_REL_ "GenSigTimeoutTime" BU_SG_REL_ HMIIOM SG_ 2566903051 Trailer5GeometricData_Index 6000;
BA_REL_ "GenSigFirstTimeoutTime" BU_SG_REL_ VMCU SG_ 2566903051 PadChangePredictionAxleNumber 24000;
BA_REL_ "GenSigTimeoutTime" BU_SG_REL_ VMCU SG_ 2566903051 PadChangePredictionAxleNumber 6000;
BA_REL_ "GenSigFirstTimeoutTime" BU_SG_REL_ EMS SG_ 2566903051 XBRBrakingCapacityTime 24000;
BA_REL_ "GenSigTimeoutTime" BU_SG_REL_ EMS SG_ 2566903051 XBRBrakingCapacityTime 6000;
BA_REL_ "GenSigFirstTimeoutTime" BU_SG_REL_ TECU SG_ 2566903051 XBRBrakingCapacityTime 24000;
BA_REL_ "GenSigTimeoutTime" BU_SG_REL_ TECU SG_ 2566903051 XBRBrakingCapacityTime 6000;
BA_REL_ "GenSigFirstTimeoutTime" BU_SG_REL_ DACU SG_ 2566903051 XBRBrakingCapacityTime 24000;
BA_REL_ "GenSigTimeoutTime" BU_SG_REL_ DACU SG_ 2566903051 XBRBrakingCapacityTime 6000;
BA_REL_ "GenSigFirstTimeoutTime" BU_SG_REL_ HMIIOM SG_ 2566903051 Trailer5AxleLoadSum 24000;
BA_REL_ "GenSigTimeoutTime" BU_SG_REL_ HMIIOM SG_ 2566903051 Trailer5AxleLoadSum 6000;
BA_REL_ "GenSigFirstTimeoutTime" BU_SG_REL_ TECU SG_ 2566903051 XBRBrakingCapacityTemperature 24000;
BA_REL_ "GenSigTimeoutTime" BU_SG_REL_ TECU SG_ 2566903051 XBRBrakingCapacityTemperature 6000;
BA_REL_ "GenSigFirstTimeoutTime" BU_SG_REL_ DACU SG_ 2566903051 XBRBrakingCapacityTemperature 24000;
BA_REL_ "GenSigTimeoutTime" BU_SG_REL_ DACU SG_ 2566903051 XBRBrakingCapacityTemperature 6000;
BA_REL_ "GenSigFirstTimeoutTime" BU_SG_REL_ EMS SG_ 2566903051 XBRBrakingCapacityTemperature 24000;
BA_REL_ "GenSigTimeoutTime" BU_SG_REL_ EMS SG_ 2566903051 XBRBrakingCapacityTemperature 6000;
BA_REL_ "GenSigFirstTimeoutTime" BU_SG_REL_ HMIIOM SG_ 2566903051 Trailer5GeometricData_Content 24000;
BA_REL_ "GenSigTimeoutTime" BU_SG_REL_ HMIIOM SG_ 2566903051 Trailer5GeometricData_Content 6000;
BA_REL_ "GenSigFirstTimeoutTime" BU_SG_REL_ VGGSECUSystem SG_ 2566903051 LiningWearWarning 24000;
BA_REL_ "GenSigTimeoutTime" BU_SG_REL_ VGGSECUSystem SG_ 2566903051 LiningWearWarning 6000;
BA_REL_ "GenSigFirstTimeoutTime" BU_SG_REL_ HMIIOM SG_ 2566903051 LiningWearWarning 24000;
BA_REL_ "GenSigTimeoutTime" BU_SG_REL_ HMIIOM SG_ 2566903051 LiningWearWarning 6000;
BA_REL_ "GenSigFirstTimeoutTime" BU_SG_REL_ HMIIOM SG_ 2566902539 Trailer3GeometricData_Index 24000;
BA_REL_ "GenSigTimeoutTime" BU_SG_REL_ HMIIOM SG_ 2566902539 Trailer3GeometricData_Index 6000;
BA_REL_ "GenSigFirstTimeoutTime" BU_SG_REL_ HMIIOM SG_ 2566902539 Trailer4GeometricData_Content 24000;
BA_REL_ "GenSigTimeoutTime" BU_SG_REL_ HMIIOM SG_ 2566902539 Trailer4GeometricData_Content 6000;
BA_REL_ "GenSigFirstTimeoutTime" BU_SG_REL_ HMIIOM SG_ 2566902539 Trailer3GeometricData_Content 24000;
BA_REL_ "GenSigTimeoutTime" BU_SG_REL_ HMIIOM SG_ 2566902539 Trailer3GeometricData_Content 6000;
BA_REL_ "GenSigFirstTimeoutTime" BU_SG_REL_ HMIIOM SG_ 2566902539 Trailer3AxleLoadSum 24000;
BA_REL_ "GenSigTimeoutTime" BU_SG_REL_ HMIIOM SG_ 2566902539 Trailer3AxleLoadSum 6000;
BA_REL_ "GenSigFirstTimeoutTime" BU_SG_REL_ TECU SG_ 2566902539 Trailer3AxleLoadSum 24000;
BA_REL_ "GenSigTimeoutTime" BU_SG_REL_ TECU SG_ 2566902539 Trailer3AxleLoadSum 6000;
BA_REL_ "GenSigFirstTimeoutTime" BU_SG_REL_ HMIIOM SG_ 2566902539 Trailer4GeometricData_Index 24000;
BA_REL_ "GenSigTimeoutTime" BU_SG_REL_ HMIIOM SG_ 2566902539 Trailer4GeometricData_Index 6000;
BA_REL_ "GenSigFirstTimeoutTime" BU_SG_REL_ TECU SG_ 2566902539 Trailer4AxleLoadSum 24000;
BA_REL_ "GenSigTimeoutTime" BU_SG_REL_ TECU SG_ 2566902539 Trailer4AxleLoadSum 6000;
BA_REL_ "GenSigFirstTimeoutTime" BU_SG_REL_ HMIIOM SG_ 2566902539 Trailer4AxleLoadSum 24000;
BA_REL_ "GenSigTimeoutTime" BU_SG_REL_ HMIIOM SG_ 2566902539 Trailer4AxleLoadSum 6000;
BA_REL_ "GenSigFirstTimeoutTime" BU_SG_REL_ HMIIOM SG_ 2566902027 Trailer2GeometricData_Index 24000;
BA_REL_ "GenSigTimeoutTime" BU_SG_REL_ HMIIOM SG_ 2566902027 Trailer2GeometricData_Index 6000;
BA_REL_ "GenSigFirstTimeoutTime" BU_SG_REL_ HMIIOM SG_ 2566902027 Trailer1GeometricData_Content 24000;
BA_REL_ "GenSigTimeoutTime" BU_SG_REL_ HMIIOM SG_ 2566902027 Trailer1GeometricData_Content 6000;
BA_REL_ "GenSigFirstTimeoutTime" BU_SG_REL_ HMIIOM SG_ 2566902027 Trailer1GeometricData_Index 24000;
BA_REL_ "GenSigTimeoutTime" BU_SG_REL_ HMIIOM SG_ 2566902027 Trailer1GeometricData_Index 6000;
BA_REL_ "GenSigFirstTimeoutTime" BU_SG_REL_ TECU SG_ 2566902027 Trailer2AxleLoadSum 24000;
BA_REL_ "GenSigTimeoutTime" BU_SG_REL_ TECU SG_ 2566902027 Trailer2AxleLoadSum 6000;
BA_REL_ "GenSigFirstTimeoutTime" BU_SG_REL_ HMIIOM SG_ 2566902027 Trailer2AxleLoadSum 24000;
BA_REL_ "GenSigTimeoutTime" BU_SG_REL_ HMIIOM SG_ 2566902027 Trailer2AxleLoadSum 6000;
BA_REL_ "GenSigFirstTimeoutTime" BU_SG_REL_ HMIIOM SG_ 2566902027 Trailer1AxleLoadSum 24000;
BA_REL_ "GenSigTimeoutTime" BU_SG_REL_ HMIIOM SG_ 2566902027 Trailer1AxleLoadSum 6000;
BA_REL_ "GenSigFirstTimeoutTime" BU_SG_REL_ TECU SG_ 2566902027 Trailer1AxleLoadSum 24000;
BA_REL_ "GenSigTimeoutTime" BU_SG_REL_ TECU SG_ 2566902027 Trailer1AxleLoadSum 6000;
BA_REL_ "GenSigFirstTimeoutTime" BU_SG_REL_ HMIIOM SG_ 2566902027 Trailer2GeometricData_Content 24000;
BA_REL_ "GenSigTimeoutTime" BU_SG_REL_ HMIIOM SG_ 2566902027 Trailer2GeometricData_Content 6000;
BA_REL_ "GenSigFirstTimeoutTime" BU_SG_REL_ BBM SG_ 2566886667 Trailer5LiftAxle1Pos 3000;
BA_REL_ "GenSigTimeoutTime" BU_SG_REL_ BBM SG_ 2566886667 Trailer5LiftAxle1Pos 600;
BA_REL_ "GenSigFirstTimeoutTime" BU_SG_REL_ HMIIOM SG_ 2566886667 Trailer5LiftAxle1Pos 3000;
BA_REL_ "GenSigTimeoutTime" BU_SG_REL_ HMIIOM SG_ 2566886667 Trailer5LiftAxle1Pos 600;
BA_REL_ "GenSigFirstTimeoutTime" BU_SG_REL_ HMIIOM SG_ 2566886667 EHSClutchEngagmntOffsetOpStat 3000;
BA_REL_ "GenSigTimeoutTime" BU_SG_REL_ HMIIOM SG_ 2566886667 EHSClutchEngagmntOffsetOpStat 600;
BA_REL_ "GenSigFirstTimeoutTime" BU_SG_REL_ BBM SG_ 2566886667 Trailer5LiftAxle2Pos 3000;
BA_REL_ "GenSigTimeoutTime" BU_SG_REL_ BBM SG_ 2566886667 Trailer5LiftAxle2Pos 600;
BA_REL_ "GenSigFirstTimeoutTime" BU_SG_REL_ HMIIOM SG_ 2566886667 Trailer5LiftAxle2Pos 3000;
BA_REL_ "GenSigTimeoutTime" BU_SG_REL_ HMIIOM SG_ 2566886667 Trailer5LiftAxle2Pos 600;
BA_REL_ "GenSigFirstTimeoutTime" BU_SG_REL_ BBM SG_ 2566886667 Trailer5AxleLoad_AxleLoad 3000;
BA_REL_ "GenSigTimeoutTime" BU_SG_REL_ BBM SG_ 2566886667 Trailer5AxleLoad_AxleLoad 600;
BA_REL_ "GenSigFirstTimeoutTime" BU_SG_REL_ HMIIOM SG_ 2566886667 Trailer5AxleLoad_AxleLoad 3000;
BA_REL_ "GenSigTimeoutTime" BU_SG_REL_ HMIIOM SG_ 2566886667 Trailer5AxleLoad_AxleLoad 600;
BA_REL_ "GenSigFirstTimeoutTime" BU_SG_REL_ BBM SG_ 2566886667 Trailer5AxleLoad_AxleId 3000;
BA_REL_ "GenSigTimeoutTime" BU_SG_REL_ BBM SG_ 2566886667 Trailer5AxleLoad_AxleId 600;
BA_REL_ "GenSigFirstTimeoutTime" BU_SG_REL_ HMIIOM SG_ 2566886667 Trailer5AxleLoad_AxleId 3000;
BA_REL_ "GenSigTimeoutTime" BU_SG_REL_ HMIIOM SG_ 2566886667 Trailer5AxleLoad_AxleId 600;
BA_REL_ "GenSigFirstTimeoutTime" BU_SG_REL_ BBM SG_ 2566886155 Trailer3AxleLoad_AxleId 3000;
BA_REL_ "GenSigTimeoutTime" BU_SG_REL_ BBM SG_ 2566886155 Trailer3AxleLoad_AxleId 600;
BA_REL_ "GenSigFirstTimeoutTime" BU_SG_REL_ HMIIOM SG_ 2566886155 Trailer3AxleLoad_AxleId 3000;
BA_REL_ "GenSigTimeoutTime" BU_SG_REL_ HMIIOM SG_ 2566886155 Trailer3AxleLoad_AxleId 600;
BA_REL_ "GenSigFirstTimeoutTime" BU_SG_REL_ HMIIOM SG_ 2566886155 FrontParkBrakeOverrideStatus 3000;
BA_REL_ "GenSigTimeoutTime" BU_SG_REL_ HMIIOM SG_ 2566886155 FrontParkBrakeOverrideStatus 600;
BA_REL_ "GenSigFirstTimeoutTime" BU_SG_REL_ BBM SG_ 2566886155 Trailer3LiftAxle1Pos 3000;
BA_REL_ "GenSigTimeoutTime" BU_SG_REL_ BBM SG_ 2566886155 Trailer3LiftAxle1Pos 600;
BA_REL_ "GenSigFirstTimeoutTime" BU_SG_REL_ HMIIOM SG_ 2566886155 Trailer3LiftAxle1Pos 3000;
BA_REL_ "GenSigTimeoutTime" BU_SG_REL_ HMIIOM SG_ 2566886155 Trailer3LiftAxle1Pos 600;
BA_REL_ "GenSigFirstTimeoutTime" BU_SG_REL_ BBM SG_ 2566886155 Trailer4LiftAxle2Pos 3000;
BA_REL_ "GenSigTimeoutTime" BU_SG_REL_ BBM SG_ 2566886155 Trailer4LiftAxle2Pos 600;
BA_REL_ "GenSigFirstTimeoutTime" BU_SG_REL_ HMIIOM SG_ 2566886155 Trailer4LiftAxle2Pos 3000;
BA_REL_ "GenSigTimeoutTime" BU_SG_REL_ HMIIOM SG_ 2566886155 Trailer4LiftAxle2Pos 600;
BA_REL_ "GenSigFirstTimeoutTime" BU_SG_REL_ BBM SG_ 2566886155 Trailer4AxleLoad_AxleLoad 3000;
BA_REL_ "GenSigTimeoutTime" BU_SG_REL_ BBM SG_ 2566886155 Trailer4AxleLoad_AxleLoad 600;
BA_REL_ "GenSigFirstTimeoutTime" BU_SG_REL_ HMIIOM SG_ 2566886155 Trailer4AxleLoad_AxleLoad 3000;
BA_REL_ "GenSigTimeoutTime" BU_SG_REL_ HMIIOM SG_ 2566886155 Trailer4AxleLoad_AxleLoad 600;
BA_REL_ "GenSigFirstTimeoutTime" BU_SG_REL_ BBM SG_ 2566886155 Trailer3LiftAxle2Pos 3000;
BA_REL_ "GenSigTimeoutTime" BU_SG_REL_ BBM SG_ 2566886155 Trailer3LiftAxle2Pos 600;
BA_REL_ "GenSigFirstTimeoutTime" BU_SG_REL_ HMIIOM SG_ 2566886155 Trailer3LiftAxle2Pos 3000;
BA_REL_ "GenSigTimeoutTime" BU_SG_REL_ HMIIOM SG_ 2566886155 Trailer3LiftAxle2Pos 600;
BA_REL_ "GenSigFirstTimeoutTime" BU_SG_REL_ BBM SG_ 2566886155 Trailer3AxleLoad_AxleLoad 3000;
BA_REL_ "GenSigTimeoutTime" BU_SG_REL_ BBM SG_ 2566886155 Trailer3AxleLoad_AxleLoad 600;
BA_REL_ "GenSigFirstTimeoutTime" BU_SG_REL_ HMIIOM SG_ 2566886155 Trailer3AxleLoad_AxleLoad 3000;
BA_REL_ "GenSigTimeoutTime" BU_SG_REL_ HMIIOM SG_ 2566886155 Trailer3AxleLoad_AxleLoad 600;
BA_REL_ "GenSigFirstTimeoutTime" BU_SG_REL_ HMIIOM SG_ 2566886155 Trailer4LiftAxle1Pos 3000;
BA_REL_ "GenSigTimeoutTime" BU_SG_REL_ HMIIOM SG_ 2566886155 Trailer4LiftAxle1Pos 600;
BA_REL_ "GenSigFirstTimeoutTime" BU_SG_REL_ BBM SG_ 2566886155 Trailer4LiftAxle1Pos 3000;
BA_REL_ "GenSigTimeoutTime" BU_SG_REL_ BBM SG_ 2566886155 Trailer4LiftAxle1Pos 600;
BA_REL_ "GenSigFirstTimeoutTime" BU_SG_REL_ HMIIOM SG_ 2566886155 Trailer4AxleLoad_AxleId 3000;
BA_REL_ "GenSigTimeoutTime" BU_SG_REL_ HMIIOM SG_ 2566886155 Trailer4AxleLoad_AxleId 600;
BA_REL_ "GenSigFirstTimeoutTime" BU_SG_REL_ BBM SG_ 2566886155 Trailer4AxleLoad_AxleId 3000;
BA_REL_ "GenSigTimeoutTime" BU_SG_REL_ BBM SG_ 2566886155 Trailer4AxleLoad_AxleId 600;
BA_REL_ "GenSigFirstTimeoutTime" BU_SG_REL_ BBM SG_ 2566885643 Trailer2AxleLoad_AxleId 3000;
BA_REL_ "GenSigTimeoutTime" BU_SG_REL_ BBM SG_ 2566885643 Trailer2AxleLoad_AxleId 600;
BA_REL_ "GenSigFirstTimeoutTime" BU_SG_REL_ HMIIOM SG_ 2566885643 Trailer2AxleLoad_AxleId 3000;
BA_REL_ "GenSigTimeoutTime" BU_SG_REL_ HMIIOM SG_ 2566885643 Trailer2AxleLoad_AxleId 600;
BA_REL_ "GenSigFirstTimeoutTime" BU_SG_REL_ HMIIOM SG_ 2566885643 Trailer2LiftAxle2Pos 3000;
BA_REL_ "GenSigTimeoutTime" BU_SG_REL_ HMIIOM SG_ 2566885643 Trailer2LiftAxle2Pos 600;
BA_REL_ "GenSigFirstTimeoutTime" BU_SG_REL_ BBM SG_ 2566885643 Trailer2LiftAxle2Pos 3000;
BA_REL_ "GenSigTimeoutTime" BU_SG_REL_ BBM SG_ 2566885643 Trailer2LiftAxle2Pos 600;
BA_REL_ "GenSigFirstTimeoutTime" BU_SG_REL_ HMIIOM SG_ 2566885643 Trailer2AxleLoad_AxleLoad 3000;
BA_REL_ "GenSigTimeoutTime" BU_SG_REL_ HMIIOM SG_ 2566885643 Trailer2AxleLoad_AxleLoad 600;
BA_REL_ "GenSigFirstTimeoutTime" BU_SG_REL_ BBM SG_ 2566885643 Trailer2AxleLoad_AxleLoad 3000;
BA_REL_ "GenSigTimeoutTime" BU_SG_REL_ BBM SG_ 2566885643 Trailer2AxleLoad_AxleLoad 600;
BA_REL_ "GenSigFirstTimeoutTime" BU_SG_REL_ VGGSECUSystem SG_ 2566885643 TrailerEBSFault 3000;
BA_REL_ "GenSigTimeoutTime" BU_SG_REL_ VGGSECUSystem SG_ 2566885643 TrailerEBSFault 600;
BA_REL_ "GenSigFirstTimeoutTime" BU_SG_REL_ HMIIOM SG_ 2566885643 TrailerEBSFault 3000;
BA_REL_ "GenSigTimeoutTime" BU_SG_REL_ HMIIOM SG_ 2566885643 TrailerEBSFault 600;
BA_REL_ "GenSigFirstTimeoutTime" BU_SG_REL_ BBM SG_ 2566885643 Trailer1LiftAxle1Pos 3000;
BA_REL_ "GenSigTimeoutTime" BU_SG_REL_ BBM SG_ 2566885643 Trailer1LiftAxle1Pos 600;
BA_REL_ "GenSigFirstTimeoutTime" BU_SG_REL_ HMIIOM SG_ 2566885643 Trailer1LiftAxle1Pos 3000;
BA_REL_ "GenSigTimeoutTime" BU_SG_REL_ HMIIOM SG_ 2566885643 Trailer1LiftAxle1Pos 600;
BA_REL_ "GenSigFirstTimeoutTime" BU_SG_REL_ HMIIOM SG_ 2566885643 Trailer1AxleLoad_AxleId 3000;
BA_REL_ "GenSigTimeoutTime" BU_SG_REL_ HMIIOM SG_ 2566885643 Trailer1AxleLoad_AxleId 600;
BA_REL_ "GenSigFirstTimeoutTime" BU_SG_REL_ BBM SG_ 2566885643 Trailer1AxleLoad_AxleId 3000;
BA_REL_ "GenSigTimeoutTime" BU_SG_REL_ BBM SG_ 2566885643 Trailer1AxleLoad_AxleId 600;
BA_REL_ "GenSigFirstTimeoutTime" BU_SG_REL_ BBM SG_ 2566885643 Trailer1AxleLoad_AxleLoad 3000;
BA_REL_ "GenSigTimeoutTime" BU_SG_REL_ BBM SG_ 2566885643 Trailer1AxleLoad_AxleLoad 600;
BA_REL_ "GenSigFirstTimeoutTime" BU_SG_REL_ HMIIOM SG_ 2566885643 Trailer1AxleLoad_AxleLoad 3000;
BA_REL_ "GenSigTimeoutTime" BU_SG_REL_ HMIIOM SG_ 2566885643 Trailer1AxleLoad_AxleLoad 600;
BA_REL_ "GenSigFirstTimeoutTime" BU_SG_REL_ VGGSECUSystem SG_ 2566885643 TrailersConnected 3000;
BA_REL_ "GenSigTimeoutTime" BU_SG_REL_ VGGSECUSystem SG_ 2566885643 TrailersConnected 600;
BA_REL_ "GenSigFirstTimeoutTime" BU_SG_REL_ HMIIOM SG_ 2566885643 TrailersConnected 3000;
BA_REL_ "GenSigTimeoutTime" BU_SG_REL_ HMIIOM SG_ 2566885643 TrailersConnected 600;
BA_REL_ "GenSigFirstTimeoutTime" BU_SG_REL_ CIOM SG_ 2566885643 TrailersConnected 3000;
BA_REL_ "GenSigTimeoutTime" BU_SG_REL_ CIOM SG_ 2566885643 TrailersConnected 600;
BA_REL_ "GenSigFirstTimeoutTime" BU_SG_REL_ TECU SG_ 2566885643 TrailersConnected 3000;
BA_REL_ "GenSigTimeoutTime" BU_SG_REL_ TECU SG_ 2566885643 TrailersConnected 600;
BA_REL_ "GenSigFirstTimeoutTime" BU_SG_REL_ HMIIOM SG_ 2566885643 Trailer1LiftAxle2Pos 3000;
BA_REL_ "GenSigTimeoutTime" BU_SG_REL_ HMIIOM SG_ 2566885643 Trailer1LiftAxle2Pos 600;
BA_REL_ "GenSigFirstTimeoutTime" BU_SG_REL_ BBM SG_ 2566885643 Trailer1LiftAxle2Pos 3000;
BA_REL_ "GenSigTimeoutTime" BU_SG_REL_ BBM SG_ 2566885643 Trailer1LiftAxle2Pos 600;
BA_REL_ "GenSigFirstTimeoutTime" BU_SG_REL_ HMIIOM SG_ 2566885643 Trailer2LiftAxle1Pos 3000;
BA_REL_ "GenSigTimeoutTime" BU_SG_REL_ HMIIOM SG_ 2566885643 Trailer2LiftAxle1Pos 600;
BA_REL_ "GenSigFirstTimeoutTime" BU_SG_REL_ BBM SG_ 2566885643 Trailer2LiftAxle1Pos 3000;
BA_REL_ "GenSigTimeoutTime" BU_SG_REL_ BBM SG_ 2566885643 Trailer2LiftAxle1Pos 600;
BA_REL_ "GenSigFirstTimeoutTime" BU_SG_REL_ HMIIOM SG_ 2566906635 PredictedMileageOfNextPadChg 48000;
BA_REL_ "GenSigTimeoutTime" BU_SG_REL_ HMIIOM SG_ 2566906635 PredictedMileageOfNextPadChg 12000;
BA_REL_ "GenSigFirstTimeoutTime" BU_SG_REL_ VMCU SG_ 2566906635 PredictedMileageOfNextPadChg 48000;
BA_REL_ "GenSigTimeoutTime" BU_SG_REL_ VMCU SG_ 2566906635 PredictedMileageOfNextPadChg 12000;
BA_REL_ "GenSigFirstTimeoutTime" BU_SG_REL_ VMCU SG_ 2566906635 PadChgPredictionLastPadChg 48000;
BA_REL_ "GenSigTimeoutTime" BU_SG_REL_ VMCU SG_ 2566906635 PadChgPredictionLastPadChg 12000;
BA_REL_ "GenSigFirstTimeoutTime" BU_SG_REL_ HMIIOM SG_ 2499761675 BadBrakeBalanceWarning 3000;
BA_REL_ "GenSigTimeoutTime" BU_SG_REL_ HMIIOM SG_ 2499761675 BadBrakeBalanceWarning 300;
BA_REL_ "GenSigFirstTimeoutTime" BU_SG_REL_ BBM SG_ 2499761675 HSAAvailability 3000;
BA_REL_ "GenSigTimeoutTime" BU_SG_REL_ BBM SG_ 2499761675 HSAAvailability 300;
BA_REL_ "GenSigFirstTimeoutTime" BU_SG_REL_ TECU SG_ 2499761675 HSAAvailability 3000;
BA_REL_ "GenSigTimeoutTime" BU_SG_REL_ TECU SG_ 2499761675 HSAAvailability 240;
BA_REL_ "GenSigFirstTimeoutTime" BU_SG_REL_ HMIIOM SG_ 2499761675 DTCActive 3000;
BA_REL_ "GenSigTimeoutTime" BU_SG_REL_ HMIIOM SG_ 2499761675 DTCActive 300;
BA_REL_ "GenSigFirstTimeoutTime" BU_SG_REL_ HMIIOM SG_ 2499761675 StretchBrake_Stat 3000;
BA_REL_ "GenSigTimeoutTime" BU_SG_REL_ HMIIOM SG_ 2499761675 StretchBrake_Stat 300;
BA_REL_ "GenSigFirstTimeoutTime" BU_SG_REL_ VMCU SG_ 2499761675 StretchBrake_Stat 3000;
BA_REL_ "GenSigTimeoutTime" BU_SG_REL_ VMCU SG_ 2499761675 StretchBrake_Stat 240;
BA_REL_ "GenSigFirstTimeoutTime" BU_SG_REL_ BBM SG_ 2499761675 TrcnCtrlSlipperyRoadWarning 3000;
BA_REL_ "GenSigTimeoutTime" BU_SG_REL_ BBM SG_ 2499761675 TrcnCtrlSlipperyRoadWarning 240;
BA_REL_ "GenSigFirstTimeoutTime" BU_SG_REL_ HMIIOM SG_ 2499761675 TrcnCtrlSlipperyRoadWarning 3000;
BA_REL_ "GenSigTimeoutTime" BU_SG_REL_ HMIIOM SG_ 2499761675 TrcnCtrlSlipperyRoadWarning 300;
BA_REL_ "GenSigFirstTimeoutTime" BU_SG_REL_ VMCU SG_ 2499761675 RearAxleDiffLockActvnFuncReq 3000;
BA_REL_ "GenSigTimeoutTime" BU_SG_REL_ VMCU SG_ 2499761675 RearAxleDiffLockActvnFuncReq 500;
BA_REL_ "GenSigFirstTimeoutTime" BU_SG_REL_ VMCU SG_ 2499761675 BrakeTempWarningLevel 3000;
BA_REL_ "GenSigTimeoutTime" BU_SG_REL_ VMCU SG_ 2499761675 BrakeTempWarningLevel 240;
BA_REL_ "GenSigFirstTimeoutTime" BU_SG_REL_ DACU SG_ 2499761675 BrakeTempWarningLevel 3000;
BA_REL_ "GenSigTimeoutTime" BU_SG_REL_ DACU SG_ 2499761675 BrakeTempWarningLevel 300;
BA_REL_ "GenSigFirstTimeoutTime" BU_SG_REL_ TECU SG_ 2499761675 BrakeTempWarningLevel 3000;
BA_REL_ "GenSigTimeoutTime" BU_SG_REL_ TECU SG_ 2499761675 BrakeTempWarningLevel 240;
BA_REL_ "GenSigFirstTimeoutTime" BU_SG_REL_ EMS SG_ 2499761675 BrakeTempWarningLevel 3000;
BA_REL_ "GenSigTimeoutTime" BU_SG_REL_ EMS SG_ 2499761675 BrakeTempWarningLevel 240;
BA_REL_ "GenSigFirstTimeoutTime" BU_SG_REL_ DACU SG_ 2499761675 RollerBenchModeStatus 3000;
BA_REL_ "GenSigTimeoutTime" BU_SG_REL_ DACU SG_ 2499761675 RollerBenchModeStatus 300;
BA_REL_ "GenSigFirstTimeoutTime" BU_SG_REL_ HMIIOM SG_ 2499761675 RollerBenchModeStatus 3000;
BA_REL_ "GenSigTimeoutTime" BU_SG_REL_ HMIIOM SG_ 2499761675 RollerBenchModeStatus 300;
BA_REL_ "GenSigFirstTimeoutTime" BU_SG_REL_ VMCU SG_ 2499761675 RollerBenchModeStatus 3000;
BA_REL_ "GenSigTimeoutTime" BU_SG_REL_ VMCU SG_ 2499761675 RollerBenchModeStatus 240;
BA_REL_ "GenSigFirstTimeoutTime" BU_SG_REL_ VGGSECUSystem SG_ 2499761675 RollerBenchModeStatus 3000;
BA_REL_ "GenSigTimeoutTime" BU_SG_REL_ VGGSECUSystem SG_ 2499761675 RollerBenchModeStatus 240;
BA_REL_ "GenSigFirstTimeoutTime" BU_SG_REL_ VMCU SG_ 2499761675 BrakeAssistStatus 3000;
BA_REL_ "GenSigTimeoutTime" BU_SG_REL_ VMCU SG_ 2499761675 BrakeAssistStatus 300;
BA_REL_ "GenSigFirstTimeoutTime" BU_SG_REL_ BBM SG_ 2499761675 LongitudinalAcceleration 3000;
BA_REL_ "GenSigTimeoutTime" BU_SG_REL_ BBM SG_ 2499761675 LongitudinalAcceleration 240;
BA_REL_ "GenSigFirstTimeoutTime" BU_SG_REL_ HMIIOM SG_ 2499761675 TractionFunctionSelected 3000;
BA_REL_ "GenSigTimeoutTime" BU_SG_REL_ HMIIOM SG_ 2499761675 TractionFunctionSelected 300;
BA_REL_ "GenSigFirstTimeoutTime" BU_SG_REL_ HMIIOM SG_ 2499761675 PoorBrakePerformanceWarning 3000;
BA_REL_ "GenSigTimeoutTime" BU_SG_REL_ HMIIOM SG_ 2499761675 PoorBrakePerformanceWarning 300;
BA_REL_ "GenSigFirstTimeoutTime" BU_SG_REL_ VMCU SG_ 2499761675 VDCActive 3000;
BA_REL_ "GenSigTimeoutTime" BU_SG_REL_ VMCU SG_ 2499761675 VDCActive 240;
BA_REL_ "GenSigFirstTimeoutTime" BU_SG_REL_ HMIIOM SG_ 2499761675 VDCActive 3000;
BA_REL_ "GenSigTimeoutTime" BU_SG_REL_ HMIIOM SG_ 2499761675 VDCActive 300;
BA_REL_ "GenSigFirstTimeoutTime" BU_SG_REL_ VGGSECUSystem SG_ 2499761675 ABSInhibitionStatus 3000;
BA_REL_ "GenSigTimeoutTime" BU_SG_REL_ VGGSECUSystem SG_ 2499761675 ABSInhibitionStatus 240;
BA_REL_ "GenSigFirstTimeoutTime" BU_SG_REL_ TECU SG_ 2499761675 ABSInhibitionStatus 3000;
BA_REL_ "GenSigTimeoutTime" BU_SG_REL_ TECU SG_ 2499761675 ABSInhibitionStatus 240;
BA_REL_ "GenSigFirstTimeoutTime" BU_SG_REL_ CIOM SG_ 2499761675 ABSInhibitionStatus 3000;
BA_REL_ "GenSigTimeoutTime" BU_SG_REL_ CIOM SG_ 2499761675 ABSInhibitionStatus 300;
BA_REL_ "GenSigFirstTimeoutTime" BU_SG_REL_ VMCU SG_ 2499761675 ABSInhibitionStatus 3000;
BA_REL_ "GenSigTimeoutTime" BU_SG_REL_ VMCU SG_ 2499761675 ABSInhibitionStatus 300;
BA_REL_ "GenSigFirstTimeoutTime" BU_SG_REL_ HMIIOM SG_ 2499761675 ABSInhibitionStatus 3000;
BA_REL_ "GenSigTimeoutTime" BU_SG_REL_ HMIIOM SG_ 2499761675 ABSInhibitionStatus 300;
BA_REL_ "GenSigFirstTimeoutTime" BU_SG_REL_ HMIIOM SG_ 2499761675 ABSManAutoInhibitionStat 3000;
BA_REL_ "GenSigTimeoutTime" BU_SG_REL_ HMIIOM SG_ 2499761675 ABSManAutoInhibitionStat 300;
BA_REL_ "GenSigFirstTimeoutTime" BU_SG_REL_ VGGSECUSystem SG_ 2499761675 ABSManAutoInhibitionStat 3000;
BA_REL_ "GenSigTimeoutTime" BU_SG_REL_ VGGSECUSystem SG_ 2499761675 ABSManAutoInhibitionStat 240;
BA_REL_ "GenSigFirstTimeoutTime" BU_SG_REL_ DACU SG_ 2499761675 RearAxleSteeringFunctionStatus 3000;
BA_REL_ "GenSigTimeoutTime" BU_SG_REL_ DACU SG_ 2499761675 RearAxleSteeringFunctionStatus 600;
BA_REL_ "GenSigFirstTimeoutTime" BU_SG_REL_ CIOM SG_ 2499761675 RearAxleSteeringFunctionStatus 3000;
BA_REL_ "GenSigTimeoutTime" BU_SG_REL_ CIOM SG_ 2499761675 RearAxleSteeringFunctionStatus 300;
BA_REL_ "GenSigFirstTimeoutTime" BU_SG_REL_ HMIIOM SG_ 2499761675 AutoRearAxleDiffLockFnc_stat 3000;
BA_REL_ "GenSigTimeoutTime" BU_SG_REL_ HMIIOM SG_ 2499761675 AutoRearAxleDiffLockFnc_stat 300;
BA_REL_ "GenSigFirstTimeoutTime" BU_SG_REL_ HMIIOM SG_ 2499761675 WheelBrakeWarning 3000;
BA_REL_ "GenSigTimeoutTime" BU_SG_REL_ HMIIOM SG_ 2499761675 WheelBrakeWarning 300;
VAL_ 2566749463 FMS1_TellTaleStatus11 7 "TellTaleStatus_NotAvailable" 6 "TellTaleStatus_Reserved3" 5 "TellTaleStatus_Reserved2" 4 "TellTaleStatus_Reserved1" 3 "TellTaleStatus_Info" 2 "TellTaleStatus_Yellow" 1 "TellTaleStatus_Red" 0 "TellTaleStatus_Off" ;
VAL_ 2566749463 FMS1_TellTaleStatus3 7 "TellTaleStatus_NotAvailable" 6 "TellTaleStatus_Reserved3" 5 "TellTaleStatus_Reserved2" 4 "TellTaleStatus_Reserved1" 3 "TellTaleStatus_Info" 2 "TellTaleStatus_Yellow" 1 "TellTaleStatus_Red" 0 "TellTaleStatus_Off" ;
VAL_ 2566749463 FMS1_TellTaleStatus2 7 "TellTaleStatus_NotAvailable" 6 "TellTaleStatus_Reserved3" 5 "TellTaleStatus_Reserved2" 4 "TellTaleStatus_Reserved1" 3 "TellTaleStatus_Info" 2 "TellTaleStatus_Yellow" 1 "TellTaleStatus_Red" 0 "TellTaleStatus_Off" ;
VAL_ 2566749463 FMS1_TellTaleStatus6 7 "TellTaleStatus_NotAvailable" 6 "TellTaleStatus_Reserved3" 5 "TellTaleStatus_Reserved2" 4 "TellTaleStatus_Reserved1" 3 "TellTaleStatus_Info" 2 "TellTaleStatus_Yellow" 1 "TellTaleStatus_Red" 0 "TellTaleStatus_Off" ;
VAL_ 2566749463 FMS1_TellTaleStatus7 7 "TellTaleStatus_NotAvailable" 6 "TellTaleStatus_Reserved3" 5 "TellTaleStatus_Reserved2" 4 "TellTaleStatus_Reserved1" 3 "TellTaleStatus_Info" 2 "TellTaleStatus_Yellow" 1 "TellTaleStatus_Red" 0 "TellTaleStatus_Off" ;
VAL_ 2566749463 FMS1_TellTaleStatus5 7 "TellTaleStatus_NotAvailable" 6 "TellTaleStatus_Reserved3" 5 "TellTaleStatus_Reserved2" 4 "TellTaleStatus_Reserved1" 3 "TellTaleStatus_Info" 2 "TellTaleStatus_Yellow" 1 "TellTaleStatus_Red" 0 "TellTaleStatus_Off" ;
VAL_ 2566749463 FMS1_TellTaleStatus13 7 "TellTaleStatus_NotAvailable" 6 "TellTaleStatus_Reserved3" 5 "TellTaleStatus_Reserved2" 4 "TellTaleStatus_Reserved1" 3 "TellTaleStatus_Info" 2 "TellTaleStatus_Yellow" 1 "TellTaleStatus_Red" 0 "TellTaleStatus_Off" ;
VAL_ 2566749463 FMS1_TellTaleStatus9 7 "TellTaleStatus_NotAvailable" 6 "TellTaleStatus_Reserved3" 5 "TellTaleStatus_Reserved2" 4 "TellTaleStatus_Reserved1" 3 "TellTaleStatus_Info" 2 "TellTaleStatus_Yellow" 1 "TellTaleStatus_Red" 0 "TellTaleStatus_Off" ;
VAL_ 2566749463 FMS1_TellTaleStatus1 7 "TellTaleStatus_NotAvailable" 6 "TellTaleStatus_Reserved3" 5 "TellTaleStatus_Reserved2" 4 "TellTaleStatus_Reserved1" 3 "TellTaleStatus_Info" 2 "TellTaleStatus_Yellow" 1 "TellTaleStatus_Red" 0 "TellTaleStatus_Off" ;
VAL_ 2566749463 FMS1_TellTaleStatus4 7 "TellTaleStatus_NotAvailable" 6 "TellTaleStatus_Reserved3" 5 "TellTaleStatus_Reserved2" 4 "TellTaleStatus_Reserved1" 3 "TellTaleStatus_Info" 2 "TellTaleStatus_Yellow" 1 "TellTaleStatus_Red" 0 "TellTaleStatus_Off" ;
VAL_ 2566749463 FMS1_TellTaleStatus12 7 "TellTaleStatus_NotAvailable" 6 "TellTaleStatus_Reserved3" 5 "TellTaleStatus_Reserved2" 4 "TellTaleStatus_Reserved1" 3 "TellTaleStatus_Info" 2 "TellTaleStatus_Yellow" 1 "TellTaleStatus_Red" 0 "TellTaleStatus_Off" ;
VAL_ 2566749463 FMS1_TellTaleStatus14 7 "TellTaleStatus_NotAvailable" 6 "TellTaleStatus_Reserved3" 5 "TellTaleStatus_Reserved2" 4 "TellTaleStatus_Reserved1" 3 "TellTaleStatus_Info" 2 "TellTaleStatus_Yellow" 1 "TellTaleStatus_Red" 0 "TellTaleStatus_Off" ;
VAL_ 2566749463 FMS1_TellTaleStatus8 7 "TellTaleStatus_NotAvailable" 6 "TellTaleStatus_Reserved3" 5 "TellTaleStatus_Reserved2" 4 "TellTaleStatus_Reserved1" 3 "TellTaleStatus_Info" 2 "TellTaleStatus_Yellow" 1 "TellTaleStatus_Red" 0 "TellTaleStatus_Off" ;
VAL_ 2566749463 FMS1_TellTaleStatus15 7 "TellTaleStatus_NotAvailable" 6 "TellTaleStatus_Reserved3" 5 "TellTaleStatus_Reserved2" 4 "TellTaleStatus_Reserved1" 3 "TellTaleStatus_Info" 2 "TellTaleStatus_Yellow" 1 "TellTaleStatus_Red" 0 "TellTaleStatus_Off" ;
VAL_ 2566749463 FMS1_TellTaleStatus10 7 "TellTaleStatus_NotAvailable" 6 "TellTaleStatus_Reserved3" 5 "TellTaleStatus_Reserved2" 4 "TellTaleStatus_Reserved1" 3 "TellTaleStatus_Info" 2 "TellTaleStatus_Yellow" 1 "TellTaleStatus_Red" 0 "TellTaleStatus_Off" ;
VAL_ 2566801923 TransmEngineCrankEnable2 3 "DisableEnable_NotAvailable" 2 "DisableEnable_Error" 1 "DisableEnable_Enable" 0 "DisableEnable_Disable" ;
VAL_ 2364539395 TransmTrqConvrtrLockupEngd 3 "DisengageEngage_NotAvailable" 2 "DisengageEngage_Error" 1 "DisengageEngage_Engage" 0 "DisengageEngage_Disengage" ;
VAL_ 2364539395 TransmissionDrivelineEngaged 3 "DisengageEngage_NotAvailable" 2 "DisengageEngage_Error" 1 "DisengageEngage_Engage" 0 "DisengageEngage_Disengage" ;
VAL_ 2364539395 MomentaryEngineOverspeedEnable 3 "DisableEnable_NotAvailable" 2 "DisableEnable_Error" 1 "DisableEnable_Enable" 0 "DisableEnable_Disable" ;
VAL_ 2364539395 TransmissionShiftInProcess 3 "TransmissionShiftInProcess_NotAvailable" 2 "TransmissionShiftInProcess_Error" 1 "TransmissionShiftInProcess_ShiftInProcess" 0 "TransmissionShiftInProcess_ShiftNotInProcess" ;
VAL_ 2558984359 RequestedFuelTypeVGGS 255 "RequestedFuelType_NotAvailable" 31 "RequestedFuelType_Kerosene" 23 "RequestedFuelType_NaturalGas_NG" 8 "RequestedFuelType_BatteryElectric_ELEC" 7 "RequestedFuelType_Propane_PROP" 6 "RequestedFuelType_CompressedNaturalGas_CNG" 5 "RequestedFuelType_LiquefiedPetroleumGas_LPG" 4 "RequestedFuelType_Diesel_DSL" 3 "RequestedFuelType_Ethanol_ETH" 2 "RequestedFuelType_Methanol_METH" 1 "RequestedFuelType_GasolinePetrol_GAS" 0 "RequestedFuelType_NotAvailable_NONE" ;
VAL_ 2565865488 EngineCoolantLoadIncrease 3 "EngineCoolantLoadIncrease_NotAvailable" 2 "EngineCoolantLoadIncrease_Error" 1 "EngineCoolantLoadIncrease_CoolantLoadIncreasePossible" 0 "EngineCoolantLoadIncrease_NoCoolantLoadIncrease" ;
VAL_ 2565865488 RetarderTorqueMode 15 "RetarderTorqueMode_NotAvailable" 14 "RetarderTorqueMode_Other" 13 "RetarderTorqueMode_NotDefined" 12 "RetarderTorqueMode_ServiceProcedure" 11 "RetarderTorqueMode_RemoteAccelerator" 10 "RetarderTorqueMode_BrakingSystem" 9 "RetarderTorqueMode_HighSpeedGovernor" 8 "RetarderTorqueMode_TorqueLimiting" 7 "RetarderTorqueMode_ABSControl" 6 "RetarderTorqueMode_TransmissionControl" 5 "RetarderTorqueMode_ASRControl" 4 "RetarderTorqueMode_RoadSpeedGovernor" 3 "RetarderTorqueMode_PTOGovernor" 2 "RetarderTorqueMode_CruiseControl" 1 "RetarderTorqueMode_AcceleratorPedalOperatorSelection" 0 "RetarderTorqueMode_LowIdleGovernorNoRequestDefaultMode" ;
VAL_ 2565865487 RetarderEnableShiftAssistSw 3 "DisableEnable_NotAvailable" 2 "DisableEnable_Error" 1 "DisableEnable_Enable" 0 "DisableEnable_Disable" ;
VAL_ 2565865487 EngineRetarderTorqueMode 15 "EngineRetarderTorqueMode_NotAvailable" 14 "EngineRetarderTorqueMode_Other" 13 "EngineRetarderTorqueMode_NotDefined" 12 "EngineRetarderTorqueMode_ServiceProcedure" 11 "EngineRetarderTorqueMode_RemoteAccelerator" 10 "EngineRetarderTorqueMode_BrakingSystem" 9 "EngineRetarderTorqueMode_HighSpeedGovernor" 8 "EngineRetarderTorqueMode_TorqueLimiting" 7 "EngineRetarderTorqueMode_ABSControl" 6 "EngineRetarderTorqueMode_TransmissionControl" 5 "EngineRetarderTorqueMode_ASRControl" 4 "EngineRetarderTorqueMode_RoadSpeedGovernor" 3 "EngineRetarderTorqueMode_PTOGovernor" 2 "EngineRetarderTorqueMode_CruiseControl" 1 "EngineRetarderTorqueMode_AcceleratorPedalOperatorSelection" 0 "EngineRetarderTorqueMode_LowIdleGovernorNoRequestDefaultMode" ;
VAL_ 2565865487 EngRetdrEnableBrakeAssistSw 3 "DisableEnable_NotAvailable" 2 "DisableEnable_Error" 1 "DisableEnable_Enable" 0 "DisableEnable_Disable" ;
VAL_ 2364539648 AcctrPedalKickDownSw_stat_2 3 "PassiveActive_NotAvailable" 2 "PassiveActive_Error" 1 "PassiveActive_Active" 0 "PassiveActive_Passive" ;
VAL_ 2364539648 RoadSpeedLimitStatus 3 "ActiveNotActive_NotAvailable" 2 "ActiveNotActive_Error" 1 "ActiveNotActive_NotActive" 0 "ActiveNotActive_Active" ;
VAL_ 2364539904 EngineTorqueMode 15 "EngineTorqueMode_NotAvailable" 14 "EngineTorqueMode_Other" 13 "EngineTorqueMode_AirManagement" 12 "EngineTorqueMode_ServiceProcedure" 11 "EngineTorqueMode_RemoteAccelerator" 10 "EngineTorqueMode_BrakingSystem" 9 "EngineTorqueMode_HighSpeedGovernor" 8 "EngineTorqueMode_TorqueLimiting" 7 "EngineTorqueMode_ABSControl" 6 "EngineTorqueMode_TransmissionControl" 5 "EngineTorqueMode_ASRControl" 4 "EngineTorqueMode_RoadSpeedGovernor" 3 "EngineTorqueMode_PTOGovernor" 2 "EngineTorqueMode_CruiseControl" 1 "EngineTorqueMode_AcceleratorPedalOperatorSelection" 0 "EngineTorqueMode_LowIdleGovernorNoRequestDefaultMode" ;
VAL_ 2364539904 EngineStarterMode 15 "EngineStarterMode_NotAvailable" 14 "EngineStarterMode_Error" 13 "EngineStarterMode_NotToBeUsed" 12 "EngineStarterMode_StarterInhibitedReasonUnknown" 11 "EngineStarterMode_Reserved_02" 10 "EngineStarterMode_Reserved_01" 9 "EngineStarterMode_Reserved" 8 "EngineStarterMode_StarterInhibitedDueToStarterOverTemp" 7 "EngineStarterMode_StarterInhibitedDueToActiveImmobilizer" 6 "EngineStarterMode_StarterInhibitedDueToDrivelineEngagedOrOther" 5 "EngineStarterMode_StarterInhibitedDueToEngineNotReadyForStart" 4 "EngineStarterMode_StarterInhibitedDueToEngineAlreadyRunning" 3 "EngineStarterMode_StartFinishedStarterNotActiveAfterHavingBe" 2 "EngineStarterMode_StarterActiveGearEngaged" 1 "EngineStarterMode_StarterActiveGearNotEngaged" 0 "EngineStarterMode_StartNotRequested" ;
VAL_ 2566767104 FuelTypeEMS 255 "FuelTypeEMS_NotAvailable" 254 "FuelTypeEMS_Error" 31 "FuelTypeEMS_Kerosene" 30 "FuelTypeEMS_HydrogenInternalCombustionEngine" 29 "FuelTypeEMS_FuelCellUtilizingHydrogen" 28 "FuelTypeEMS_DualFuel_DieselAndLNG" 27 "FuelTypeEMS_DualFuel_DieselAndCNG" 26 "FuelTypeEMS_NaturalGasCompressedOrLiquefied" 25 "FuelTypeEMS_BifuelDiesel" 24 "FuelTypeEMS_BifuelVehicleNG_BI_NG" 23 "FuelTypeEMS_NaturalGas_NG" 22 "FuelTypeEMS_HybridVehicleRegenerationMode_HYB_REG" 21 "FuelTypeEMS_HybridVehicleBatteryAndCombustion_HYB_MIX" 20 "FuelTypeEMS_HybridVehicleBattery_HYB_ELEC" 19 "FuelTypeEMS_HybridVehicleDiesel_HYB_DSL" 18 "FuelTypeEMS_HybridVehicleEthanol_HYB_ETH" 17 "FuelTypeEMS_HybridVehicleGasoline_HYB_GAS" 16 "FuelTypeEMS_BifuelVehicleBatteryCombustion_BI_MIX" 15 "FuelTypeEMS_BifuelVehicleBattery_BI_ELEC" 14 "FuelTypeEMS_BifuelVehiclePropane_BI_PROP" 13 "FuelTypeEMS_BifuelVehicleCNG_BI_CNG" 12 "FuelTypeEMS_BifuelVehicleLPG_BI_LPG" 11 "FuelTypeEMS_BifuelVehicleEthanol_BI_ETH" 10 "FuelTypeEMS_BifuelVehicleMethanol_BI_METH" 9 "FuelTypeEMS_BifuelVehicleGasoline_BI_GAS" 8 "FuelTypeEMS_BatteryElectric_ELEC" 7 "FuelTypeEMS_Propane_PROP" 6 "FuelTypeEMS_CompressedNaturalGas_CNG" 5 "FuelTypeEMS_LiquefiedPetroleumGas_LPG" 4 "FuelTypeEMS_Diesel_DSL" 3 "FuelTypeEMS_Ethanol_ETH" 2 "FuelTypeEMS_Methanol_METH" 1 "FuelTypeEMS_GasolinePetrol_GAS" 0 "FuelTypeEMS_NotAvailable_NONE" ;
VAL_ 2566903051 Trailer5GeometricData_Index 255 "TrailerGeometricDataIndex_NotAvailable" 254 "TrailerGeometricDataIndex_Error" 38 "TrailerGeometricDataIndex_TrailerHeightRear" 37 "TrailerGeometricDataIndex_ChassisHeight" 36 "TrailerGeometricDataIndex_TrailerHeightFront" 35 "TrailerGeometricDataIndex_LoadingHeightFront" 34 "TrailerGeometricDataIndex_LoadingHeightRear" 33 "TrailerGeometricDataIndex_CouplingHeight2" 32 "TrailerGeometricDataIndex_CouplingHeight1" 31 "TrailerGeometricDataIndex_TotalLengthOfTrailer" 30 "TrailerGeometricDataIndex_DistanceFirstToSecondCouplingPoint" 29 "TrailerGeometricDataIndex_WheelBaseAxle19ToAxle20" 28 "TrailerGeometricDataIndex_WheelBaseAxle18ToAxle19" 27 "TrailerGeometricDataIndex_WheelBaseAxle17ToAxle18" 26 "TrailerGeometricDataIndex_WheelBaseAxle16ToAxle17" 25 "TrailerGeometricDataIndex_WheelBaseAxle15ToAxle16" 24 "TrailerGeometricDataIndex_WheelBaseAxle14ToAxle15" 23 "TrailerGeometricDataIndex_WheelBaseAxle13ToAxle14" 22 "TrailerGeometricDataIndex_WheelBaseAxle12ToAxle13" 21 "TrailerGeometricDataIndex_WheelBaseAxle11ToAxle12" 20 "TrailerGeometricDataIndex_WheelBaseAxle10ToAxle11" 19 "TrailerGeometricDataIndex_WheelBaseAxle9ToAxle10" 18 "TrailerGeometricDataIndex_WheelBaseAxle8ToAxle9" 17 "TrailerGeometricDataIndex_WheelBaseAxle7ToAxle8" 16 "TrailerGeometricDataIndex_WheelBaseAxle6ToAxle7" 15 "TrailerGeometricDataIndex_WheelBaseAxle5ToAxle6" 14 "TrailerGeometricDataIndex_WheelBaseAxle4ToAxle5" 13 "TrailerGeometricDataIndex_WheelBaseAxle3ToAxle4" 12 "TrailerGeometricDataIndex_WheelBaseAxle2ToAxle3" 11 "TrailerGeometricDataIndex_WheelBaseAxle1ToAxle2" 10 "TrailerGeometricDataIndex_AxleNumberOfLiftAxle5" 9 "TrailerGeometricDataIndex_AxleNumberOfLiftAxle4" 8 "TrailerGeometricDataIndex_AxleNumberOfLiftAxle3" 7 "TrailerGeometricDataIndex_AxleNumberOfLiftAxle2" 6 "TrailerGeometricDataIndex_AxleNumberOfLiftAxle1" 5 "TrailerGeometricDataIndex_NumberOfLiftAxles" 4 "TrailerGeometricDataIndex_NumberOfFrontAxles" 3 "TrailerGeometricDataIndex_NumberOfAxles" 2 "TrailerGeometricDataIndex_TrackWidth" 1 "TrailerGeometricDataIndex_DistanceCouplingToAxle1" 0 "TrailerGeometricDataIndex_TypeOfTrailer" ;
VAL_ 2566903051 PadChangePredictionAxleNumber 7 "PadChangePredictionAxleNumber_Spare_01" 6 "PadChangePredictionAxleNumber_Spare" 5 "PadChangePredictionAxleNumber_AxleNo5" 4 "PadChangePredictionAxleNumber_AxleNo4" 3 "PadChangePredictionAxleNumber_AxleNo3" 2 "PadChangePredictionAxleNumber_AxleNo2" 1 "PadChangePredictionAxleNumber_AxleNo1" 0 "PadChangePredictionAxleNumber_NotApplicable" ;
VAL_ 2566903051 LiningWearWarning 3 "Warning_NotAvailable" 2 "Warning_Error" 1 "Warning_Warning" 0 "Warning_NoWarning" ;
VAL_ 2566902539 Trailer3GeometricData_Index 255 "TrailerGeometricDataIndex_NotAvailable" 254 "TrailerGeometricDataIndex_Error" 38 "TrailerGeometricDataIndex_TrailerHeightRear" 37 "TrailerGeometricDataIndex_ChassisHeight" 36 "TrailerGeometricDataIndex_TrailerHeightFront" 35 "TrailerGeometricDataIndex_LoadingHeightFront" 34 "TrailerGeometricDataIndex_LoadingHeightRear" 33 "TrailerGeometricDataIndex_CouplingHeight2" 32 "TrailerGeometricDataIndex_CouplingHeight1" 31 "TrailerGeometricDataIndex_TotalLengthOfTrailer" 30 "TrailerGeometricDataIndex_DistanceFirstToSecondCouplingPoint" 29 "TrailerGeometricDataIndex_WheelBaseAxle19ToAxle20" 28 "TrailerGeometricDataIndex_WheelBaseAxle18ToAxle19" 27 "TrailerGeometricDataIndex_WheelBaseAxle17ToAxle18" 26 "TrailerGeometricDataIndex_WheelBaseAxle16ToAxle17" 25 "TrailerGeometricDataIndex_WheelBaseAxle15ToAxle16" 24 "TrailerGeometricDataIndex_WheelBaseAxle14ToAxle15" 23 "TrailerGeometricDataIndex_WheelBaseAxle13ToAxle14" 22 "TrailerGeometricDataIndex_WheelBaseAxle12ToAxle13" 21 "TrailerGeometricDataIndex_WheelBaseAxle11ToAxle12" 20 "TrailerGeometricDataIndex_WheelBaseAxle10ToAxle11" 19 "TrailerGeometricDataIndex_WheelBaseAxle9ToAxle10" 18 "TrailerGeometricDataIndex_WheelBaseAxle8ToAxle9" 17 "TrailerGeometricDataIndex_WheelBaseAxle7ToAxle8" 16 "TrailerGeometricDataIndex_WheelBaseAxle6ToAxle7" 15 "TrailerGeometricDataIndex_WheelBaseAxle5ToAxle6" 14 "TrailerGeometricDataIndex_WheelBaseAxle4ToAxle5" 13 "TrailerGeometricDataIndex_WheelBaseAxle3ToAxle4" 12 "TrailerGeometricDataIndex_WheelBaseAxle2ToAxle3" 11 "TrailerGeometricDataIndex_WheelBaseAxle1ToAxle2" 10 "TrailerGeometricDataIndex_AxleNumberOfLiftAxle5" 9 "TrailerGeometricDataIndex_AxleNumberOfLiftAxle4" 8 "TrailerGeometricDataIndex_AxleNumberOfLiftAxle3" 7 "TrailerGeometricDataIndex_AxleNumberOfLiftAxle2" 6 "TrailerGeometricDataIndex_AxleNumberOfLiftAxle1" 5 "TrailerGeometricDataIndex_NumberOfLiftAxles" 4 "TrailerGeometricDataIndex_NumberOfFrontAxles" 3 "TrailerGeometricDataIndex_NumberOfAxles" 2 "TrailerGeometricDataIndex_TrackWidth" 1 "TrailerGeometricDataIndex_DistanceCouplingToAxle1" 0 "TrailerGeometricDataIndex_TypeOfTrailer" ;
VAL_ 2566902539 Trailer4GeometricData_Index 255 "TrailerGeometricDataIndex_NotAvailable" 254 "TrailerGeometricDataIndex_Error" 38 "TrailerGeometricDataIndex_TrailerHeightRear" 37 "TrailerGeometricDataIndex_ChassisHeight" 36 "TrailerGeometricDataIndex_TrailerHeightFront" 35 "TrailerGeometricDataIndex_LoadingHeightFront" 34 "TrailerGeometricDataIndex_LoadingHeightRear" 33 "TrailerGeometricDataIndex_CouplingHeight2" 32 "TrailerGeometricDataIndex_CouplingHeight1" 31 "TrailerGeometricDataIndex_TotalLengthOfTrailer" 30 "TrailerGeometricDataIndex_DistanceFirstToSecondCouplingPoint" 29 "TrailerGeometricDataIndex_WheelBaseAxle19ToAxle20" 28 "TrailerGeometricDataIndex_WheelBaseAxle18ToAxle19" 27 "TrailerGeometricDataIndex_WheelBaseAxle17ToAxle18" 26 "TrailerGeometricDataIndex_WheelBaseAxle16ToAxle17" 25 "TrailerGeometricDataIndex_WheelBaseAxle15ToAxle16" 24 "TrailerGeometricDataIndex_WheelBaseAxle14ToAxle15" 23 "TrailerGeometricDataIndex_WheelBaseAxle13ToAxle14" 22 "TrailerGeometricDataIndex_WheelBaseAxle12ToAxle13" 21 "TrailerGeometricDataIndex_WheelBaseAxle11ToAxle12" 20 "TrailerGeometricDataIndex_WheelBaseAxle10ToAxle11" 19 "TrailerGeometricDataIndex_WheelBaseAxle9ToAxle10" 18 "TrailerGeometricDataIndex_WheelBaseAxle8ToAxle9" 17 "TrailerGeometricDataIndex_WheelBaseAxle7ToAxle8" 16 "TrailerGeometricDataIndex_WheelBaseAxle6ToAxle7" 15 "TrailerGeometricDataIndex_WheelBaseAxle5ToAxle6" 14 "TrailerGeometricDataIndex_WheelBaseAxle4ToAxle5" 13 "TrailerGeometricDataIndex_WheelBaseAxle3ToAxle4" 12 "TrailerGeometricDataIndex_WheelBaseAxle2ToAxle3" 11 "TrailerGeometricDataIndex_WheelBaseAxle1ToAxle2" 10 "TrailerGeometricDataIndex_AxleNumberOfLiftAxle5" 9 "TrailerGeometricDataIndex_AxleNumberOfLiftAxle4" 8 "TrailerGeometricDataIndex_AxleNumberOfLiftAxle3" 7 "TrailerGeometricDataIndex_AxleNumberOfLiftAxle2" 6 "TrailerGeometricDataIndex_AxleNumberOfLiftAxle1" 5 "TrailerGeometricDataIndex_NumberOfLiftAxles" 4 "TrailerGeometricDataIndex_NumberOfFrontAxles" 3 "TrailerGeometricDataIndex_NumberOfAxles" 2 "TrailerGeometricDataIndex_TrackWidth" 1 "TrailerGeometricDataIndex_DistanceCouplingToAxle1" 0 "TrailerGeometricDataIndex_TypeOfTrailer" ;
VAL_ 2566902027 Trailer2GeometricData_Index 255 "TrailerGeometricDataIndex_NotAvailable" 254 "TrailerGeometricDataIndex_Error" 38 "TrailerGeometricDataIndex_TrailerHeightRear" 37 "TrailerGeometricDataIndex_ChassisHeight" 36 "TrailerGeometricDataIndex_TrailerHeightFront" 35 "TrailerGeometricDataIndex_LoadingHeightFront" 34 "TrailerGeometricDataIndex_LoadingHeightRear" 33 "TrailerGeometricDataIndex_CouplingHeight2" 32 "TrailerGeometricDataIndex_CouplingHeight1" 31 "TrailerGeometricDataIndex_TotalLengthOfTrailer" 30 "TrailerGeometricDataIndex_DistanceFirstToSecondCouplingPoint" 29 "TrailerGeometricDataIndex_WheelBaseAxle19ToAxle20" 28 "TrailerGeometricDataIndex_WheelBaseAxle18ToAxle19" 27 "TrailerGeometricDataIndex_WheelBaseAxle17ToAxle18" 26 "TrailerGeometricDataIndex_WheelBaseAxle16ToAxle17" 25 "TrailerGeometricDataIndex_WheelBaseAxle15ToAxle16" 24 "TrailerGeometricDataIndex_WheelBaseAxle14ToAxle15" 23 "TrailerGeometricDataIndex_WheelBaseAxle13ToAxle14" 22 "TrailerGeometricDataIndex_WheelBaseAxle12ToAxle13" 21 "TrailerGeometricDataIndex_WheelBaseAxle11ToAxle12" 20 "TrailerGeometricDataIndex_WheelBaseAxle10ToAxle11" 19 "TrailerGeometricDataIndex_WheelBaseAxle9ToAxle10" 18 "TrailerGeometricDataIndex_WheelBaseAxle8ToAxle9" 17 "TrailerGeometricDataIndex_WheelBaseAxle7ToAxle8" 16 "TrailerGeometricDataIndex_WheelBaseAxle6ToAxle7" 15 "TrailerGeometricDataIndex_WheelBaseAxle5ToAxle6" 14 "TrailerGeometricDataIndex_WheelBaseAxle4ToAxle5" 13 "TrailerGeometricDataIndex_WheelBaseAxle3ToAxle4" 12 "TrailerGeometricDataIndex_WheelBaseAxle2ToAxle3" 11 "TrailerGeometricDataIndex_WheelBaseAxle1ToAxle2" 10 "TrailerGeometricDataIndex_AxleNumberOfLiftAxle5" 9 "TrailerGeometricDataIndex_AxleNumberOfLiftAxle4" 8 "TrailerGeometricDataIndex_AxleNumberOfLiftAxle3" 7 "TrailerGeometricDataIndex_AxleNumberOfLiftAxle2" 6 "TrailerGeometricDataIndex_AxleNumberOfLiftAxle1" 5 "TrailerGeometricDataIndex_NumberOfLiftAxles" 4 "TrailerGeometricDataIndex_NumberOfFrontAxles" 3 "TrailerGeometricDataIndex_NumberOfAxles" 2 "TrailerGeometricDataIndex_TrackWidth" 1 "TrailerGeometricDataIndex_DistanceCouplingToAxle1" 0 "TrailerGeometricDataIndex_TypeOfTrailer" ;
VAL_ 2566902027 Trailer1GeometricData_Index 255 "TrailerGeometricDataIndex_NotAvailable" 254 "TrailerGeometricDataIndex_Error" 38 "TrailerGeometricDataIndex_TrailerHeightRear" 37 "TrailerGeometricDataIndex_ChassisHeight" 36 "TrailerGeometricDataIndex_TrailerHeightFront" 35 "TrailerGeometricDataIndex_LoadingHeightFront" 34 "TrailerGeometricDataIndex_LoadingHeightRear" 33 "TrailerGeometricDataIndex_CouplingHeight2" 32 "TrailerGeometricDataIndex_CouplingHeight1" 31 "TrailerGeometricDataIndex_TotalLengthOfTrailer" 30 "TrailerGeometricDataIndex_DistanceFirstToSecondCouplingPoint" 29 "TrailerGeometricDataIndex_WheelBaseAxle19ToAxle20" 28 "TrailerGeometricDataIndex_WheelBaseAxle18ToAxle19" 27 "TrailerGeometricDataIndex_WheelBaseAxle17ToAxle18" 26 "TrailerGeometricDataIndex_WheelBaseAxle16ToAxle17" 25 "TrailerGeometricDataIndex_WheelBaseAxle15ToAxle16" 24 "TrailerGeometricDataIndex_WheelBaseAxle14ToAxle15" 23 "TrailerGeometricDataIndex_WheelBaseAxle13ToAxle14" 22 "TrailerGeometricDataIndex_WheelBaseAxle12ToAxle13" 21 "TrailerGeometricDataIndex_WheelBaseAxle11ToAxle12" 20 "TrailerGeometricDataIndex_WheelBaseAxle10ToAxle11" 19 "TrailerGeometricDataIndex_WheelBaseAxle9ToAxle10" 18 "TrailerGeometricDataIndex_WheelBaseAxle8ToAxle9" 17 "TrailerGeometricDataIndex_WheelBaseAxle7ToAxle8" 16 "TrailerGeometricDataIndex_WheelBaseAxle6ToAxle7" 15 "TrailerGeometricDataIndex_WheelBaseAxle5ToAxle6" 14 "TrailerGeometricDataIndex_WheelBaseAxle4ToAxle5" 13 "TrailerGeometricDataIndex_WheelBaseAxle3ToAxle4" 12 "TrailerGeometricDataIndex_WheelBaseAxle2ToAxle3" 11 "TrailerGeometricDataIndex_WheelBaseAxle1ToAxle2" 10 "TrailerGeometricDataIndex_AxleNumberOfLiftAxle5" 9 "TrailerGeometricDataIndex_AxleNumberOfLiftAxle4" 8 "TrailerGeometricDataIndex_AxleNumberOfLiftAxle3" 7 "TrailerGeometricDataIndex_AxleNumberOfLiftAxle2" 6 "TrailerGeometricDataIndex_AxleNumberOfLiftAxle1" 5 "TrailerGeometricDataIndex_NumberOfLiftAxles" 4 "TrailerGeometricDataIndex_NumberOfFrontAxles" 3 "TrailerGeometricDataIndex_NumberOfAxles" 2 "TrailerGeometricDataIndex_TrackWidth" 1 "TrailerGeometricDataIndex_DistanceCouplingToAxle1" 0 "TrailerGeometricDataIndex_TypeOfTrailer" ;
VAL_ 2566886667 Trailer5LiftAxle1Pos 3 "TrailerLiftAxlePos_NotAvailable" 2 "TrailerLiftAxlePos_Error" 1 "TrailerLiftAxlePos_AxleLifted" 0 "TrailerLiftAxlePos_AxleDown" ;
VAL_ 2566886667 Trailer5LiftAxle2Pos 3 "TrailerLiftAxlePos_NotAvailable" 2 "TrailerLiftAxlePos_Error" 1 "TrailerLiftAxlePos_AxleLifted" 0 "TrailerLiftAxlePos_AxleDown" ;
VAL_ 2566886155 FrontParkBrakeOverrideStatus 3 "InactiveActive_NotAvailable" 2 "InactiveActive_Error" 1 "InactiveActive_Active" 0 "InactiveActive_Inactive" ;
VAL_ 2566886155 Trailer3LiftAxle1Pos 3 "TrailerLiftAxlePos_NotAvailable" 2 "TrailerLiftAxlePos_Error" 1 "TrailerLiftAxlePos_AxleLifted" 0 "TrailerLiftAxlePos_AxleDown" ;
VAL_ 2566886155 Trailer4LiftAxle2Pos 3 "TrailerLiftAxlePos_NotAvailable" 2 "TrailerLiftAxlePos_Error" 1 "TrailerLiftAxlePos_AxleLifted" 0 "TrailerLiftAxlePos_AxleDown" ;
VAL_ 2566886155 Trailer3LiftAxle2Pos 3 "TrailerLiftAxlePos_NotAvailable" 2 "TrailerLiftAxlePos_Error" 1 "TrailerLiftAxlePos_AxleLifted" 0 "TrailerLiftAxlePos_AxleDown" ;
VAL_ 2566886155 Trailer4LiftAxle1Pos 3 "TrailerLiftAxlePos_NotAvailable" 2 "TrailerLiftAxlePos_Error" 1 "TrailerLiftAxlePos_AxleLifted" 0 "TrailerLiftAxlePos_AxleDown" ;
VAL_ 2566885643 Trailer2LiftAxle2Pos 3 "TrailerLiftAxlePos_NotAvailable" 2 "TrailerLiftAxlePos_Error" 1 "TrailerLiftAxlePos_AxleLifted" 0 "TrailerLiftAxlePos_AxleDown" ;
VAL_ 2566885643 TrailerEBSFault 3 "OkNok_NotAvailable" 2 "OkNok_Error" 1 "OkNok_NotOK" 0 "OkNok_OK" ;
VAL_ 2566885643 Trailer1LiftAxle1Pos 3 "TrailerLiftAxlePos_NotAvailable" 2 "TrailerLiftAxlePos_Error" 1 "TrailerLiftAxlePos_AxleLifted" 0 "TrailerLiftAxlePos_AxleDown" ;
VAL_ 2566885643 Trailer1LiftAxle2Pos 3 "TrailerLiftAxlePos_NotAvailable" 2 "TrailerLiftAxlePos_Error" 1 "TrailerLiftAxlePos_AxleLifted" 0 "TrailerLiftAxlePos_AxleDown" ;
VAL_ 2566885643 Trailer2LiftAxle1Pos 3 "TrailerLiftAxlePos_NotAvailable" 2 "TrailerLiftAxlePos_Error" 1 "TrailerLiftAxlePos_AxleLifted" 0 "TrailerLiftAxlePos_AxleDown" ;
VAL_ 2499761675 BadBrakeBalanceWarning 3 "Warning_NotAvailable" 2 "Warning_Error" 1 "Warning_Warning" 0 "Warning_NoWarning" ;
VAL_ 2499761675 HSAAvailability 3 "NotAvailable_NotAvailable" 2 "NotAvailable_Error" 1 "NotAvailable_FunctionAvailable" 0 "NotAvailable_FunctionNotAvailable" ;
VAL_ 2499761675 DTCActive 3 "DTCActive_DTCStatusInfoNotAvailableOrNotSupported" 2 "DTCActive_ErrorIndicator" 1 "DTCActive_DTCActive" 0 "DTCActive_DTCStatusInfoAvailableButNotActive" ;
VAL_ 2499761675 StretchBrake_Stat 7 "StretchBrake_Stat_NotAvailable" 6 "StretchBrake_Stat_Error" 5 "StretchBrake_Stat_Spare_02" 4 "StretchBrake_Stat_Spare_01" 3 "StretchBrake_Stat_Spare" 2 "StretchBrake_Stat_Active" 1 "StretchBrake_Stat_Enabled" 0 "StretchBrake_Stat_Disabled" ;
VAL_ 2499761675 TrcnCtrlSlipperyRoadWarning 3 "InactiveActive_NotAvailable" 2 "InactiveActive_Error" 1 "InactiveActive_Active" 0 "InactiveActive_Inactive" ;
VAL_ 2499761675 RearAxleDiffLockActvnFuncReq 3 "RearAxleDiffLockActvnFuncReq_TakeNoAction" 2 "RearAxleDiffLockActvnFuncReq_Reserved" 1 "RearAxleDiffLockActvnFuncReq_DisengageDifferentialLock" 0 "RearAxleDiffLockActvnFuncReq_EngageDifferentialLock" ;
VAL_ 2499761675 RollerBenchModeStatus 3 "InactiveActive_NotAvailable" 2 "InactiveActive_Error" 1 "InactiveActive_Active" 0 "InactiveActive_Inactive" ;
VAL_ 2499761675 BrakeAssistStatus 3 "OffOn_NotAvailable" 2 "OffOn_Error" 1 "OffOn_On" 0 "OffOn_Off" ;
VAL_ 2499761675 TractionFunctionSelected 7 "TractionFunctionSelected_NotAvailable" 6 "TractionFunctionSelected_Error" 5 "TractionFunctionSelected_Spare_02" 4 "TractionFunctionSelected_Spare_01" 3 "TractionFunctionSelected_Spare" 2 "TractionFunctionSelected_TractionOFFROAD" 1 "TractionFunctionSelected_TractionOFF" 0 "TractionFunctionSelected_TractionON" ;
VAL_ 2499761675 PoorBrakePerformanceWarning 3 "Warning_NotAvailable" 2 "Warning_Error" 1 "Warning_Warning" 0 "Warning_NoWarning" ;
VAL_ 2499761675 VDCActive 3 "VDCActive_NotAvailableOrNotInstalled" 2 "VDCActive_ErrorIndicator" 1 "VDCActive_VDCActive" 0 "VDCActive_VDCPassiveButInstalled" ;
VAL_ 2499761675 ABSInhibitionStatus 3 "Inhibit_NotAvailable" 2 "Inhibit_Error" 1 "Inhibit_InhibitActive" 0 "Inhibit_NoInhibit" ;
VAL_ 2499761675 ABSManAutoInhibitionStat 7 "ABSManAutoInhibitionStat_NotAvailable" 6 "ABSManAutoInhibitionStat_Error" 5 "ABSManAutoInhibitionStat_Spare02" 4 "ABSManAutoInhibitionStat_Spare01" 3 "ABSManAutoInhibitionStat_Spare" 2 "ABSManAutoInhibitionStat_ABSAutomaticInhibition" 1 "ABSManAutoInhibitionStat_ABSManualInhibition" 0 "ABSManAutoInhibitionStat_ABSNoInhibition" ;
VAL_ 2499761675 RearAxleSteeringFunctionStatus 7 "RearAxleSteeringFunctionStatus_NotAvailable" 6 "RearAxleSteeringFunctionStatus_Error" 5 "RearAxleSteeringFunctionStatus_SpareValue_01" 4 "RearAxleSteeringFunctionStatus_SpareValue" 3 "RearAxleSteeringFunctionStatus_ActiveFailureMode" 2 "RearAxleSteeringFunctionStatus_PassiveFailureMode" 1 "RearAxleSteeringFunctionStatus_Active" 0 "RearAxleSteeringFunctionStatus_NotActive" ;
VAL_ 2499761675 AutoRearAxleDiffLockFnc_stat 3 "InactiveActive_NotAvailable" 2 "InactiveActive_Error" 1 "InactiveActive_Active" 0 "InactiveActive_Inactive" ;
VAL_ 2499761675 WheelBrakeWarning 3 "OffOn_NotAvailable" 2 "OffOn_Error" 1 "OffOn_On" 0 "OffOn_Off" ;
SIG_GROUP_ 2566749463 FMS1_sg 1 : FMS1_TellTaleStatus11 FMS1_TellTaleStatus3 FMS1_Blockid FMS1_TellTaleStatus2 FMS1_TellTaleStatus6 FMS1_TellTaleStatus7 FMS1_TellTaleStatus5 FMS1_TellTaleStatus13 FMS1_TellTaleStatus9 FMS1_TellTaleStatus1 FMS1_TellTaleStatus4 FMS1_TellTaleStatus12 FMS1_TellTaleStatus14 FMS1_TellTaleStatus8 FMS1_TellTaleStatus15 FMS1_TellTaleStatus10;
SIG_GROUP_ 2566903051 Trailer5GeometricData_sg 1 : Trailer5GeometricData_Index Trailer5GeometricData_Content;
SIG_GROUP_ 2566902539 Trailer4GeometricData_sg 1 : Trailer4GeometricData_Content Trailer4GeometricData_Index;
SIG_GROUP_ 2566902539 Trailer3GeometricData_sg 1 : Trailer3GeometricData_Index Trailer3GeometricData_Content;
SIG_GROUP_ 2566902027 Trailer1GeometricData_sg 1 : Trailer1GeometricData_Content Trailer1GeometricData_Index;
SIG_GROUP_ 2566902027 Trailer2GeometricData_sg 1 : Trailer2GeometricData_Index Trailer2GeometricData_Content;
SIG_GROUP_ 2566886667 Trailer5AxleLoad_sg 1 : Trailer5AxleLoad_AxleLoad Trailer5AxleLoad_AxleId;
SIG_GROUP_ 2566886155 Trailer3AxleLoad_sg 1 : Trailer3AxleLoad_AxleId Trailer3AxleLoad_AxleLoad;
SIG_GROUP_ 2566886155 Trailer4AxleLoad_sg 1 : Trailer4AxleLoad_AxleLoad Trailer4AxleLoad_AxleId;
SIG_GROUP_ 2566885643 Trailer2AxleLoad_sg 1 : Trailer2AxleLoad_AxleId Trailer2AxleLoad_AxleLoad;
SIG_GROUP_ 2566885643 Trailer1AxleLoad_sg 1 : Trailer1AxleLoad_AxleId Trailer1AxleLoad_AxleLoad;
